VERSION ""

NS_ :

BS_:

BU_:
VAL_TABLE_ Sig0084 0 "2000" 1 "2001" 2 "2002" 3 "2003" 4 "2004" 5 "2005" 6 "2006" 7 "2007" 8 "2008" 9 "2009" 10 "2010" 11 "2011" 12 "2012" 13 "2013" 14 "2014" 15 "2015" 16 "2016" 17 "2017" 18 "2018" 19 "2019" 20 "2020" 21 "2021" 22 "2022" 23 "2023" 24 "2024" 25 "2025" 26 "2026" 27 "2027" 28 "2028" 29 "2029" 30 "2030" 31 "2031" 32 "2032" 33 "2033" 34 "2034" 35 "2035" 36 "2036" 37 "2037" 38 "2038" 39 "2039" 40 "2040" 41 "2041" 42 "2042" 43 "2043" 44 "2044" 45 "2045" 46 "2046" 47 "2047" 48 "2048" 49 "2049" 50 "2050" 51 "2051" 52 "2052" 53 "2053" 54 "2054" 55 "2055" 56 "2056" 57 "2057" 58 "2058" 59 "2059" 60 "2060" 61 "2061" 62 "2062" 63 "NOT APPLICABLE" ;
VAL_TABLE_ Sig0079 0 "UNKNOWN" 1 "<= 5 KM/H [MPH]" 2 "7 KM/H [MPH]" 3 "10 KM/H [MPH]" 4 "15 KM/H [MPH]" 5 "20 KM/H [MPH]" 6 "25 KM/H [MPH]" 7 "30 KM/H [MPH]" 8 "35 KM/H [MPH]" 9 "40 KM/H [MPH]" 10 "45 KM/H [MPH]" 11 "50 KM/H [MPH]" 12 "55 KM/H [MPH]" 13 "60 KM/H" 14 "MPH]65 KM/H [MPH]" 15 "70 KM/H [MPH]" 16 "75 KM/H [MPH]" 17 "80 KM/H [MPH]" 18 "85 KM/H [MPH]" 19 "90 KM/H [MPH]" 20 "95 KM/H [MPH]" 21 "100 KM/H [MPH]" 22 "105 KM/H [MPH]" 23 "110 KM/H [MPH]" 24 "115 KM/H [MPH]" 25 "120 KM/H[MPH]" 26 "130 KM/H [MPH]" 27 "140 KM/H [MPH]" 28 "150 KM/H [MPH]" 29 "160 KM/H [MPH]" 30 "UNLIMITED" 31 "NOT AVAILABLE" ;
VAL_TABLE_ Sig0078 0 "> 130 KPH OR > 80 MPH" 1 "101-130 KPH OR 65\???80 MPH" 2 "91-100 KPH OR 55\???64 MPH" 3 "71-90 KPH OR 41\???54 MPH" 4 "51-70 KPH OR 31\???40 MPH" 5 "31-50 KPH OR 21\???30 MPH" 6 "11-30 KPH OR 6 \???20 MPH" 7 "<11 KPH OR < 6 MPH" 8 "UNKNOWN" ;
VAL_TABLE_ Sig0083 0 "QUARTER 1" 1 "QUARTER 2" 2 "QUARTER 3" 3 "QUARTER 4" ;
VAL_TABLE_ ADASIS_NAVILINK_FncRdClss 0 "LOCAL" 1 "SFREEWAY" 2 "FREEWAY" 3 "PED-MALL" 4 "HIGHWAY" 5 "ARTERIAL" 6 "ALLEY" 7 "COLLECTOR" ;
VAL_TABLE_ Sig0081 0 "IMPLICIT" 1 "ON TRAFFIC SIGN" 2 "ONLY BY NIGHT" 3 "ONLY BY DAY" 4 "TIME OF DAY" 5 "ONLY BY RAIN" 6 "ONLY BY SNOW OR FOG" 7 "UNKOWN" ;
VAL_TABLE_ Sig0090 0 "ROAD IS NOT CONTROLLED ACCESS ROAD" 1 "ROAD IS CONTROLLED ACCESS ROAD" ;
VAL_TABLE_ Sig0089 0 "MILES/H" 1 "KM/H" ;
VAL_TABLE_ ADASIS_NAVILINK_MpDtAv 0 "NOT VALID" 1 "VALID" ;
VAL_TABLE_ Sig0082 0 "NOT ASSURED" 1 "ASSURED" ;
VAL_TABLE_ Sig0080 0 "DRIVING SIDE LEFT" 1 "DRIVING SIDE RIGHT" ;
VAL_TABLE_ Sig0085 0 "NO INFO AVAILABLE" 1 "ONE LANE" 2 "TWO OR THREE LANES" 3 "FOUR OR MORE LANES" ;
VAL_TABLE_ HVWrlsChrgStopReqd 0 "FALSE" 1 "TRUE" ;
VAL_TABLE_ HVWrlsChrgWiFiConctSts 0 "Unknown" 1 "Connected" 2 "Lost" ;
VAL_TABLE_ HVWrlsChrgSysFltSts 0 "No Fault" 1 "Over Voltage" 2 "Under Voltage" 3 "Overload" 4 "Over Temperature" 5 "Lost of Wifi Communication" 6 "Lost of CAN Communication" ;
VAL_TABLE_ HVWrlsChrgLivngObjDtd 0 "FALSE" 1 "TRUE" ;
VAL_TABLE_ HVWrlsChrgFrgnObjDtd 0 "FALSE" 1 "TRUE" ;
VAL_TABLE_ HVWrlsChrgRctfrTemp_Inv 0 "FALSE" 1 "TRUE" ;
VAL_TABLE_ HVWrlsChrgVehCoilTempA_Inv 0 "FALSE" 1 "TRUE" ;
VAL_TABLE_ HVWrlsChrgVehCoilTempB_Inv 0 "FALSE" 1 "TRUE" ;
VAL_TABLE_ HVWrlsChrgIntopbltCkSts 0 "Unknown" 1 "Pass" 2 "Fail" ;
VAL_TABLE_ HVWrlsChrgIntopbltCkFldRsn 0 "None" 1 "Wrong Charging Protocol" 2 "Unidentified Equipment" ;
VAL_TABLE_ HVWrlsChrgACGridPwr_Inv 0 "FALSE" 1 "TRUE" ;
VAL_TABLE_ HVWrlsChrgDCOutCurr_Inv 0 "FALSE" 1 "TRUE" ;
VAL_TABLE_ HVWrlsChrgSysCurrLim_Inv 0 "FALSE" 1 "TRUE" ;
VAL_TABLE_ HVWrlsChrgDCOutVltg_Inv 0 "FALSE" 1 "TRUE" ;
VAL_TABLE_ HVWrlsChrgAlgnCkRespVal_Inv 0 "FALSE" 1 "TRUE" ;
VAL_TABLE_ HVWrlsChrgSysStat 0 "Wireless Charging Inactive" 1 "Wireless Charging Pairing" 2 "Wireless Charging Standby" 3 "Wireless Charging Ready" 4 "Wireless Charging" 5 "Wireless Charging Complete" 6 "Wireless Charging Terminated" ;
VAL_TABLE_ Sig3479 0 "TOWN" 1 "COUNTRY ROAD" 2 "MOTORWAY" 3 "RESERVED1" 4 "RESERVED2" 5 "RESERVED3" 6 "RESERVED 4" 7 "UNDEFINED" ;
VAL_TABLE_ Sig3477 0 "UNKNOWN" 1 "NOT BLOCKED" 2 "FULL BLOCKAGE" 3 "PARTIAL BLOCKAGE" 4 "RESERVED3" 5 "RESERVED4" 6 "RESERVED5" 7 "RESERVED6" ;
VAL_TABLE_ Sig3476 0 "CLEAR WEATHER" 1 "LIGHT FOG" 2 "MEDIUM FOG" 3 "HEAVY FOG" 4 "LIGHT SNOW" 5 "MEDIUM SNOW" 6 "HEAVY SNOW" 7 "LIGHT RAIN" 8 "MEDIUM RAIN" 9 "HEAVY RAIN" ;
VAL_TABLE_ Sig3508 0 "OFF" 1 "AHBA" 2 "GFHB" ;
VAL_TABLE_ Sig3478 0 "UNKNOWN" 1 "LIT ENVIRONMENT DURING NIGHT" 2 "UNLIT ENVIRONMENT DURING NIGHT" 3 "DAYLIGHT" ;
VAL_TABLE_ Sig7678 0 "FALSE" 1 "TRUE" ;
VAL_TABLE_ Sig7675 0 "FALSE" 1 "TRUE" ;
VAL_TABLE_ Sig7674 0 "FALSE" 1 "TRUE" ;
VAL_TABLE_ Sig7673 0 "FALSE" 1 "TRUE" ;
VAL_TABLE_ Sig7672 0 "FALSE" 1 "TRUE" ;
VAL_TABLE_ Sig7671 0 "FALSE" 1 "TRUE" ;
VAL_TABLE_ Sig7670 0 "FALSE" 1 "TRUE" ;
VAL_TABLE_ Sig7669 0 "FALSE" 1 "TRUE" ;
VAL_TABLE_ Sig7686 0 "FALSE" 1 "TRUE" ;
VAL_TABLE_ Sig7685 0 "FALSE" 1 "TRUE" ;
VAL_TABLE_ Sig7684 0 "FALSE" 1 "TRUE" ;
VAL_TABLE_ Sig7683 0 "FALSE" 1 "TRUE" ;
VAL_TABLE_ Sig7682 0 "FALSE" 1 "TRUE" ;
VAL_TABLE_ Sig7681 0 "FALSE" 1 "TRUE" ;
VAL_TABLE_ Sig7680 0 "FALSE" 1 "TRUE" ;
VAL_TABLE_ TrfcSgnMemOfstEnbld 0 "FALSE" 1 "TRUE" ;
VAL_TABLE_ Sig7698 0 "FALSE" 1 "TRUE" ;
VAL_TABLE_ Sig7697 0 "FALSE" 1 "TRUE" ;
VAL_TABLE_ Sig7696 0 "FALSE" 1 "TRUE" ;
VAL_TABLE_ Sig7695 0 "FALSE" 1 "TRUE" ;
VAL_TABLE_ Sig7694 0 "FALSE" 1 "TRUE" ;
VAL_TABLE_ Sig7693 0 "FALSE" 1 "TRUE" ;
VAL_TABLE_ Sig7692 0 "FALSE" 1 "TRUE" ;
VAL_TABLE_ Sig7688 0 "FALSE" 1 "TRUE" ;
VAL_TABLE_ Sig7699 0 "FALSE" 1 "TRUE" ;
VAL_TABLE_ Sig7687 0 "No Action" 1 "Off" 2 "On" ;
VAL_TABLE_ Sig7676 0 "No Action" 1 "Off" 2 "On" ;
VAL_TABLE_ Sig7667 0 "No Action" 1 "Off" 2 "On" ;
VAL_TABLE_ Sig7691 0 "No Action" 1 "Active" 2 "Cancel Chime" ;
VAL_TABLE_ Sig7689 0 "No Action" 1 "Active" 2 "Cancel Chime" ;
VAL_TABLE_ Sig7677 0 "Setting Unknown" 1 "Off" 2 "On" ;
VAL_TABLE_ Sig7668 0 "Setting Unknown" 1 "Off" 2 "On" ;
VAL_TABLE_ Sig7666 0 "Setting Unknown" 1 "Off" 2 "On" ;
VAL_TABLE_ Sig7690 0 "FALSE" 1 "TRUE" ;
VAL_TABLE_ Sig7679 0 "FALSE" 1 "TRUE" ;
VAL_TABLE_ ACCompNormLd_Inv 0 "FALSE" 1 "TRUE" ;
VAL_TABLE_ OutsdAmbtLgtLvl_Inv 0 "FALSE" 1 "TRUE" ;
VAL_TABLE_ OutsdAmbtLgtLvl_DuD 0 "FALSE" 1 "TRUE" ;
VAL_TABLE_ PFMinIdlBsRq 0 "NO IDLE BOOST REQUESTED" 1 "BOOST LEVEL 1" 2 "BOOST LEVEL 2" 3 "BOOST LEVEL 3" 4 "BOOST LEVEL 4(NEW REQUEST)" ;
VAL_TABLE_ StBltShfIntlkReqSts 0 "Driver Seatbelt Shift Interlock Active" 1 "Passenger Seatbelt Shift Interlock Active" 2 "Seatbelt Shift Interlock Inactive" 3 "Seatbelt Shift Interlock Override Expired" ;
VAL_TABLE_ LDWCtrlSwSts 0 "Not Pressed" 1 "Pressed" 2 "Fault" 3 "Unknown" ;
VAL_TABLE_ EE46ecGridVltgOvrrdPrty 0 "None" 1 "Low" 2 "Medium" 3 "High" ;
VAL_TABLE_ ACCompModReq 0 "Disengage Immediately" 1 "Disengage" 2 "Engage" 3 "No Action" ;
VAL_TABLE_ FOPPriGridOvrrdActv 0 "FALSE" 1 "TRUE" ;
VAL_TABLE_ EPMGridIsltnReqd 0 "FALSE" 1 "TRUE" ;
VAL_TABLE_ ClntCircPmpRq 0 "Off" 1 "On" ;
VAL_TABLE_ ClmtCtrlHtrEngRunRq 0 "No Action" 1 "Engine Run Requested" ;
VAL_TABLE_ BdyCtrlEmsRltMlfAtv 0 "FALSE" 1 "TRUE" ;
VAL_TABLE_ ACCmpsrFldOn 0 "FALSE" 1 "TRUE" ;
VAL_TABLE_ ACCmEngRunReq 0 "No Action" 1 "Engine Run Requested" ;
VAL_TABLE_ PlatEngSpdCmdSysTyp 0 "No Platform Eng Speed Command Sys" 1 "Power Take Off" 2 "Reserved" ;
VAL_TABLE_ LdMeToCarActv 0 "FALSE" 1 "TRUE" ;
VAL_TABLE_ IBS12VBatCurrExtndRng_Inv 0 "FALSE" 1 "TRUE" ;
VAL_TABLE_ IBS12VEstdBatTemp_Inv 0 "FALSE" 1 "TRUE" ;
VAL_TABLE_ IBSIntrnlFltPr_Inv 0 "FALSE" 1 "TRUE" ;
VAL_TABLE_ IBSIntrnlFltPr 0 "FALSE" 1 "TRUE" ;
VAL_TABLE_ BCERDTC_SysDes 0 "P0_Powertrain Codes SAE Controlled" 1 "P1_Powertrain Codes MFG Controlled" 2 "P2_Powertrain Codes Reserved" 3 "P3_Powertrain Codes Reserved" 4 "C0_Chassis Codes SAE Controlled" 5 "C1_Chassis Codes MFG Controlled" 6 "C2_Chassis Codes Reserved" 7 "C3_Chassis Codes Reserved" 8 "B0_Body Codes SAE Controlled" 9 "B1_Body Codes MFG Controlled" 10 "B2_Body Codes Reserved" 11 "B3_Body Codes Reserved" 12 "U0_Network Codes SAE Controlled" 13 "U1_Network Codes MFG Controlled" 14 "U2_Network Codes Reserved" 15 "U3_Network Codes Reserved" ;
VAL_TABLE_ EngOffTmExtndRng_Inv 0 "FALSE" 1 "TRUE" ;
VAL_TABLE_ EnhdElpsdTmCntDgrd 0 "FALSE" 1 "TRUE" ;
VAL_TABLE_ ElpsdTimeCntRstOcc 0 "FALSE" 1 "TRUE" ;
VAL_TABLE_ TrnstStrgLogisticsMdActivation 0 "FALSE" 1 "TRUE" ;
VAL_TABLE_ RstrctdPwrtrnOpModeReqd 0 "FALSE" 1 "TRUE" ;
VAL_TABLE_ PrtctdIdlShftrLckReq 0 "FALSE" 1 "TRUE" ;
VAL_TABLE_ FgLmpFrtFncActv 0 "FALSE" 1 "TRUE" ;
VAL_TABLE_ ExtLgtChrgphyFrtActvn 0 "No Animation" 1 "Animation 1" 2 "Animation 2" 3 "Animation 3" 4 "Animation 4" 5 "Animation 5" 6 "Animation 6" ;
VAL_TABLE_ IBS12VBatVlt_Inv 0 "FALSE" 1 "TRUE" ;
VAL_TABLE_ BGI5_TrnLmpLtOtgDtd 0 "FALSE" 1 "TRUE" ;
VAL_TABLE_ BGI5_TrnLmpLtFncActv 0 "FALSE" 1 "TRUE" ;
VAL_TABLE_ BGI5_TrnLmpRtOtgDtd 0 "FALSE" 1 "TRUE" ;
VAL_TABLE_ BGI5_TrnLmpRtFncActv 0 "FALSE" 1 "TRUE" ;
VAL_TABLE_ PerfTracMgmtModeSwSts 0 "Not Supported" 1 "No Activation" 2 "Increment" 3 "Decrement" 4 "Faulted" ;
VAL_TABLE_ AirDflctrSysStat 0 "Unknown Position" 1 "Stowed Position" 2 "Drag Lowered Position" 3 "Drag Raised Position" 4 "Tow Haul Position" 5 "Brake Cooling Position" ;
VAL_TABLE_ PIMRI_BCM_PrmntDTCInd 0 "FALSE" 1 "TRUE" ;
VAL_TABLE_ PIMRI_BCM_FltsPrsntInd 0 "FALSE" 1 "TRUE" ;
VAL_TABLE_ LDWCtrlSelctdStatRaw 0 "PRESSED" 1 "NOT PRESSED" 2 "UNKNOWN" ;
VAL_TABLE_ DrvDrAjrStat 0 "FALSE" 1 "TRUE" ;
VAL_TABLE_ DrvDrAjrStat_Inv 0 "FALSE" 1 "TRUE" ;
VAL_TABLE_ AE44SeltdStatRw 0 "Not Pressed" 1 "Pressed" 2 "Unknown" 3 "Failed" ;
VAL_TABLE_ WshldWshFtrActv 0 "FALSE" 1 "TRUE" ;
VAL_TABLE_ WprFrActUnfltdStat 0 "FALSE" 1 "TRUE" ;
VAL_TABLE_ WprFrActFltdStat 0 "FALSE" 1 "TRUE" ;
VAL_TABLE_ EnhdDrvrSeltdMdSwChsUseActv 0 "FALSE" 1 "TRUE" ;
VAL_TABLE_ VehDynMdSwAct 0 "FALSE" 1 "TRUE" ;
VAL_TABLE_ VehDynMdSwAct_Inv 0 "FALSE" 1 "TRUE" ;
VAL_TABLE_ PerfTracMgmtActvnConfSts 0 "No Action" 1 "PTM Confirmed" 2 "Cancel PTM Request" ;
VAL_TABLE_ TrnSigSwRtActv 0 "FALSE" 1 "TRUE" ;
VAL_TABLE_ TrnSigSwLtActv 0 "FALSE" 1 "TRUE" ;
VAL_TABLE_ PrkBrkSwAtv 0 "FALSE" 1 "TRUE" ;
VAL_TABLE_ BrkLtsAtv 0 "FALSE" 1 "TRUE" ;
VAL_TABLE_ RatlzdEVDCCompVlvLSDCurrFbk_Inv 0 "FALSE" 1 "TRUE" ;
VAL_TABLE_ CustmModePwrtrnStrdPerfMode 0 "Unknown" 1 "Normal" 2 "Powertrain Sport" 3 "Chassis Sport" 4 "Eco" 5 "Mountain" 6 "Hold" 7 "Snow Ice" 8 "Start Stop" 9 "Tow Haul" 10 "Grade Braking Disabled" 11 "Speed Matching" 12 "Track" 13 "Exhaust Brake" 14 "Normal AWD" ;
VAL_TABLE_ PltfTrnsTUDSwSt 0 "No Activation" 1 "Increment Switch Active" 2 "Decrement Switch Active" 3 "Illegal Up/Down Switch State Active" ;
VAL_TABLE_ PltfTrnsTUDSecSwSt 0 "No Activation" 1 "Increment Switch Active" 2 "Decrement Switch Active" 3 "Illegal Up/Down Switch State Active" ;
VAL_TABLE_ LIBCfg 0 "Not supported" 1 "LIB1" 2 "LIB2" ;
VAL_TABLE_ ShftFrmPrkAlwd 0 "FALSE" 1 "TRUE" ;
VAL_TABLE_ DrvrElecVehModeCmnd 0 "FALSE" 1 "TRUE" ;
VAL_TABLE_ DM1Unavailable 0 "FALSE" 1 "TRUE" ;
VAL_TABLE_ DM1Status 0 "Inactive" 1 "Active" ;
VAL_TABLE_ DM1Pending 0 "FALSE" 1 "TRUE" ;
VAL_TABLE_ DM1Name 0 "None" 1 "Tour" 2 "Sport" 3 "Track" 4 "Winter" 5 "Off Road" 6 "Tow/Haul" 7 "Hold" 8 "Mountain" 9 "Personal" 10 "Custom" 11 "AWD" 12 "Economy" 13 "Automatic" 14 "EV" 15 "grade braking" 16 "exhaust brake" 17 "active rev match" 18 "2WD" 19 "Comfort" 20 "start/stop disable" 21 "Crawl" 22 "Charge Plus" 23 "Baja" 24 "Max Power" 25 "Reserved 1 - Reserved 7" ;
VAL_TABLE_ DM2Unavailable 0 "FALSE" 1 "TRUE" ;
VAL_TABLE_ DM2Status 0 "Inactive" 1 "Active" ;
VAL_TABLE_ DM2Pending 0 "FALSE" 1 "TRUE" ;
VAL_TABLE_ DM2Name 0 "None" 1 "Tour" 2 "Sport" 3 "Track" 4 "Winter" 5 "Off Road" 6 "Tow/Haul" 7 "Hold" 8 "Mountain" 9 "Personal" 10 "Custom" 11 "AWD" 12 "Economy" 13 "Automatic" 14 "EV" 15 "grade braking" 16 "exhaust brake" 17 "active rev match" 18 "2WD" 19 "Comfort" 20 "start/stop disable" 21 "Crawl" 22 "Charge Plus" 23 "Baja" 24 "Max Power" 25 "Reserved 1 - Reserved 7" ;
VAL_TABLE_ DM3Unavailable 0 "FALSE" 1 "TRUE" ;
VAL_TABLE_ DM3Status 0 "Inactive" 1 "Active" ;
VAL_TABLE_ DM3Pending 0 "FALSE" 1 "TRUE" ;
VAL_TABLE_ DM3Name 0 "None" 1 "Tour" 2 "Sport" 3 "Track" 4 "Winter" 5 "Off Road" 6 "Tow/Haul" 7 "Hold" 8 "Mountain" 9 "Personal" 10 "Custom" 11 "AWD" 12 "Economy" 13 "Automatic" 14 "EV" 15 "grade braking" 16 "exhaust brake" 17 "active rev match" 18 "2WD" 19 "Comfort" 20 "start/stop disable" 21 "Crawl" 22 "Charge Plus" 23 "Baja" 24 "Max Power" 25 "Reserved 1 - Reserved 7" ;
VAL_TABLE_ DM4Unavailable 0 "FALSE" 1 "TRUE" ;
VAL_TABLE_ DM4Status 0 "Inactive" 1 "Active" ;
VAL_TABLE_ DM4Pending 0 "FALSE" 1 "TRUE" ;
VAL_TABLE_ DM4Name 0 "None" 1 "Tour" 2 "Sport" 3 "Track" 4 "Winter" 5 "Off Road" 6 "Tow/Haul" 7 "Hold" 8 "Mountain" 9 "Personal" 10 "Custom" 11 "AWD" 12 "Economy" 13 "Automatic" 14 "EV" 15 "grade braking" 16 "exhaust brake" 17 "active rev match" 18 "2WD" 19 "Comfort" 20 "start/stop disable" 21 "Crawl" 22 "Charge Plus" 23 "Baja" 24 "Max Power" 25 "Reserved 1 - Reserved 7" ;
VAL_TABLE_ DM5Unavailable 0 "FALSE" 1 "TRUE" ;
VAL_TABLE_ DM5Status 0 "Inactive" 1 "Active" ;
VAL_TABLE_ DM5Pending 0 "FALSE" 1 "TRUE" ;
VAL_TABLE_ DM5Name 0 "None" 1 "Tour" 2 "Sport" 3 "Track" 4 "Winter" 5 "Off Road" 6 "Tow/Haul" 7 "Hold" 8 "Mountain" 9 "Personal" 10 "Custom" 11 "AWD" 12 "Economy" 13 "Automatic" 14 "EV" 15 "grade braking" 16 "exhaust brake" 17 "active rev match" 18 "2WD" 19 "Comfort" 20 "start/stop disable" 21 "Crawl" 22 "Charge Plus" 23 "Baja" 24 "Max Power" 25 "Reserved 1 - Reserved 7" ;
VAL_TABLE_ DM6Unavailable 0 "FALSE" 1 "TRUE" ;
VAL_TABLE_ DM6Status 0 "Inactive" 1 "Active" ;
VAL_TABLE_ DM6Pending 0 "FALSE" 1 "TRUE" ;
VAL_TABLE_ DM6Name 0 "None" 1 "Tour" 2 "Sport" 3 "Track" 4 "Winter" 5 "Off Road" 6 "Tow/Haul" 7 "Hold" 8 "Mountain" 9 "Personal" 10 "Custom" 11 "AWD" 12 "Economy" 13 "Automatic" 14 "EV" 15 "grade braking" 16 "exhaust brake" 17 "active rev match" 18 "2WD" 19 "Comfort" 20 "start/stop disable" 21 "Crawl" 22 "Charge Plus" 23 "Baja" 24 "Max Power" 25 "Reserved 1 - Reserved 7" ;
VAL_TABLE_ DM7Unavailable 0 "FALSE" 1 "TRUE" ;
VAL_TABLE_ DM7Status 0 "Inactive" 1 "Active" ;
VAL_TABLE_ DM7Pending 0 "FALSE" 1 "TRUE" ;
VAL_TABLE_ DM7Name 0 "None" 1 "Tour" 2 "Sport" 3 "Track" 4 "Winter" 5 "Off Road" 6 "Tow/Haul" 7 "Hold" 8 "Mountain" 9 "Personal" 10 "Custom" 11 "AWD" 12 "Economy" 13 "Automatic" 14 "EV" 15 "grade braking" 16 "exhaust brake" 17 "active rev match" 18 "2WD" 19 "Comfort" 20 "start/stop disable" 21 "Crawl" 22 "Charge Plus" 23 "Baja" 24 "Max Power" 25 "Reserved 1 - Reserved 7" ;
VAL_TABLE_ DM8Unavailable 0 "FALSE" 1 "TRUE" ;
VAL_TABLE_ DM8Status 0 "Inactive" 1 "Active" ;
VAL_TABLE_ DM8Pending 0 "FALSE" 1 "TRUE" ;
VAL_TABLE_ DM8Name 0 "None" 1 "Tour" 2 "Sport" 3 "Track" 4 "Winter" 5 "Off Road" 6 "Tow/Haul" 7 "Hold" 8 "Mountain" 9 "Personal" 10 "Custom" 11 "AWD" 12 "Economy" 13 "Automatic" 14 "EV" 15 "grade braking" 16 "exhaust brake" 17 "active rev match" 18 "2WD" 19 "Comfort" 20 "start/stop disable" 21 "Crawl" 22 "Charge Plus" 23 "Baja" 24 "Max Power" 25 "Reserved 1 - Reserved 7" ;
VAL_TABLE_ BatVlt_Inv 0 "FALSE" 1 "TRUE" ;
VAL_TABLE_ BattCrntFltrd_Inv 0 "FALSE" 1 "TRUE" ;
VAL_TABLE_ BattCrntFltrd_DuD 0 "FALSE" 1 "TRUE" ;
VAL_TABLE_ Sig4411 0 "FALSE" 1 "TRUE" ;
VAL_TABLE_ NodeStsADIMb_CAN_9_LcFA 0 "FALSE" 1 "TRUE" ;
VAL_TABLE_ NodeStsADIMb_CAN_3_LcFA 0 "FALSE" 1 "TRUE" ;
VAL_TABLE_ NodeStsADIMb_CAN_2_LcFA 0 "FALSE" 1 "TRUE" ;
VAL_TABLE_ NodeStsADIMb_CAN_10_LcFA 0 "FALSE" 1 "TRUE" ;
VAL_TABLE_ NodeStsADIMa_CAN_9_LcFA 0 "FALSE" 1 "TRUE" ;
VAL_TABLE_ NodeStsADIMa_CAN_3_LcFA 0 "FALSE" 1 "TRUE" ;
VAL_TABLE_ NodeStsADIMa_CAN_2_LcFA 0 "FALSE" 1 "TRUE" ;
VAL_TABLE_ NodeStsADIMa_CAN_10_LcFA 0 "FALSE" 1 "TRUE" ;
VAL_TABLE_ NodeStsAE44_CAN_1_LcFA 0 "FALSE" 1 "TRUE" ;
VAL_TABLE_ NodeStsE5_LcFA 0 "FALSE" 1 "TRUE" ;
VAL_TABLE_ NodeStsAMP_LcFA 0 "FALSE" 1 "TRUE" ;
VAL_TABLE_ NodeStsALC_LcFA 0 "FALSE" 1 "TRUE" ;
VAL_TABLE_ NodeStsAHS_LcFA 0 "FALSE" 1 "TRUE" ;
VAL_TABLE_ NodeStsAHL_AFL_CAN_2_LcFA 0 "FALSE" 1 "TRUE" ;
VAL_TABLE_ NodeStsAGC_LcFA 0 "FALSE" 1 "TRUE" ;
VAL_TABLE_ NodeStsBSM_MH_LcFA 0 "FALSE" 1 "TRUE" ;
VAL_TABLE_ NodeStsBSM_CAN_3_LcFA 0 "FALSE" 1 "TRUE" ;
VAL_TABLE_ NodeStsBSM_CAN_2_LcFA 0 "FALSE" 1 "TRUE" ;
VAL_TABLE_ NodeStsBCM_LcFA 0 "FALSE" 1 "TRUE" ;
VAL_TABLE_ NodeStsARS_LcFA 0 "FALSE" 1 "TRUE" ;
VAL_TABLE_ NodeStsE8_LcFA 0 "FALSE" 1 "TRUE" ;
VAL_TABLE_ NodeStsAE44_CAN_2_LcFA 0 "FALSE" 1 "TRUE" ;
VAL_TABLE_ NodeStsEBCM_AV_CAN_2_LcFA 0 "FALSE" 1 "TRUE" ;
VAL_TABLE_ NodeStsDMS_LcFA 0 "FALSE" 1 "TRUE" ;
VAL_TABLE_ NodeStsE12_LcFA 0 "FALSE" 1 "TRUE" ;
VAL_TABLE_ NodeStsDCM_LcFA 0 "FALSE" 1 "TRUE" ;
VAL_TABLE_ NodeStsCSM_CAN_5_LcFA 0 "FALSE" 1 "TRUE" ;
VAL_TABLE_ NodeStsECP_E_CAN_9_LcFA 0 "FALSE" 1 "TRUE" ;
VAL_TABLE_ NodeStsECP_E_CAN_2_LcFA 0 "FALSE" 1 "TRUE" ;
VAL_TABLE_ NodeStsECM_CAN_3_LcFA 0 "FALSE" 1 "TRUE" ;
VAL_TABLE_ NodeStsECM_CAN_2_LcFA 0 "FALSE" 1 "TRUE" ;
VAL_TABLE_ NodeStsEBCM_CAN_3_LcFA 0 "FALSE" 1 "TRUE" ;
VAL_TABLE_ NodeStsEBCM_CAN_2_LcFA 0 "FALSE" 1 "TRUE" ;
VAL_TABLE_ NodeStsEBCM_AV_CAN_3_LcFA 0 "FALSE" 1 "TRUE" ;
VAL_TABLE_ NodeStsEOCM_CAN_3_LcFA 0 "FALSE" 1 "TRUE" ;
VAL_TABLE_ NodeStsEOCM_CAN_2_LcFA 0 "FALSE" 1 "TRUE" ;
VAL_TABLE_ NodeStsELM_LcFA 0 "FALSE" 1 "TRUE" ;
VAL_TABLE_ NodeStsECP_X1_CAN_3_LcFA 0 "FALSE" 1 "TRUE" ;
VAL_TABLE_ NodeStsECP_X1_CAN_2_LcFA 0 "FALSE" 1 "TRUE" ;
VAL_TABLE_ NodeStsECP_S_CAN_9_LcFA 0 "FALSE" 1 "TRUE" ;
VAL_TABLE_ NodeStsECP_S_CAN_2_LcFA 0 "FALSE" 1 "TRUE" ;
VAL_TABLE_ NodeStsECP_MC_LcFA 0 "FALSE" 1 "TRUE" ;
VAL_TABLE_ NodeStsEPSRAa_LcFA 0 "FALSE" 1 "TRUE" ;
VAL_TABLE_ NodeStsEPS_LcFA 0 "FALSE" 1 "TRUE" ;
VAL_TABLE_ NodeStsE19_LcFA 0 "FALSE" 1 "TRUE" ;
VAL_TABLE_ NodeStsEOCM_HCP2_LcFA 0 "FALSE" 1 "TRUE" ;
VAL_TABLE_ NodeStsEOCM_HCP1_CAN_8_LcFA 0 "FALSE" 1 "TRUE" ;
VAL_TABLE_ NodeStsEOCM_HCP1_CAN_3_LcFA 0 "FALSE" 1 "TRUE" ;
VAL_TABLE_ NodeStsEOCM_HCP1_CAN_2_LcFA 0 "FALSE" 1 "TRUE" ;
VAL_TABLE_ NodeStsEOCM_CAN_8_LcFA 0 "FALSE" 1 "TRUE" ;
VAL_TABLE_ NodeStsHVAC_FP_F_LcFA 0 "FALSE" 1 "TRUE" ;
VAL_TABLE_ NodeStsHUD_CAN_LcFA 0 "FALSE" 1 "TRUE" ;
VAL_TABLE_ NodeStsE22_LcFA 0 "FALSE" 1 "TRUE" ;
VAL_TABLE_ NodeStsFOPM_CAN_3_LcFA 0 "FALSE" 1 "TRUE" ;
VAL_TABLE_ NodeStsFOPM_CAN_2_LcFA 0 "FALSE" 1 "TRUE" ;
VAL_TABLE_ NodeStsFCM_LcFA 0 "FALSE" 1 "TRUE" ;
VAL_TABLE_ NodeStsFCM_LC_LcFA 0 "FALSE" 1 "TRUE" ;
VAL_TABLE_ NodeStsE20_LcFA 0 "FALSE" 1 "TRUE" ;
VAL_TABLE_ NodeStsMFC_LcFA 0 "FALSE" 1 "TRUE" ;
VAL_TABLE_ NodeStsLRR_LcFA 0 "FALSE" 1 "TRUE" ;
VAL_TABLE_ NodeStsLIB1_LcFA 0 "FALSE" 1 "TRUE" ;
VAL_TABLE_ NodeStsIPC_CAN_5_LcFA 0 "FALSE" 1 "TRUE" ;
VAL_TABLE_ NodeStsICS_Info_LcFA 0 "FALSE" 1 "TRUE" ;
VAL_TABLE_ NodeStsICCM_CAN_3_LcFA 0 "FALSE" 1 "TRUE" ;
VAL_TABLE_ NodeStsHVAC_FP_R_LcFA 0 "FALSE" 1 "TRUE" ;
VAL_TABLE_ NodeStsE38_LcFA 0 "FALSE" 1 "TRUE" ;
VAL_TABLE_ NodeStsE37_LcFA 0 "FALSE" 1 "TRUE" ;
VAL_TABLE_ NodeStsE36_LcFA 0 "FALSE" 1 "TRUE" ;
VAL_TABLE_ NodeStsE35_LcFA 0 "FALSE" 1 "TRUE" ;
VAL_TABLE_ NodeStsE34_LcFA 0 "FALSE" 1 "TRUE" ;
VAL_TABLE_ NodeStsE33_LcFA 0 "FALSE" 1 "TRUE" ;
VAL_TABLE_ NodeStsE32_LcFA 0 "FALSE" 1 "TRUE" ;
VAL_TABLE_ NodeStsE31_LcFA 0 "FALSE" 1 "TRUE" ;
VAL_TABLE_ NodeStsRDCM_LcFA 0 "FALSE" 1 "TRUE" ;
VAL_TABLE_ NodeStsRadioLow_LcFA 0 "FALSE" 1 "TRUE" ;
VAL_TABLE_ NodeStsE48_LcFA 0 "FALSE" 1 "TRUE" ;
VAL_TABLE_ NodeStsPDR_LcFA 0 "FALSE" 1 "TRUE" ;
VAL_TABLE_ NodeStsE44_LcFA 0 "FALSE" 1 "TRUE" ;
VAL_TABLE_ NodeStsNVM_LcFA 0 "FALSE" 1 "TRUE" ;
VAL_TABLE_ NodeStsE40_LcFA 0 "FALSE" 1 "TRUE" ;
VAL_TABLE_ NodeStsE39_LcFA 0 "FALSE" 1 "TRUE" ;
VAL_TABLE_ Sig4413 0 "FALSE" 1 "TRUE" ;
VAL_TABLE_ NodeStsE53_LcFA 0 "FALSE" 1 "TRUE" ;
VAL_TABLE_ NodeStsE52_LcFA 0 "FALSE" 1 "TRUE" ;
VAL_TABLE_ NodeStsE51_LcFA 0 "FALSE" 1 "TRUE" ;
VAL_TABLE_ NodeStsE50_LcFA 0 "FALSE" 1 "TRUE" ;
VAL_TABLE_ NodeStsSADS_LcFA 0 "FALSE" 1 "TRUE" ;
VAL_TABLE_ NodeStsRSC_LcFA 0 "FALSE" 1 "TRUE" ;
VAL_TABLE_ NodeStsSRR_RF_LcFA 0 "FALSE" 1 "TRUE" ;
VAL_TABLE_ NodeStsSRR_LR_CR_LcFA 0 "FALSE" 1 "TRUE" ;
VAL_TABLE_ NodeStsSRR_LF_LcFA 0 "FALSE" 1 "TRUE" ;
VAL_TABLE_ NodeStsSIB_LcFA 0 "FALSE" 1 "TRUE" ;
VAL_TABLE_ NodeStsSDM_LcFA 0 "FALSE" 1 "TRUE" ;
VAL_TABLE_ NodeStsE56_LcFA 0 "FALSE" 1 "TRUE" ;
VAL_TABLE_ NodeStsE55_LcFA 0 "FALSE" 1 "TRUE" ;
VAL_TABLE_ NodeStsE54_LcFA 0 "FALSE" 1 "TRUE" ;
VAL_TABLE_ NodeStsTCP_CAN_5_LcFA 0 "FALSE" 1 "TRUE" ;
VAL_TABLE_ NodeStsTCM_CAN_2_LcFA 0 "FALSE" 1 "TRUE" ;
VAL_TABLE_ NodeStsTCCM_LcFA 0 "FALSE" 1 "TRUE" ;
VAL_TABLE_ NodeStsE57_LcFA 0 "FALSE" 1 "TRUE" ;
VAL_TABLE_ NodeStsSRR_SRR_LcFA 0 "FALSE" 1 "TRUE" ;
VAL_TABLE_ NodeStsSRR_SLR_LcFA 0 "FALSE" 1 "TRUE" ;
VAL_TABLE_ NodeStsSRR_RR_LcFA 0 "FALSE" 1 "TRUE" ;
VAL_TABLE_ NodeStsWCM_LcFA 0 "FALSE" 1 "TRUE" ;
VAL_TABLE_ NodeStsE63_LcFA 0 "FALSE" 1 "TRUE" ;
VAL_TABLE_ NodeStsVLM_LcFA 0 "FALSE" 1 "TRUE" ;
VAL_TABLE_ NodeStsVKM_LcFA 0 "FALSE" 1 "TRUE" ;
VAL_TABLE_ NodeStsVICM_CAN_9_LcFA 0 "FALSE" 1 "TRUE" ;
VAL_TABLE_ NodeStsVICM_CAN_2_LcFA 0 "FALSE" 1 "TRUE" ;
VAL_TABLE_ NodeStsVCU_CAN_5_LcFA 0 "FALSE" 1 "TRUE" ;
VAL_TABLE_ NodeStsE60_LcFA 0 "FALSE" 1 "TRUE" ;
VAL_TABLE_ NodeStsECP_S2_CAN_2_LcFA 0 "FALSE" 1 "TRUE" ;
VAL_TABLE_ NodeStsE45_LcFA 0 "FALSE" 1 "TRUE" ;
VAL_TABLE_ NodeStsVDM_CAN_2_LcFA 0 "FALSE" 1 "TRUE" ;
VAL_TABLE_ NodeStsWE48_LcFA 0 "FALSE" 1 "TRUE" ;
VAL_TABLE_ NodeStsPCM_CAN_3_LcFA 0 "FALSE" 1 "TRUE" ;
VAL_TABLE_ NodeStsPCM_CAN_2_LcFA 0 "FALSE" 1 "TRUE" ;
VAL_TABLE_ NodeStsSDM_AV_LcFA 0 "FALSE" 1 "TRUE" ;
VAL_TABLE_ NodeStsACP2_MCU_CAN_8_LcFA 0 "FALSE" 1 "TRUE" ;
VAL_TABLE_ NodeStsACP2_MCU_CAN_2_LcFA 0 "FALSE" 1 "TRUE" ;
VAL_TABLE_ NodeStsVECM_CAN_2_LcFA 0 "FALSE" 1 "TRUE" ;
VAL_TABLE_ NodeStsVDM_CAN_9_LcFA 0 "FALSE" 1 "TRUE" ;
VAL_TABLE_ NodeStsE61_CAN_1_LcFA 0 "FALSE" 1 "TRUE" ;
VAL_TABLE_ NodeStsUPM_LcFA 0 "FALSE" 1 "TRUE" ;
VAL_TABLE_ NodeStsEPSb_LcFA 0 "FALSE" 1 "TRUE" ;
VAL_TABLE_ NodeStsSBM_CAN_10_LcFA 0 "FALSE" 1 "TRUE" ;
VAL_TABLE_ NodeStsVECM_CAN_9_LcFA 0 "FALSE" 1 "TRUE" ;
VAL_TABLE_ NodeStsECP_S2_CAN_9_LcFA 0 "FALSE" 1 "TRUE" ;
VAL_TABLE_ NodeStsCSM_AV_CAN_5_LcFA 0 "FALSE" 1 "TRUE" ;
VAL_TABLE_ NodeStsACP3_MCU_CAN_3_LcFA 0 "FALSE" 1 "TRUE" ;
VAL_TABLE_ NodeStsACP3_MCU_CAN_8_LcFA 0 "FALSE" 1 "TRUE" ;
VAL_TABLE_ NodeStsACP3_MCU_CAN_2_LcFA 0 "FALSE" 1 "TRUE" ;
VAL_TABLE_ FrtPsngrAirbagDsblVisIndCmd 0 "On" 1 "Off" 2 "Flash" ;
VAL_TABLE_ ORIP_EnvModPrsntRsp1Auth 0 "FALSE" 1 "TRUE" ;
VAL_TABLE_ ORIP_DrvrStBltStsAuth_Inv 0 "FALSE" 1 "TRUE" ;
VAL_TABLE_ ORIP_DrvrStBltStsAuth 0 "Unknown" 1 "UnFastened" 2 "Fastened" ;
VAL_TABLE_ RstrntSysFltPrsnt 0 "FALSE" 1 "TRUE" ;
VAL_TABLE_ FrtPsngrAirbagEnblVisIndCmd 0 "On" 1 "Off" 2 "Flash" ;
VAL_TABLE_ Sig4429 0 "FALSE" 1 "TRUE" ;
VAL_TABLE_ FE44RS_LtCntr 0 "OFF" 1 "FAILED" 2 "BLOCKED" 3 "ATTACHED_OBJECT" 4 "NO_OBJECT" 5 "ZONE_1" 6 "ZONE_2" 7 "ZONE_3" 8 "ZONE_4" 9 "ZONE_5" 10 "ZONE_6" 11 "OFF_NO_FAULT" 12 "RESERVED_1" 13 "RESERVED_2" 14 "RESERVED_3" ;
VAL_TABLE_ FE44RS_Lt 0 "OFF" 1 "FAILED" 2 "BLOCKED" 3 "ATTACHED_OBJECT" 4 "NO_OBJECT" 5 "ZONE_1" 6 "ZONE_2" 7 "ZONE_3" 8 "ZONE_4" 9 "ZONE_5" 10 "ZONE_6" 11 "OFF_NO_FAULT" 12 "RESERVED_1" 13 "RESERVED_2" 14 "RESERVED_3" ;
VAL_TABLE_ FE44RS_RtCntr 0 "OFF" 1 "FAILED" 2 "BLOCKED" 3 "ATTACHED_OBJECT" 4 "NO_OBJECT" 5 "ZONE_1" 6 "ZONE_2" 7 "ZONE_3" 8 "ZONE_4" 9 "ZONE_5" 10 "ZONE_6" 11 "OFF_NO_FAULT" 12 "RESERVED_1" 13 "RESERVED_2" 14 "RESERVED_3" ;
VAL_TABLE_ FE44RS_Rt 0 "OFF" 1 "FAILED" 2 "BLOCKED" 3 "ATTACHED_OBJECT" 4 "NO_OBJECT" 5 "ZONE_1" 6 "ZONE_2" 7 "ZONE_3" 8 "ZONE_4" 9 "ZONE_5" 10 "ZONE_6" 11 "OFF_NO_FAULT" 12 "RESERVED_1" 13 "RESERVED_2" 14 "RESERVED_3" ;
VAL_TABLE_ E44IM_FaildIndOn 0 "FALSE" 1 "TRUE" ;
VAL_TABLE_ E44IM_DsbldIndOn 0 "FALSE" 1 "TRUE" ;
VAL_TABLE_ E44VisObjIndStatReq 0 "No Action" 1 "Driver Tube Front" 2 "Driver Tube Rear" 3 "Full Active" ;
VAL_TABLE_ E44Rgn 0 "Europe" 1 "North America" ;
VAL_TABLE_ E44IM_TeenDrvrE44OffUnvIndOn 0 "FALSE" 1 "TRUE" ;
VAL_TABLE_ E44IM_SnsrDstbdIndOn 0 "FALSE" 1 "TRUE" ;
VAL_TABLE_ E44IM_SnsrClnIndOn 0 "FALSE" 1 "TRUE" ;
VAL_TABLE_ E44IM_SnsrBlckdIndOn 0 "FALSE" 1 "TRUE" ;
VAL_TABLE_ E44IM_RrOffIndOn 0 "FALSE" 1 "TRUE" ;
VAL_TABLE_ E44IM_OffIndOn 0 "FALSE" 1 "TRUE" ;
VAL_TABLE_ E44IM_FrtOffIndOn 0 "FALSE" 1 "TRUE" ;
VAL_TABLE_ PrkAsstActIndCmnd 0 "FALSE" 1 "TRUE" ;
VAL_TABLE_ PrkAsstStat 0 "OFF" 1 "STANDBY" 2 "DISABLED" 3 "FAILED" 4 "FRONT_REAR_ACTIVE" 5 "REAR_ACTIVE" 6 "FRONT_ACTIVE" 7 "UNKNOWN" ;
VAL_TABLE_ PGI3P_PrplCpbltyStsPriAuth 0 "Request Not Limited" 1 "Request Value Limited Minimum" 2 "Request Value Limited Maximum" 3 "Request Rate Limited" ;
VAL_TABLE_ PGI3P_PrplArbtrtnStsPriAuth 0 "No ADS data" 1 "ADS Active" 2 "Traction Active" 3 "Lost Axle Arbitration" ;
VAL_TABLE_ PGI3P_ADSRedntATReqStsPriAuth 0 "Unknown" 1 "Data Valid" 2 "Data Invalid" 3 "Serial Data Failure" ;
VAL_TABLE_ PGI3P_ADSMnAxlTrqReqStsPriAuth 0 "Unknown" 1 "Data Valid" 2 "Data Invalid" 3 "Serial Data Failure" ;
VAL_TABLE_ PrplSysFricBrkTrqReqTypAuth 0 "No Action" 1 "Braking Not Requested" 2 "Brake Per Torque Request" 3 "Hold" ;
VAL_TABLE_ PGI3P_PrplSysStsPriAuth 0 "Initialize" 1 "Full Function" 2 "Degraded Mode 1" 3 "Degraded Mode 2" 4 "Degraded Mode 3" 5 "Degraded Mode 4" 6 "Degraded Mode 5" ;
VAL_TABLE_ PCIP_HzrdLgtsOnReqdAuth 0 "FALSE" 1 "TRUE" ;
VAL_TABLE_ PCIP_HybVehHiVltgDsblReqdAuth 0 "FALSE" 1 "TRUE" ;
VAL_TABLE_ PCIP_HVCrshImpSnsSysDsbldAuth 0 "FALSE" 1 "TRUE" ;
VAL_TABLE_ PCIP_HVACBlwDsblReqdAuth 0 "FALSE" 1 "TRUE" ;
VAL_TABLE_ PCIP_FuelCutOffReqdAuth 0 "FALSE" 1 "TRUE" ;
VAL_TABLE_ PCIP_DrUnlckReqdAuth 0 "FALSE" 1 "TRUE" ;
VAL_TABLE_ PCIP_CruzCtlDsblReqdAuth 0 "FALSE" 1 "TRUE" ;
VAL_TABLE_ PCIP_BrkActReqdAuth 0 "FALSE" 1 "TRUE" ;
VAL_TABLE_ PCIP_NftnFrtImpPrtnsrSevAchAuth 0 "FALSE" 1 "TRUE" ;
VAL_TABLE_ PCIP_MemStRclDsblReqdAuth 0 "FALSE" 1 "TRUE" ;
VAL_TABLE_ PCIP_IntrLgtOnReqdAuth 0 "FALSE" 1 "TRUE" ;
VAL_TABLE_ PCIP_NtfnLtSdSevAchvdAuth 0 "FALSE" 1 "TRUE" ;
VAL_TABLE_ PCIP_NtfnFrtImpStg2SevAchvdAuth 0 "FALSE" 1 "TRUE" ;
VAL_TABLE_ PCIP_NtfnFrtImpStg1SevAchvdAuth 0 "FALSE" 1 "TRUE" ;
VAL_TABLE_ PCIP_NtfnEvntStsAuth 0 "No Event" 1 "Near Deploy Event" 2 "Deployment Event" ;
VAL_TABLE_ PCIP_eCallReqdAuth 0 "FALSE" 1 "TRUE" ;
VAL_TABLE_ PCIP_NtfnRtSdSevAchvdAuth 0 "FALSE" 1 "TRUE" ;
VAL_TABLE_ PCIP_NtfnRrImpSevAchvdAuth 0 "FALSE" 1 "TRUE" ;
VAL_TABLE_ PCIP_NtfnRlOvrSevAchvdAuth 0 "FALSE" 1 "TRUE" ;
VAL_TABLE_ PCIP_NtfnPedtrnPrtctnSevAchAuth 0 "FALSE" 1 "TRUE" ;
VAL_TABLE_ POFT_PstnOfstFrmTrmLF_Inv 0 "FALSE" 1 "TRUE" ;
VAL_TABLE_ POFT_PstnOfstFrmTrmLR_Inv 0 "FALSE" 1 "TRUE" ;
VAL_TABLE_ POFT_PstnOfstFrmTrmRF_Inv 0 "FALSE" 1 "TRUE" ;
VAL_TABLE_ POFT_PstnOfstFrmTrmRR_Inv 0 "FALSE" 1 "TRUE" ;
VAL_TABLE_ POFT_SpnsnTrmPstnLrnCmplt 0 "FALSE" 1 "TRUE" ;
VAL_TABLE_ PSIP_StrgAsstRdcdLvl3IndOnAuth 0 "FALSE" 1 "TRUE" ;
VAL_TABLE_ PSIP_StrgAsstRdcdLvl2IndOnAuth 0 "FALSE" 1 "TRUE" ;
VAL_TABLE_ PSIP_StrgAsstRdcdIndOnAuth 0 "FALSE" 1 "TRUE" ;
VAL_TABLE_ PSIP_PwrStrgIndOnAuth 0 "FALSE" 1 "TRUE" ;
VAL_TABLE_ Sig5023 0 "FALSE" 1 "TRUE" ;
VAL_TABLE_ SATCRTP_SecAxlTrqCplRqTyAuth 0 "No Action" 1 "Maximum Allowed Torque" 2 "Minimum Allowed Torque" 3 "Control to Requested Torque" ;
VAL_TABLE_ SAP_PwrtrnXferCaseModeAuth 0 "2 Wheel Drive High" 1 "4 Wheel Drive High" 2 "4 Wheel Drive Low" 3 "Neutral" ;
VAL_TABLE_ SAP_SecAxlOpMdAuth 0 "2WD High" 1 "4WD High Rigid Coupling" 2 "4WD Low Rigid Coupling" 3 "AWD Active Single Clutch" 4 "4WD High Active Clutch" 5 "4WD Low Active Clutch" 6 "AWD Active Twin Clutch" 7 "2WD Low" 8 "Unknown" 9 "Neutral" ;
VAL_TABLE_ SAP_SecAxl4WDAWDStatAuth 0 "Normal" 1 "Temporary_Limited" 2 "Temporary_Inhibit" 3 "Permanently_Failed" ;
VAL_TABLE_ SAP_SecAxl4WDAWDEstTrqAuth_Inv 0 "FALSE" 1 "TRUE" ;
VAL_TABLE_ SAP_XferCaseRngShfPndgAuth 0 "None" 1 "ShiftOutofHighRange" 2 "ShiftOutofLowRange" 3 "ShiftOutofNeutralRange" ;
VAL_TABLE_ SAP_SecAxlOpMdAuth_Inv 0 "FALSE" 1 "TRUE" ;
VAL_TABLE_ SADSVTSLP_VehTpSpdLimReqTypAuth 0 "Inactive" 1 "Faulted" 2 "Safety_woBrake" 3 "Safety_wBrake" 4 "OBD" 5 "nonOBD" 6 "Legislated" ;
VAL_TABLE_ SLVFSP_SpdLimVsnFsdSpdUntAuth 0 "km/h" 1 "mph" ;
VAL_TABLE_ SLVFSP_SpdLimVsnFsdSpdNwDtdAuth 0 "FALSE" 1 "TRUE" ;
VAL_TABLE_ SLVFSP_SpdLimVsnFsdSpdAuth_DuD 0 "FALSE" 1 "TRUE" ;
VAL_TABLE_ SGI2P_AirSpnsnRdHghtLwrActnAuth 0 "None" 1 "Slow" 2 "Medium (Exhaust)" 3 "Fast" ;
VAL_TABLE_ SGI2P_AirSpnsnRdHghtActvAxlAuth 0 "None" 1 "Front" 2 "Rear" 3 "Both" 4 "Pending" ;
VAL_TABLE_ SGI2P_AirSpnsnRdHghtActlStsAuth 0 "Faulted" 1 "Entry/Exit" 2 "Lowered 3(Stability)" 3 "Lowered 2 (Sport)" 4 "Lowered 1 (Aero)" 5 "Showroom" 6 "Normal" 7 "Raised 1" 8 "Raised 2" 9 "Raised 3" ;
VAL_TABLE_ SGI2P_AirSpnsnRdHghtTgtStsAuth 0 "Faulted" 1 "Entry/Exit" 2 "Lowered 3(Stability)" 3 "Lowered 2 (Sport)" 4 "Lowered 1 (Aero)" 5 "Showroom" 6 "Normal" 7 "Raised 1" 8 "Raised 2" 9 "Raised 3" ;
VAL_TABLE_ SGI2P_AirSpnsnRdHghtRseActnAuth 0 "None" 1 "Slow(i.e. compressor)" 2 "Medium (i.e. Boost)" 3 "Fast (i.e. Reservoir)" ;
VAL_TABLE_ UpftrSnwPlwModeActv_Inv 0 "FALSE" 1 "TRUE" ;
VAL_TABLE_ UpftrSnwPlwModeActv 0 "FALSE" 1 "TRUE" ;
VAL_TABLE_ UpftrSnwPlwHdlmpsActv 0 "FALSE" 1 "TRUE" ;
VAL_TABLE_ UpftrLckReq 0 "No Request" 1 "Lock All" 2 "Unlock All" ;
VAL_TABLE_ UpftrAutoShtdnInhbReqd 0 "FALSE" 1 "TRUE" ;
VAL_TABLE_ UpftrAllWndMtnReq 0 "No Request" 1 "Open Fully" 2 "Open Vent" 3 "Close Fully" ;
VAL_TABLE_ UpftrVehRmtStrtupReq 0 "No Request" 1 "Engine Requested Off" 2 "Engine Requested On" ;
VAL_TABLE_ HVGI1P_PrplRltdBsHVAllwdPriAuth 0 "FALSE" 1 "TRUE" ;
VAL_TABLE_ HVGI1P_HVBatCntctrStsPriAuth 0 "Open" 1 "Precharge" 2 "Close" ;
VAL_TABLE_ HVGI1P_CntctrShtdnReqPriAuth 0 "None" 1 "Emergency Shutdown" 2 "Controlled Shutdown" 3 "Emergency Crash Shutdown" ;
VAL_TABLE_ ElcDischrgActr2DischrgCmdAuth 0 "NoAction" 1 "Normal" 2 "Immediate" 3 "Emergency" ;
VAL_TABLE_ HVGI7P_ESSPrplSysStsPriAuth 0 "Unavailable" 1 "Operational" 2 "ControlledShutdown" 3 "EmergencyShutdown" 4 "EmergencyCrash" 5 "Suspend Request" ;
VAL_TABLE_ HVGI7P_ESSPrplSysRespPriAuth 0 "Idle" 1 "Activating" 2 "Active" 3 "Deactivating" ;
VAL_TABLE_ VirtKeyAllDrLckReqd 0 "FALSE" 1 "TRUE" ;
VAL_TABLE_ VirtKeyPncReq 0 "No Request" 1 "Activate" 2 "Cancel" ;
VAL_TABLE_ VirtKeyFobAvlReq 0 "No Request" 1 "Enable Fobs" 2 "Disable Fobs" ;
VAL_TABLE_ VirtKeyRmtLctrReq 0 "No Request" 1 "Activate Low" 2 "Activate Medium" 3 "Activate High" 4 "Cancel" ;
VAL_TABLE_ SRPCrsFrtInSftBtnMblDevSts 0 "Not Pressed" 1 "Pressed" ;
VAL_TABLE_ SRPCrsBkInSftBtnMblDevSts 0 "Not Pressed" 1 "Pressed" ;
VAL_TABLE_ VirtKeyRrClsrUnlckReqd 0 "FALSE" 1 "TRUE" ;
VAL_TABLE_ VirtKeyRrClsrLckReqd 0 "FALSE" 1 "TRUE" ;
VAL_TABLE_ VirtKeyFrtClsrUnlckReqd 0 "FALSE" 1 "TRUE" ;
VAL_TABLE_ VirtKeyFrtClsrLckReqd 0 "FALSE" 1 "TRUE" ;
VAL_TABLE_ VirtKeyDrvrDrUnlckReqd 0 "FALSE" 1 "TRUE" ;
VAL_TABLE_ VirtKeyAllDrUnlckReqd 0 "FALSE" 1 "TRUE" ;
VAL_TABLE_ SRPSrchingSftBtnMblDevSts 0 "Not Pressed" 1 "Pressed" ;
VAL_TABLE_ SRPRtSftBtnMblDevSts 0 "Not Pressed" 1 "Pressed" ;
VAL_TABLE_ SRPPrlllPrkSftBtnMblDevSts 0 "Not Pressed" 1 "Pressed" ;
VAL_TABLE_ SRPLtSftBtnMblDevSts 0 "Not Pressed" 1 "Pressed" ;
VAL_TABLE_ SRPExtPrkSftBtnMblDevSts 0 "Not Pressed" 1 "Pressed" ;
VAL_TABLE_ VirtKeyPwrTopCtlReqrMblDevIdfr 0 "Unknown" 1 "Mobile Device Identifier 1" 2 "Mobile Device Identifier 2" 3 "Mobile Device Identifier 3" 4 "Mobile Device Identifier 4" 5 "Mobile Device Identifier 5" 6 "Mobile Device Identifier 6" 7 "Mobile Device Identifier 7" 8 "Mobile Device Identifier 8" 9 "Mobile Device Identifier 9" 10 "Mobile Device Identifier 10" 11 "Mobile Device Identifier 11" 12 "Mobile Device Identifier 12" 13 "Mobile Device Identifier 13" 14 "Mobile Device Identifier 14" 15 "Mobile Device Identifier 15" ;
VAL_TABLE_ VirtKeyPwrTopCtlReq 0 "No Request" 1 "Open" 2 "Close" 3 "Stop" 4 "Pause" ;
VAL_TABLE_ VirtKeyPwrRrClsrCtlReq 0 "No Request" 1 "Start" 2 "Stop" 3 "Open" 4 "Close" ;
VAL_TABLE_ VirtKeyFrtClsrCtlReq 0 "No Request" 1 "Start" 2 "Stop" 3 "Release" 4 "Open" 5 "Close" ;
VAL_TABLE_ VirtKeyWndCtlReq 0 "No Request" 1 "Open Fully" 2 "Vent" 3 "Close Fully" ;
VAL_TABLE_ VirtKeyVehCbnACReq 0 "No Request" 1 "Activate" 2 "Cancel" ;
VAL_TABLE_ VirtKeySnrfCtlReq 0 "No Request" 1 "Open Fully" 2 "Vent" 3 "Close Fully" ;
VAL_TABLE_ SRPMblDevDctvBtnSts 0 "Not Pressed" 1 "Pressed" ;
VAL_TABLE_ VirtKeyVehCbnACTempLvlReqActv 0 "FALSE" 1 "TRUE" ;
VAL_TABLE_ VirtKeyRrClsrRelReqd 0 "FALSE" 1 "TRUE" ;
VAL_TABLE_ ElecDrvUnt3DrvUntPrplSecSts 0 "Inactive" 1 "Active" 2 "Transitional" ;
VAL_TABLE_ ElecDrvUnt2DrvUntPrplSecSts 0 "Inactive" 1 "Active" 2 "Transitional" ;
VAL_TABLE_ ElecDrvUnt3DrvUntPrplSecCmd 0 "Disable" 1 "Enable" ;
VAL_TABLE_ ElecDrvUnt2DrvUntPrplSecCmd 0 "Disable" 1 "Enable" ;
VAL_TABLE_ ACRefrigLoSdFPSCktFABndl 0 "FALSE" 1 "TRUE" ;
VAL_TABLE_ ACRefrigLoSdFldPrsVal_Inv 0 "FALSE" 1 "TRUE" ;
VAL_TABLE_ HVGI11_PwrElecCoolLoopTemp_Inv 0 "FALSE" 1 "TRUE" ;
VAL_TABLE_ HVGI11_PwrElecCoolLoopTemp_DuD 0 "FALSE" 1 "TRUE" ;
VAL_TABLE_ AltTxPrplSysOffTm_Inv 0 "FALSE" 1 "TRUE" ;
VAL_TABLE_ AltTxPrplSysOffTm_DuD 0 "FALSE" 1 "TRUE" ;
VAL_TABLE_ SuprRmtPrkFricBrkTrqReqTyp 0 "No Action" 1 "Braking Not Requested" 2 "Brake Per Torque" 3 "Hold" ;
VAL_TABLE_ SuprRmtPrkElecPrkBrkReq 0 "No Request" 1 "Apply" 2 "Release" ;
VAL_TABLE_ SuprRmtPrkPrplSysActvnReqd 0 "FALSE" 1 "TRUE" ;
VAL_TABLE_ ClmCtlCbnMaxDefrReqOn_Inv 0 "FALSE" 1 "TRUE" ;
VAL_TABLE_ ClmCtlCbnMaxDefrReqOn 0 "FALSE" 1 "TRUE" ;
VAL_TABLE_ ClmCtlCbnFrtRtTempSet_Inv 0 "FALSE" 1 "TRUE" ;
VAL_TABLE_ ClmCtlCbnFrtLtTempSet_Inv 0 "FALSE" 1 "TRUE" ;
VAL_TABLE_ ClmCtlCbnEvpAirOutTemp_Inv 0 "FALSE" 1 "TRUE" ;
VAL_TABLE_ BSIR2P_BrkgSysVhTpSpLmRqTypAuth 0 "Inactive" 1 "OBD" ;
VAL_TABLE_ BSIR2P_BSPriVehTpSpLimRqTypAuth 0 "Inactive" 1 "Faulted" 2 "Safety_woBrake" 3 "Safety_wBrake" 4 "OBD" 5 "nonOBD" 6 "Legislated" ;
VAL_TABLE_ BSIR2P_BSPriVehTpSpLimRqSrcAuth 0 "None" 1 "eBoost" 2 "ESC" ;
VAL_TABLE_ BSISP_ESCActvAuth 0 "FALSE" 1 "TRUE" ;
VAL_TABLE_ BSISP_TCSFaildAuth 0 "FALSE" 1 "TRUE" ;
VAL_TABLE_ BSISP_TCSDrvrIntntAuth 0 "Disabled" 1 "Enabled" ;
VAL_TABLE_ BSISP_TCSActvAuth 0 "FALSE" 1 "TRUE" ;
VAL_TABLE_ BSISP_ETRSHydrlcBrkgStsAuth 0 "Not Active" 1 "Active" 2 "Failed" ;
VAL_TABLE_ BSISP_ESCSysStsAuth 0 "Normal Operation" 1 "Failed" 2 "Initializing" 3 "Enhanced Operation" 4 "Driver Disable" ;
VAL_TABLE_ DMCP_VehSpdLimFricBrkStsAuth 0 "Inactive" 1 "Active" 2 "Not available" ;
VAL_TABLE_ DMCP_AWDPerfModeReqAuth 0 "No Action" 1 "Normal" 2 "Sport" 3 "Track/Baja" 4 "Winter" 5 "Off Road" 6 "Terrain" 7 "Disconnect" ;
VAL_TABLE_ BrkgSysVehTopSpdLimIndOnAuth 0 "FALSE" 1 "TRUE" ;
VAL_TABLE_ EPBSP_ElecPrkBrkAvlStsAuth 0 "Unavailable" 1 "Available" 2 "Failed" ;
VAL_TABLE_ EPBSP_ElecPrkBrkApplStsAuth 0 "Unknown" 1 "Applied" 2 "Released" 3 "Dynamic Apply" 4 "In-Progress" ;
VAL_TABLE_ EPBSP_EPBSysBrkLgtsReqdAuth 0 "FALSE" 1 "TRUE" ;
VAL_TABLE_ EPBSP_BrkSysBrkLgtsReqdAuth 0 "FALSE" 1 "TRUE" ;
VAL_TABLE_ DMCP_EnvIdRsp2Auth 0 "FALSE" 1 "TRUE" ;
VAL_TABLE_ TBIP_TrlrBrkDsbldIndOnAuth 0 "FALSE" 1 "TRUE" ;
VAL_TABLE_ TBIP_ServTrlrBrkgSysIndOnAuth 0 "FALSE" 1 "TRUE" ;
VAL_TABLE_ TBIP_CkTrlrIndOnAuth 0 "FALSE" 1 "TRUE" ;
VAL_TABLE_ EPBSP_TrlrBrkgSysBrkLgtsRqdAuth 0 "FALSE" 1 "TRUE" ;
VAL_TABLE_ TBIP_TrlrWrgFltIndOnAuth 0 "FALSE" 1 "TRUE" ;
VAL_TABLE_ TBIP_TrlrBrkgGainSetIndOnAuth 0 "FALSE" 1 "TRUE" ;
VAL_TABLE_ ElecPrkBrkMnPriPerfRdcd 0 "FALSE" 1 "TRUE" ;
VAL_TABLE_ TrlrBrkgRdcdIndOn 0 "FALSE" 1 "TRUE" ;
VAL_TABLE_ TrlrBrkgHldLstKnwnGainIndOn 0 "FALSE" 1 "TRUE" ;
VAL_TABLE_ AASILASStrgReqLnFllwgRrStrgInhb 0 "FALSE" 1 "TRUE" ;
VAL_TABLE_ AASILASStrgReqSts 0 "Unknown" 1 "Active" 2 "Inactive" ;
VAL_TABLE_ AASILASStrgReqAFtr 0 "None" 1 "Collision Avoidance Steeering" 2 "Traffic Jam Assist" 3 "Lane Centering and Control" 4 "Hands-On Lane Following" 5 "Steering Angle Assist" 6 "Lane Keep Assist" 7 "Lane Change on Demand" 8 "Lateral Collision Prevention" ;
VAL_TABLE_ AASILASStrgReqTyp 0 "Torque" 1 "Angle" ;
VAL_TABLE_ LnDtnWrnCtlTrqOvrlyReqActv_Inv 0 "FALSE" 1 "TRUE" ;
VAL_TABLE_ LnDtnWrnCtlTrqOvrlyReqActv_DuD 0 "FALSE" 1 "TRUE" ;
VAL_TABLE_ LnDtnWrnCtlTrqOvrlyReqActv 0 "Active" 1 "Inactive" ;
VAL_TABLE_ LnDtnWrnCtlHRTrqOvrlyReqVal_Inv 0 "FALSE" 1 "TRUE" ;
VAL_TABLE_ LnDtnWrnCtlHRTrqOvrlyReqVal_DuD 0 "FALSE" 1 "TRUE" ;
VAL_TABLE_ SpnsnPstnOfstFromTrmRR_Inv 0 "FALSE" 1 "TRUE" ;
VAL_TABLE_ SpnsnPstnOfstFromTrmRF_Inv 0 "FALSE" 1 "TRUE" ;
VAL_TABLE_ SpnsnPstnOfstFromTrmLR_Inv 0 "FALSE" 1 "TRUE" ;
VAL_TABLE_ SpnsnPstnOfstFromTrmLF_Inv 0 "FALSE" 1 "TRUE" ;
VAL_TABLE_ SecGridBatVltgCtlOvrrdActv 0 "FALSE" 1 "TRUE" ;
VAL_TABLE_ PriVehChlrOutCoolTemp_Inv 0 "FALSE" 1 "TRUE" ;
VAL_TABLE_ PriVehThrmlSysFltStat 0 "No Fault" 1 "Failed" 2 "Degraded Operation" ;
VAL_TABLE_ APM2Sts 0 "NormConvNormTempLo" 1 "NormConvNormTempHi" 2 "Derated" 3 "HighTempNearDerated" 4 "Dsbld" 5 "HiTempDsbldDerated" 6 "Indeterminate" 7 "CommandedOff" 8 "OverTempConvDerated" ;
VAL_TABLE_ FOE46ecGrdVltgOvrrdPrty 0 "None" 1 "Low" 2 "Medium" 3 "High" ;
VAL_TABLE_ BSIRP_AutoBrkgPTReqStsAuth 0 "Inactive" 1 "Active" 2 "Failed" 3 "Serial Communication Failure" ;
VAL_TABLE_ BSIRP_AdpCruzHldActvAuth 0 "FALSE" 1 "TRUE" ;
VAL_TABLE_ BSIRP_ChsSysAxlTqRqRspTpAuth 0 "Inactive" 1 "Pleasability Limited Request" 2 "Maximum Range Request" 3 "Automatic Actuator Selection" 4 "Braking Torque Request" ;
VAL_TABLE_ BSIRP_ChsSysAxlTqRqFncAuth 0 "None" 1 "Engine Drag Control" 2 "Traction control" 3 "Electronic Stability Control" 4 "Active safety braking" 5 "Driveline protection" 6 "Power Hop" 7 "Performance Traction Control" 8 "Hill Descent Control" 9 "Advanced Park Assist" 10 "Brake System Cruise Control" 11 "Torque Vectoring" 12 "Launch Control" 13 "Line Lock" 14 "Regenerative Torque Limitation" ;
VAL_TABLE_ BSIRP_ChsSysPrdAxlTqRqItvTpAuth 0 "No Intervention" 1 "Maximum Limit" 2 "Minimum Limit" 3 "Minimum and Maximum Limit" ;
VAL_TABLE_ BrkAsstHalfSysBstFaildCktAuth 0 "None" 1 "Front / Front" 2 "Rear / Rear" 3 "Left Front / Right Rear" 4 "Right Front / Left Rear" ;
VAL_TABLE_ BSIRP_RrVirtBmpInhbAuth 0 "FALSE" 1 "TRUE" ;
VAL_TABLE_ BSIRP_HillDscntCtlStsAuth 0 "Not Enabled" 1 "Enabled" 2 "Active" ;
VAL_TABLE_ BSIRP_DrvrSeltdHldEnbldAuth 0 "FALSE" 1 "TRUE" ;
VAL_TABLE_ BSIRP_DrvrSeltdHldActvAuth 0 "FALSE" 1 "TRUE" ;
VAL_TABLE_ BSIRP_ClsnPrepSysInhbAuth 0 "FALSE" 1 "TRUE" ;
VAL_TABLE_ BrkSysSpltFricCoefBrkgActvAuth 0 "FALSE" 1 "TRUE" ;
VAL_TABLE_ BrkSysSpltFricCoefAccelActvAuth 0 "FALSE" 1 "TRUE" ;
VAL_TABLE_ CBIP_ACCBrkgStsAuth 0 "Not Active" 1 "Active" 2 "Failed" ;
VAL_TABLE_ CBIP_ACCBrkgActvAuth 0 "FALSE" 1 "TRUE" ;
VAL_TABLE_ CBIP_ClsnImntBrkgStsAuth 0 "Not Active" 1 "Active" 2 "Failed" ;
VAL_TABLE_ CBIP_BrkPedPstnEmsRltdAuth_Inv 0 "FALSE" 1 "TRUE" ;
VAL_TABLE_ CSATRP_PriATReqFncAuth 0 "None" 1 "Engine Drag Control" 2 "Traction control" 3 "Electronic Stability Control" 4 "Driveline Protection" 5 "Power Hop" 6 "Performance Traction Control" 7 "Torque Vectoring" 8 "Launch Control" 9 "Line Lock" 10 "Regenerative Torque Limitation" ;
VAL_TABLE_ CBIP_EPBCruzCtlCnclReqAuth 0 "FALSE" 1 "TRUE" ;
VAL_TABLE_ CBIP_DrvrIndpntBrkAppActvAuth 0 "FALSE" 1 "TRUE" ;
VAL_TABLE_ CBIP_ClsnImntDrvrBrkPedOvrdAuth 0 "FALSE" 1 "TRUE" ;
VAL_TABLE_ CSATRP_PriATReqIntvTypPrdtdAuth 0 "No Intervention" 1 "Maximum Limit" 2 "Minimum Limit" 3 "Minimum and Maximum Limit" ;
VAL_TABLE_ CSATRP_SecATReqFncAuth 0 "None" 1 "Engine Drag Control" 2 "Traction control" 3 "Electronic Stability Control" 4 "Driveline Protection" 5 "Power Hop" 6 "Performance Traction Control" 7 "Torque Vectoring" 8 "Launch Control" 9 "Line Lock" 10 "Regenerative Torque Limitation" ;
VAL_TABLE_ CSATRP_SecATIntvTypPrdtdAuth 0 "No Intervention" 1 "Maximum Limit" 2 "Minimum Limit" 3 "Minimum and Maximum Limit" ;
VAL_TABLE_ CSATRP_PriATReqRespTypAuth 0 "Inactive" 1 "Pleasability Limited Request" 2 "Maximum Range Request" 3 "Automatic Actuator Selection" 4 "Braking Torque Request" ;
VAL_TABLE_ CSATRP_SecATReqRespTypAuth 0 "Inactive" 1 "Pleasability Limited Request" 2 "Maximum Range Request" 3 "Automatic Actuator Selection" 4 "Braking Torque Request" ;
VAL_TABLE_ CSBTP_ChsSysTtBrkAxTqVlAuth_Inv 0 "FALSE" 1 "TRUE" ;
VAL_TABLE_ FWDECP_LFAuth_Inv 0 "FALSE" 1 "TRUE" ;
VAL_TABLE_ PTP_EngSpdIntvTypAuth 0 "No Intervention" 1 "Engine Speed Maximum Limit" ;
VAL_TABLE_ PTP_EngSpdCtlRespAuth 0 "No Suggestion" 1 "Transient Optimized" 2 "Stability Optimized Condition 1" 3 "Stability Optimized Condition 2" ;
VAL_TABLE_ PTP_DCTLaunchCtlActvAuth 0 "FALSE" 1 "TRUE" ;
VAL_TABLE_ FWDECP_RstOccAuth 0 "FALSE" 1 "TRUE" ;
VAL_TABLE_ FWDECP_RFAuth_Inv 0 "FALSE" 1 "TRUE" ;
VAL_TABLE_ RALTCRP_TypAuth 0 "No Action" 1 "Maximum Allowed Torque" 2 "Minimum Allowed Torque" 3 "Control to Requested Torque" ;
VAL_TABLE_ RWDECP_LRAuth_Inv 0 "FALSE" 1 "TRUE" ;
VAL_TABLE_ RWDECP_RRAuth_Inv 0 "FALSE" 1 "TRUE" ;
VAL_TABLE_ RWDECP_RstOccAuth 0 "FALSE" 1 "TRUE" ;
VAL_TABLE_ TCTR1P_AxlTrqReqTypRRAuth 0 "No Action" 1 "Maximum Allowed Torque" 2 "Minimum Allowed Torque" 3 "Control To Requested Torque" ;
VAL_TABLE_ TCTR1P_AxlTrqReqTypLRAuth 0 "No Action" 1 "Maximum Allowed Torque" 2 "Minimum Allowed Torque" 3 "Control To Requested Torque" ;
VAL_TABLE_ WhlAngVelLFrtAuth_Inv 0 "FALSE" 1 "TRUE" ;
VAL_TABLE_ WhlAngVelLRrAuth_Inv 0 "FALSE" 1 "TRUE" ;
VAL_TABLE_ WhlAngVelRFrtAuth_Inv 0 "FALSE" 1 "TRUE" ;
VAL_TABLE_ WhlBrkPresAuth_Inv 0 "FALSE" 1 "TRUE" ;
VAL_TABLE_ WhlAngVelRRrAuth_Inv 0 "FALSE" 1 "TRUE" ;
VAL_TABLE_ ChsSysPriAxlLtTqRqIntvTpAuth 0 "No Intervention" 1 "Maximum Limit" 2 "Minimum Limit" 3 "Minimum and Maximum Limit" ;
VAL_TABLE_ ChsSysPriAxlRtTqRqIntvTpAuth 0 "No Intervention" 1 "Maximum Limit" 2 "Minimum Limit" 3 "Minimum and Maximum Limit" ;
VAL_TABLE_ ChsSysPriAxlLtTrqReqFncAuth 0 "None" 1 "Engine Drag Control" 2 "Traction Control" 3 "Electronic Stability Control" 4 "Driveline Protection" 5 "Power Hop" 6 "Performance Traction Control" 7 "Torque Vectoring" 8 "Launch Control" 9 "Line Lock" 10 "Regenerative Torque Limitation" ;
VAL_TABLE_ ChsSysPrplSysFricBrkTqRqStsAuth 0 "Unknown" 1 "Not Active" 2 "Friction Braking Active" 3 "Hold Active" 4 "Failed" ;
VAL_TABLE_ ChsSysPriAxlRtTrqReqFncAuth 0 "None" 1 "Engine Drag Control" 2 "Traction Control" 3 "Electronic Stability Control" 4 "Driveline Protection" 5 "Power Hop" 6 "Performance Traction Control" 7 "Torque Vectoring" 8 "Launch Control" 9 "Line Lock" 10 "Regenerative Torque Limitation" ;
VAL_TABLE_ BrkSysBrkTrqSfcntStndstl 0 "FALSE" 1 "TRUE" ;
VAL_TABLE_ VehDynOvrstrUndrstrVal_Inv 0 "FALSE" 1 "TRUE" ;
VAL_TABLE_ Sig0539 0 "Idle" 1 "Active" 2 "Complete" 3 "Aborted" ;
VAL_TABLE_ Sig0538 0 "None" 1 "Self Test" 2 "Primary Brake Module" 3 "Secondary Brake Module" 4 "External" 5 "Autonomous" ;
VAL_TABLE_ Sig0454 0 "None" 1 "PBM Basic Functional Test" 2 "PBM Enhanced Functional Test" 3 "Operational Safety Integrity Check" ;
VAL_TABLE_ BSSIP_PerfTracMgmtEnbldAuth 0 "FALSE" 1 "TRUE" ;
VAL_TABLE_ BSSIP_LnchCtlModeStsAuth 0 "Disable" 1 "General" 2 "General Custom" 3 "High Traction" 4 "High Traction Custom" 5 "Line Lock" 6 "Line Lock Press Brake" 7 "Line Lock Release Brake" ;
VAL_TABLE_ BSSIP_BrkAsstBrkBstStsAuth 0 "No Boost" 1 "Normal Boost" 2 "Boost with Warning" 3 "Shut Down Boost" 4 "No Boost EPB Assist" 5 "Hydraulic Leak Detection" 6 "Half System Boost" 7 "Diagnostic Mode" 8 "Brake Fade 1" 9 "Brake Fade 2" ;
VAL_TABLE_ BrkSysBrkFldLvlHiIntegSts 0 "Unknown" 1 "Normal" 2 "Low" 3 "Critically Low" ;
VAL_TABLE_ ChsDynoModeEnbld 0 "FALSE" 1 "TRUE" ;
VAL_TABLE_ Sig5884 0 "Has Never Moved" 1 "Has Moved But Currently Stopped" 2 "Moving In Same Direction As Host" 3 "Moving In Opposite Direction As Host" 4 "Crossing Path" ;
VAL_TABLE_ Sig5883 0 "Highly Speculative" 1 "Speculative" 2 "Confident" 3 "Highly Confident" ;
VAL_TABLE_ Sig5887 0 "No Object" 1 "New Object" 2 "Latent Track Not Detected this Cycle" 3 "Measured this Cycle" ;
VAL_TABLE_ Sig5895 0 "Highly Speculative" 1 "Speculative" 2 "Confident" 3 "Highly Confident" ;
VAL_TABLE_ Sig5894 0 "Unknown" 1 "Pedestrian" 2 "Bicycle" ;
VAL_TABLE_ Sig5999 0 "Stopped" 1 "Not Stopped" ;
VAL_TABLE_ Sig5998 0 "Has Never Moved" 1 "Moving In Same Direction As Host" 2 "Moving In Opposite Direction As Host" 3 "Crossing From Left To Right" 4 "Crossing From Right To Left" ;
VAL_TABLE_ Sig5997 0 "Highly Speculative" 1 "Speculative" 2 "Confident" 3 "Highly Confident" ;
VAL_TABLE_ Sig6001 0 "No Object" 1 "New Object" 2 "Latent Track Not Detected this Cycle" 3 "Measured this Cycle" ;
VAL_TABLE_ Sig6015 0 "Highly Speculative" 1 "Speculative" 2 "Confident" 3 "Highly Confident" ;
VAL_TABLE_ Sig6017 0 "Highly Speculative" 1 "Speculative" 2 "Confident" 3 "Highly Confident" ;
VAL_TABLE_ Sig6019 0 "Stopped" 1 "Not Stopped" ;
VAL_TABLE_ Sig6018 0 "Has Never Moved" 1 "Moving In Same Direction As Host" 2 "Moving In Opposite Direction As Host" 3 "Crossing From Left To Right" 4 "Crossing From Right To Left" ;
VAL_TABLE_ Sig6021 0 "No Object" 1 "New Object" 2 "Latent Track Not Detected this Cycle" 3 "Measured this Cycle" ;
VAL_TABLE_ Sig6035 0 "Highly Speculative" 1 "Speculative" 2 "Confident" 3 "Highly Confident" ;
VAL_TABLE_ Sig6039 0 "Stopped" 1 "Not Stopped" ;
VAL_TABLE_ Sig6038 0 "Has Never Moved" 1 "Moving In Same Direction As Host" 2 "Moving In Opposite Direction As Host" 3 "Crossing From Left To Right" 4 "Crossing From Right To Left" ;
VAL_TABLE_ Sig6037 0 "Highly Speculative" 1 "Speculative" 2 "Confident" 3 "Highly Confident" ;
VAL_TABLE_ Sig6041 0 "No Object" 1 "New Object" 2 "Latent Track Not Detected this Cycle" 3 "Measured this Cycle" ;
VAL_TABLE_ Sig6055 0 "Highly Speculative" 1 "Speculative" 2 "Confident" 3 "Highly Confident" ;
VAL_TABLE_ Sig5897 0 "Has Never Moved" 1 "Has Moved But Currently Stopped" 2 "Moving In Same Direction As Host" 3 "Moving In Opposite Direction As Host" 4 "Crossing Path" ;
VAL_TABLE_ Sig5896 0 "Highly Speculative" 1 "Speculative" 2 "Confident" 3 "Highly Confident" ;
VAL_TABLE_ Sig5900 0 "No Object" 1 "New Object" 2 "Latent Track Not Detected this Cycle" 3 "Measured this Cycle" ;
VAL_TABLE_ Sig5908 0 "Highly Speculative" 1 "Speculative" 2 "Confident" 3 "Highly Confident" ;
VAL_TABLE_ Sig5907 0 "Unknown" 1 "Pedestrian" 2 "Bicycle" ;
VAL_TABLE_ Sig6059 0 "Stopped" 1 "Not Stopped" ;
VAL_TABLE_ Sig6058 0 "Has Never Moved" 1 "Moving In Same Direction As Host" 2 "Moving In Opposite Direction As Host" 3 "Crossing From Left To Right" 4 "Crossing From Right To Left" ;
VAL_TABLE_ Sig6057 0 "Highly Speculative" 1 "Speculative" 2 "Confident" 3 "Highly Confident" ;
VAL_TABLE_ Sig6061 0 "No Object" 1 "New Object" 2 "Latent Track Not Detected this Cycle" 3 "Measured this Cycle" ;
VAL_TABLE_ Sig6075 0 "Highly Speculative" 1 "Speculative" 2 "Confident" 3 "Highly Confident" ;
VAL_TABLE_ Sig6077 0 "Highly Speculative" 1 "Speculative" 2 "Confident" 3 "Highly Confident" ;
VAL_TABLE_ Sig6079 0 "Stopped" 1 "Not Stopped" ;
VAL_TABLE_ Sig6078 0 "Has Never Moved" 1 "Moving In Same Direction As Host" 2 "Moving In Opposite Direction As Host" 3 "Crossing From Left To Right" 4 "Crossing From Right To Left" ;
VAL_TABLE_ Sig6081 0 "No Object" 1 "New Object" 2 "Latent Track Not Detected this Cycle" 3 "Measured this Cycle" ;
VAL_TABLE_ Sig6095 0 "Highly Speculative" 1 "Speculative" 2 "Confident" 3 "Highly Confident" ;
VAL_TABLE_ Sig6099 0 "Stopped" 1 "Not Stopped" ;
VAL_TABLE_ Sig6098 0 "Has Never Moved" 1 "Moving In Same Direction As Host" 2 "Moving In Opposite Direction As Host" 3 "Crossing From Left To Right" 4 "Crossing From Right To Left" ;
VAL_TABLE_ Sig6097 0 "Highly Speculative" 1 "Speculative" 2 "Confident" 3 "Highly Confident" ;
VAL_TABLE_ Sig6101 0 "No Object" 1 "New Object" 2 "Latent Track Not Detected this Cycle" 3 "Measured this Cycle" ;
VAL_TABLE_ Sig6115 0 "Highly Speculative" 1 "Speculative" 2 "Confident" 3 "Highly Confident" ;
VAL_TABLE_ Sig5910 0 "Has Never Moved" 1 "Has Moved But Currently Stopped" 2 "Moving In Same Direction As Host" 3 "Moving In Opposite Direction As Host" 4 "Crossing Path" ;
VAL_TABLE_ Sig5909 0 "Highly Speculative" 1 "Speculative" 2 "Confident" 3 "Highly Confident" ;
VAL_TABLE_ Sig5913 0 "No Object" 1 "New Object" 2 "Latent Track Not Detected this Cycle" 3 "Measured this Cycle" ;
VAL_TABLE_ Sig5921 0 "Highly Speculative" 1 "Speculative" 2 "Confident" 3 "Highly Confident" ;
VAL_TABLE_ Sig5920 0 "Unknown" 1 "Pedestrian" 2 "Bicycle" ;
VAL_TABLE_ Sig5959 0 "Stopped" 1 "Not Stopped" ;
VAL_TABLE_ Sig5958 0 "Has Never Moved" 1 "Moving In Same Direction As Host" 2 "Moving In Opposite Direction As Host" 3 "Crossing From Left To Right" 4 "Crossing From Right To Left" ;
VAL_TABLE_ Sig5957 0 "Highly Speculative" 1 "Speculative" 2 "Confident" 3 "Highly Confident" ;
VAL_TABLE_ Sig5961 0 "No Object" 1 "New Object" 2 "Latent Track Not Detected this Cycle" 3 "Measured this Cycle" ;
VAL_TABLE_ Sig5975 0 "Highly Speculative" 1 "Speculative" 2 "Confident" 3 "Highly Confident" ;
VAL_TABLE_ Sig6117 0 "Highly Speculative" 1 "Speculative" 2 "Confident" 3 "Highly Confident" ;
VAL_TABLE_ Sig6119 0 "Stopped" 1 "Not Stopped" ;
VAL_TABLE_ Sig6118 0 "Has Never Moved" 1 "Moving In Same Direction As Host" 2 "Moving In Opposite Direction As Host" 3 "Crossing From Left To Right" 4 "Crossing From Right To Left" ;
VAL_TABLE_ Sig6121 0 "No Object" 1 "New Object" 2 "Latent Track Not Detected this Cycle" 3 "Measured this Cycle" ;
VAL_TABLE_ Sig6135 0 "Highly Speculative" 1 "Speculative" 2 "Confident" 3 "Highly Confident" ;
VAL_TABLE_ Sig6139 0 "Stopped" 1 "Not Stopped" ;
VAL_TABLE_ Sig6138 0 "Has Never Moved" 1 "Moving In Same Direction As Host" 2 "Moving In Opposite Direction As Host" 3 "Crossing From Left To Right" 4 "Crossing From Right To Left" ;
VAL_TABLE_ Sig6137 0 "Highly Speculative" 1 "Speculative" 2 "Confident" 3 "Highly Confident" ;
VAL_TABLE_ Sig6141 0 "No Object" 1 "New Object" 2 "Latent Track Not Detected this Cycle" 3 "Measured this Cycle" ;
VAL_TABLE_ Sig6155 0 "Highly Speculative" 1 "Speculative" 2 "Confident" 3 "Highly Confident" ;
VAL_TABLE_ Sig5777 0 "Not Elevated" 1 "Elevation Speculative" 2 "Elevation Confident" 3 "Elevation Very Confident" ;
VAL_TABLE_ Sig5776 0 "Highly Speculative" 1 "Speculative" 2 "Confident" 3 "Highly Confident" ;
VAL_TABLE_ Sig5779 0 "No Object" 1 "New Object" 2 "Latent Track Not Detected this Cycle" 3 "Measured this Cycle" ;
VAL_TABLE_ Sig5783 0 "Highly Speculative" 1 "Speculative" 2 "Confident" 3 "Highly Confident" ;
VAL_TABLE_ Sig5782 0 "Unknown" 1 "Guard Rail" 2 "Tunnel" 3 "Traffic Sign" 4 "Bridge" 5 "Pole" ;
VAL_TABLE_ Sig5785 0 "Not Elevated" 1 "Elevation Speculative" 2 "Elevation Confident" 3 "Elevation Very Confident" ;
VAL_TABLE_ Sig5784 0 "Highly Speculative" 1 "Speculative" 2 "Confident" 3 "Highly Confident" ;
VAL_TABLE_ Sig5787 0 "No Object" 1 "New Object" 2 "Latent Track Not Detected this Cycle" 3 "Measured this Cycle" ;
VAL_TABLE_ Sig5792 0 "Highly Speculative" 1 "Speculative" 2 "Confident" 3 "Highly Confident" ;
VAL_TABLE_ Sig5791 0 "Highly Speculative" 1 "Speculative" 2 "Confident" 3 "Highly Confident" ;
VAL_TABLE_ Sig5790 0 "Unknown" 1 "Guard Rail" 2 "Tunnel" 3 "Traffic Sign" 4 "Bridge" 5 "Pole" ;
VAL_TABLE_ Sig5793 0 "Not Elevated" 1 "Elevation Speculative" 2 "Elevation Confident" 3 "Elevation Very Confident" ;
VAL_TABLE_ Sig5795 0 "No Object" 1 "New Object" 2 "Latent Track Not Detected this Cycle" 3 "Measured this Cycle" ;
VAL_TABLE_ Sig5798 0 "Unknown" 1 "Guard Rail" 2 "Tunnel" 3 "Traffic Sign" 4 "Bridge" 5 "Pole" ;
VAL_TABLE_ Sig5801 0 "Not Elevated" 1 "Elevation Speculative" 2 "Elevation Confident" 3 "Elevation Very Confident" ;
VAL_TABLE_ Sig5800 0 "Highly Speculative" 1 "Speculative" 2 "Confident" 3 "Highly Confident" ;
VAL_TABLE_ Sig5799 0 "Highly Speculative" 1 "Speculative" 2 "Confident" 3 "Highly Confident" ;
VAL_TABLE_ Sig5803 0 "No Object" 1 "New Object" 2 "Latent Track Not Detected this Cycle" 3 "Measured this Cycle" ;
VAL_TABLE_ Sig5807 0 "Highly Speculative" 1 "Speculative" 2 "Confident" 3 "Highly Confident" ;
VAL_TABLE_ Sig5806 0 "Unknown" 1 "Guard Rail" 2 "Tunnel" 3 "Traffic Sign" 4 "Bridge" 5 "Pole" ;
VAL_TABLE_ Sig5809 0 "Not Elevated" 1 "Elevation Speculative" 2 "Elevation Confident" 3 "Elevation Very Confident" ;
VAL_TABLE_ Sig5808 0 "Highly Speculative" 1 "Speculative" 2 "Confident" 3 "Highly Confident" ;
VAL_TABLE_ Sig5811 0 "No Object" 1 "New Object" 2 "Latent Track Not Detected this Cycle" 3 "Measured this Cycle" ;
VAL_TABLE_ Sig5817 0 "Not Elevated" 1 "Elevation Speculative" 2 "Elevation Confident" 3 "Elevation Very Confident" ;
VAL_TABLE_ Sig5816 0 "Highly Speculative" 1 "Speculative" 2 "Confident" 3 "Highly Confident" ;
VAL_TABLE_ Sig5815 0 "Highly Speculative" 1 "Speculative" 2 "Confident" 3 "Highly Confident" ;
VAL_TABLE_ Sig5814 0 "Unknown" 1 "Guard Rail" 2 "Tunnel" 3 "Traffic Sign" 4 "Bridge" 5 "Pole" ;
VAL_TABLE_ Sig5819 0 "No Object" 1 "New Object" 2 "Latent Track Not Detected this Cycle" 3 "Measured this Cycle" ;
VAL_TABLE_ Sig5822 0 "Unknown" 1 "Guard Rail" 2 "Tunnel" 3 "Traffic Sign" 4 "Bridge" 5 "Pole" ;
VAL_TABLE_ Sig5825 0 "Not Elevated" 1 "Elevation Speculative" 2 "Elevation Confident" 3 "Elevation Very Confident" ;
VAL_TABLE_ Sig5824 0 "Highly Speculative" 1 "Speculative" 2 "Confident" 3 "Highly Confident" ;
VAL_TABLE_ Sig5823 0 "Highly Speculative" 1 "Speculative" 2 "Confident" 3 "Highly Confident" ;
VAL_TABLE_ Sig5827 0 "No Object" 1 "New Object" 2 "Latent Track Not Detected this Cycle" 3 "Measured this Cycle" ;
VAL_TABLE_ Sig5832 0 "Highly Speculative" 1 "Speculative" 2 "Confident" 3 "Highly Confident" ;
VAL_TABLE_ Sig5831 0 "Highly Speculative" 1 "Speculative" 2 "Confident" 3 "Highly Confident" ;
VAL_TABLE_ Sig5830 0 "Unknown" 1 "Guard Rail" 2 "Tunnel" 3 "Traffic Sign" 4 "Bridge" 5 "Pole" ;
VAL_TABLE_ Sig5833 0 "Not Elevated" 1 "Elevation Speculative" 2 "Elevation Confident" 3 "Elevation Very Confident" ;
VAL_TABLE_ Sig5835 0 "No Object" 1 "New Object" 2 "Latent Track Not Detected this Cycle" 3 "Measured this Cycle" ;
VAL_TABLE_ Sig5838 0 "Unknown" 1 "Guard Rail" 2 "Tunnel" 3 "Traffic Sign" 4 "Bridge" 5 "Pole" ;
VAL_TABLE_ Sig5841 0 "Not Elevated" 1 "Elevation Speculative" 2 "Elevation Confident" 3 "Elevation Very Confident" ;
VAL_TABLE_ Sig5840 0 "Highly Speculative" 1 "Speculative" 2 "Confident" 3 "Highly Confident" ;
VAL_TABLE_ Sig5839 0 "Highly Speculative" 1 "Speculative" 2 "Confident" 3 "Highly Confident" ;
VAL_TABLE_ Sig5843 0 "No Object" 1 "New Object" 2 "Latent Track Not Detected this Cycle" 3 "Measured this Cycle" ;
VAL_TABLE_ Sig5847 0 "Highly Speculative" 1 "Speculative" 2 "Confident" 3 "Highly Confident" ;
VAL_TABLE_ Sig5846 0 "Unknown" 1 "Guard Rail" 2 "Tunnel" 3 "Traffic Sign" 4 "Bridge" 5 "Pole" ;
VAL_TABLE_ Sig5849 0 "Not Elevated" 1 "Elevation Speculative" 2 "Elevation Confident" 3 "Elevation Very Confident" ;
VAL_TABLE_ Sig5848 0 "Highly Speculative" 1 "Speculative" 2 "Confident" 3 "Highly Confident" ;
VAL_TABLE_ Sig5851 0 "No Object" 1 "New Object" 2 "Latent Track Not Detected this Cycle" 3 "Measured this Cycle" ;
VAL_TABLE_ Sig5855 0 "Highly Speculative" 1 "Speculative" 2 "Confident" 3 "Highly Confident" ;
VAL_TABLE_ Sig5854 0 "Unknown" 1 "Guard Rail" 2 "Tunnel" 3 "Traffic Sign" 4 "Bridge" 5 "Pole" ;
VAL_TABLE_ Sig5774 0 "Highly Speculative" 1 "Speculative" 2 "Confident" 3 "Highly Confident" ;
VAL_TABLE_ Sig5773 0 "FALSE" 1 "TRUE" ;
VAL_TABLE_ Sig5858 0 "Has Never Moved" 1 "Has Moved But Currently Stopped" 2 "Moving In Same Direction As Host" 3 "Moving In Opposite Direction As Host" 4 "Crossing Path" ;
VAL_TABLE_ Sig5857 0 "Highly Speculative" 1 "Speculative" 2 "Confident" 3 "Highly Confident" ;
VAL_TABLE_ Sig5856 0 "Not Radiating" 1 "Reporting Object Data" 2 "Not Reporting Object Data" ;
VAL_TABLE_ Sig5775 0 "Not Detected" 1 "Detected" 2 "Unknown" ;
VAL_TABLE_ Sig5861 0 "No Object" 1 "New Object" 2 "Latent Track Not Detected this Cycle" 3 "Measured this Cycle" ;
VAL_TABLE_ Sig5870 0 "Highly Speculative" 1 "Speculative" 2 "Confident" 3 "Highly Confident" ;
VAL_TABLE_ Sig5869 0 "Highly Speculative" 1 "Speculative" 2 "Confident" 3 "Highly Confident" ;
VAL_TABLE_ Sig5868 0 "Unknown" 1 "Pedestrian" 2 "Bicycle" ;
VAL_TABLE_ Sig5871 0 "Has Never Moved" 1 "Has Moved But Currently Stopped" 2 "Moving In Same Direction As Host" 3 "Moving In Opposite Direction As Host" 4 "Crossing Path" ;
VAL_TABLE_ Sig5874 0 "No Object" 1 "New Object" 2 "Latent Track Not Detected this Cycle" 3 "Measured this Cycle" ;
VAL_TABLE_ Sig5882 0 "Highly Speculative" 1 "Speculative" 2 "Confident" 3 "Highly Confident" ;
VAL_TABLE_ Sig5881 0 "Unknown" 1 "Pedestrian" 2 "Bicycle" ;
VAL_TABLE_ Sig5954 0 "FALSE" 1 "TRUE" ;
VAL_TABLE_ Sig5953 0 "FALSE" 1 "TRUE" ;
VAL_TABLE_ Sig5952 0 "FALSE" 1 "TRUE" ;
VAL_TABLE_ Sig5950 0 "Highly Speculative" 1 "Speculative" 2 "Confident" 3 "Highly Confident" ;
VAL_TABLE_ Sig5949 0 "Unknown" 1 "City" 2 "Secondary Road" 3 "Highway" 4 "Construction Zone Entry" 5 "Construction Zone Exit" ;
VAL_TABLE_ Sig5955 0 "Mode A" 1 "Mode B" 2 "Mode C" 3 "Mode D" ;
VAL_TABLE_ Sig5979 0 "Stopped" 1 "Not Stopped" ;
VAL_TABLE_ Sig5978 0 "Has Never Moved" 1 "Moving In Same Direction As Host" 2 "Moving In Opposite Direction As Host" 3 "Crossing From Left To Right" 4 "Crossing From Right To Left" ;
VAL_TABLE_ Sig5977 0 "Highly Speculative" 1 "Speculative" 2 "Confident" 3 "Highly Confident" ;
VAL_TABLE_ Sig5981 0 "No Object" 1 "New Object" 2 "Latent Track Not Detected this Cycle" 3 "Measured this Cycle" ;
VAL_TABLE_ Sig5995 0 "Highly Speculative" 1 "Speculative" 2 "Confident" 3 "Highly Confident" ;
VAL_TABLE_ Sig5922 0 "Highly Speculative" 1 "Speculative" 2 "Confident" 3 "Highly Confident" ;
VAL_TABLE_ Sig5930 0 "Highly Speculative" 1 "Speculative" 2 "Confident" 3 "Highly Confident" ;
VAL_TABLE_ Sig5929 0 "Unknown" 1 "Barriers" 2 "Guard Rails" 3 "Bridge Abutments" 4 "Edge of Road" 5 "Open Area" ;
VAL_TABLE_ Sig5931 0 "Highly Speculative" 1 "Speculative" 2 "Confident" 3 "Highly Confident" ;
VAL_TABLE_ Sig5939 0 "Highly Speculative" 1 "Speculative" 2 "Confident" 3 "Highly Confident" ;
VAL_TABLE_ Sig5938 0 "Unknown" 1 "Barriers" 2 "Guard Rails" 3 "Bridge Abutments" 4 "Edge of Road" 5 "Open Area" ;
VAL_TABLE_ Sig5940 0 "Highly Speculative" 1 "Speculative" 2 "Confident" 3 "Highly Confident" ;
VAL_TABLE_ Sig5948 0 "Highly Speculative" 1 "Speculative" 2 "Confident" 3 "Highly Confident" ;
VAL_TABLE_ Sig5947 0 "Unknown" 1 "Barriers" 2 "Guard Rails" 3 "Bridge Abutments" 4 "Edge of Road" 5 "Open Area" ;
VAL_TABLE_ Sig6317 0 "Has Never Moved" 1 "Has Moved But Currently Stopped" 2 "Moving In Same Direction As Host" 3 "Moving In Opposite Direction As Host" 4 "Crossing Path" ;
VAL_TABLE_ Sig6316 0 "Highly Speculative" 1 "Speculative" 2 "Confident" 3 "Highly Confident" ;
VAL_TABLE_ Sig6320 0 "No Object" 1 "New Object" 2 "Latent Track Not Detected this Cycle" 3 "Measured this Cycle" ;
VAL_TABLE_ Sig6328 0 "Highly Speculative" 1 "Speculative" 2 "Confident" 3 "Highly Confident" ;
VAL_TABLE_ Sig6327 0 "Unknown" 1 "Pedestrian" 2 "Bicycle" ;
VAL_TABLE_ Sig6470 0 "Stopped" 1 "Not Stopped" ;
VAL_TABLE_ Sig6469 0 "Has Never Moved" 1 "Moving In Same Direction As Host" 2 "Moving In Opposite Direction As Host" 3 "Crossing From Left To Right" 4 "Crossing From Right To Left" ;
VAL_TABLE_ Sig6468 0 "Highly Speculative" 1 "Speculative" 2 "Confident" 3 "Highly Confident" ;
VAL_TABLE_ Sig6472 0 "No Object" 1 "New Object" 2 "Latent Track Not Detected this Cycle" 3 "Measured this Cycle" ;
VAL_TABLE_ Sig6486 0 "Highly Speculative" 1 "Speculative" 2 "Confident" 3 "Highly Confident" ;
VAL_TABLE_ Sig6488 0 "Highly Speculative" 1 "Speculative" 2 "Confident" 3 "Highly Confident" ;
VAL_TABLE_ Sig6490 0 "Stopped" 1 "Not Stopped" ;
VAL_TABLE_ Sig6489 0 "Has Never Moved" 1 "Moving In Same Direction As Host" 2 "Moving In Opposite Direction As Host" 3 "Crossing From Left To Right" 4 "Crossing From Right To Left" ;
VAL_TABLE_ Sig6492 0 "No Object" 1 "New Object" 2 "Latent Track Not Detected this Cycle" 3 "Measured this Cycle" ;
VAL_TABLE_ Sig6506 0 "Highly Speculative" 1 "Speculative" 2 "Confident" 3 "Highly Confident" ;
VAL_TABLE_ Sig6510 0 "Stopped" 1 "Not Stopped" ;
VAL_TABLE_ Sig6509 0 "Has Never Moved" 1 "Moving In Same Direction As Host" 2 "Moving In Opposite Direction As Host" 3 "Crossing From Left To Right" 4 "Crossing From Right To Left" ;
VAL_TABLE_ Sig6508 0 "Highly Speculative" 1 "Speculative" 2 "Confident" 3 "Highly Confident" ;
VAL_TABLE_ Sig6512 0 "No Object" 1 "New Object" 2 "Latent Track Not Detected this Cycle" 3 "Measured this Cycle" ;
VAL_TABLE_ Sig6526 0 "Highly Speculative" 1 "Speculative" 2 "Confident" 3 "Highly Confident" ;
VAL_TABLE_ Sig6330 0 "Has Never Moved" 1 "Has Moved But Currently Stopped" 2 "Moving In Same Direction As Host" 3 "Moving In Opposite Direction As Host" 4 "Crossing Path" ;
VAL_TABLE_ Sig6329 0 "Highly Speculative" 1 "Speculative" 2 "Confident" 3 "Highly Confident" ;
VAL_TABLE_ Sig6333 0 "No Object" 1 "New Object" 2 "Latent Track Not Detected this Cycle" 3 "Measured this Cycle" ;
VAL_TABLE_ Sig6341 0 "Highly Speculative" 1 "Speculative" 2 "Confident" 3 "Highly Confident" ;
VAL_TABLE_ Sig6340 0 "Unknown" 1 "Pedestrian" 2 "Bicycle" ;
VAL_TABLE_ Sig6530 0 "Stopped" 1 "Not Stopped" ;
VAL_TABLE_ Sig6529 0 "Has Never Moved" 1 "Moving In Same Direction As Host" 2 "Moving In Opposite Direction As Host" 3 "Crossing From Left To Right" 4 "Crossing From Right To Left" ;
VAL_TABLE_ Sig6528 0 "Highly Speculative" 1 "Speculative" 2 "Confident" 3 "Highly Confident" ;
VAL_TABLE_ Sig6532 0 "No Object" 1 "New Object" 2 "Latent Track Not Detected this Cycle" 3 "Measured this Cycle" ;
VAL_TABLE_ Sig6546 0 "Highly Speculative" 1 "Speculative" 2 "Confident" 3 "Highly Confident" ;
VAL_TABLE_ Sig6548 0 "Highly Speculative" 1 "Speculative" 2 "Confident" 3 "Highly Confident" ;
VAL_TABLE_ Sig6550 0 "Stopped" 1 "Not Stopped" ;
VAL_TABLE_ Sig6549 0 "Has Never Moved" 1 "Moving In Same Direction As Host" 2 "Moving In Opposite Direction As Host" 3 "Crossing From Left To Right" 4 "Crossing From Right To Left" ;
VAL_TABLE_ Sig6552 0 "No Object" 1 "New Object" 2 "Latent Track Not Detected this Cycle" 3 "Measured this Cycle" ;
VAL_TABLE_ Sig6566 0 "Highly Speculative" 1 "Speculative" 2 "Confident" 3 "Highly Confident" ;
VAL_TABLE_ Sig6570 0 "Stopped" 1 "Not Stopped" ;
VAL_TABLE_ Sig6569 0 "Has Never Moved" 1 "Moving In Same Direction As Host" 2 "Moving In Opposite Direction As Host" 3 "Crossing From Left To Right" 4 "Crossing From Right To Left" ;
VAL_TABLE_ Sig6568 0 "Highly Speculative" 1 "Speculative" 2 "Confident" 3 "Highly Confident" ;
VAL_TABLE_ Sig6572 0 "No Object" 1 "New Object" 2 "Latent Track Not Detected this Cycle" 3 "Measured this Cycle" ;
VAL_TABLE_ Sig6586 0 "Highly Speculative" 1 "Speculative" 2 "Confident" 3 "Highly Confident" ;
VAL_TABLE_ Sig6343 0 "Has Never Moved" 1 "Has Moved But Currently Stopped" 2 "Moving In Same Direction As Host" 3 "Moving In Opposite Direction As Host" 4 "Crossing Path" ;
VAL_TABLE_ Sig6342 0 "Highly Speculative" 1 "Speculative" 2 "Confident" 3 "Highly Confident" ;
VAL_TABLE_ Sig6346 0 "No Object" 1 "New Object" 2 "Latent Track Not Detected this Cycle" 3 "Measured this Cycle" ;
VAL_TABLE_ Sig6354 0 "Highly Speculative" 1 "Speculative" 2 "Confident" 3 "Highly Confident" ;
VAL_TABLE_ Sig6353 0 "Unknown" 1 "Pedestrian" 2 "Bicycle" ;
VAL_TABLE_ Sig6430 0 "Stopped" 1 "Not Stopped" ;
VAL_TABLE_ Sig6429 0 "Has Never Moved" 1 "Moving In Same Direction As Host" 2 "Moving In Opposite Direction As Host" 3 "Crossing From Left To Right" 4 "Crossing From Right To Left" ;
VAL_TABLE_ Sig6428 0 "Highly Speculative" 1 "Speculative" 2 "Confident" 3 "Highly Confident" ;
VAL_TABLE_ Sig6432 0 "No Object" 1 "New Object" 2 "Latent Track Not Detected this Cycle" 3 "Measured this Cycle" ;
VAL_TABLE_ Sig6446 0 "Highly Speculative" 1 "Speculative" 2 "Confident" 3 "Highly Confident" ;
VAL_TABLE_ Sig6588 0 "Highly Speculative" 1 "Speculative" 2 "Confident" 3 "Highly Confident" ;
VAL_TABLE_ Sig6590 0 "Stopped" 1 "Not Stopped" ;
VAL_TABLE_ Sig6589 0 "Has Never Moved" 1 "Moving In Same Direction As Host" 2 "Moving In Opposite Direction As Host" 3 "Crossing From Left To Right" 4 "Crossing From Right To Left" ;
VAL_TABLE_ Sig6592 0 "No Object" 1 "New Object" 2 "Latent Track Not Detected this Cycle" 3 "Measured this Cycle" ;
VAL_TABLE_ Sig6606 0 "Highly Speculative" 1 "Speculative" 2 "Confident" 3 "Highly Confident" ;
VAL_TABLE_ Sig6610 0 "Stopped" 1 "Not Stopped" ;
VAL_TABLE_ Sig6609 0 "Has Never Moved" 1 "Moving In Same Direction As Host" 2 "Moving In Opposite Direction As Host" 3 "Crossing From Left To Right" 4 "Crossing From Right To Left" ;
VAL_TABLE_ Sig6608 0 "Highly Speculative" 1 "Speculative" 2 "Confident" 3 "Highly Confident" ;
VAL_TABLE_ Sig6612 0 "No Object" 1 "New Object" 2 "Latent Track Not Detected this Cycle" 3 "Measured this Cycle" ;
VAL_TABLE_ Sig6626 0 "Highly Speculative" 1 "Speculative" 2 "Confident" 3 "Highly Confident" ;
VAL_TABLE_ Sig6206 0 "Not Elevated" 1 "Elevation Speculative" 2 "Elevation Confident" 3 "Elevation Very Confident" ;
VAL_TABLE_ Sig6205 0 "Highly Speculative" 1 "Speculative" 2 "Confident" 3 "Highly Confident" ;
VAL_TABLE_ Sig6208 0 "No Object" 1 "New Object" 2 "Latent Track Not Detected this Cycle" 3 "Measured this Cycle" ;
VAL_TABLE_ Sig6212 0 "Highly Speculative" 1 "Speculative" 2 "Confident" 3 "Highly Confident" ;
VAL_TABLE_ Sig6211 0 "Unknown" 1 "Guard Rail" 2 "Tunnel" 3 "Traffic Sign" 4 "Bridge" 5 "Pole" ;
VAL_TABLE_ Sig6214 0 "Not Elevated" 1 "Elevation Speculative" 2 "Elevation Confident" 3 "Elevation Very Confident" ;
VAL_TABLE_ Sig6213 0 "Highly Speculative" 1 "Speculative" 2 "Confident" 3 "Highly Confident" ;
VAL_TABLE_ Sig6216 0 "No Object" 1 "New Object" 2 "Latent Track Not Detected this Cycle" 3 "Measured this Cycle" ;
VAL_TABLE_ Sig6221 0 "Highly Speculative" 1 "Speculative" 2 "Confident" 3 "Highly Confident" ;
VAL_TABLE_ Sig6220 0 "Highly Speculative" 1 "Speculative" 2 "Confident" 3 "Highly Confident" ;
VAL_TABLE_ Sig6219 0 "Unknown" 1 "Guard Rail" 2 "Tunnel" 3 "Traffic Sign" 4 "Bridge" 5 "Pole" ;
VAL_TABLE_ Sig6222 0 "Not Elevated" 1 "Elevation Speculative" 2 "Elevation Confident" 3 "Elevation Very Confident" ;
VAL_TABLE_ Sig6224 0 "No Object" 1 "New Object" 2 "Latent Track Not Detected this Cycle" 3 "Measured this Cycle" ;
VAL_TABLE_ Sig6227 0 "Unknown" 1 "Guard Rail" 2 "Tunnel" 3 "Traffic Sign" 4 "Bridge" 5 "Pole" ;
VAL_TABLE_ Sig6230 0 "Not Elevated" 1 "Elevation Speculative" 2 "Elevation Confident" 3 "Elevation Very Confident" ;
VAL_TABLE_ Sig6229 0 "Highly Speculative" 1 "Speculative" 2 "Confident" 3 "Highly Confident" ;
VAL_TABLE_ Sig6228 0 "Highly Speculative" 1 "Speculative" 2 "Confident" 3 "Highly Confident" ;
VAL_TABLE_ Sig6232 0 "No Object" 1 "New Object" 2 "Latent Track Not Detected this Cycle" 3 "Measured this Cycle" ;
VAL_TABLE_ Sig6236 0 "Highly Speculative" 1 "Speculative" 2 "Confident" 3 "Highly Confident" ;
VAL_TABLE_ Sig6235 0 "Unknown" 1 "Guard Rail" 2 "Tunnel" 3 "Traffic Sign" 4 "Bridge" 5 "Pole" ;
VAL_TABLE_ Sig6238 0 "Not Elevated" 1 "Elevation Speculative" 2 "Elevation Confident" 3 "Elevation Very Confident" ;
VAL_TABLE_ Sig6237 0 "Highly Speculative" 1 "Speculative" 2 "Confident" 3 "Highly Confident" ;
VAL_TABLE_ Sig6240 0 "No Object" 1 "New Object" 2 "Latent Track Not Detected this Cycle" 3 "Measured this Cycle" ;
VAL_TABLE_ Sig6246 0 "Not Elevated" 1 "Elevation Speculative" 2 "Elevation Confident" 3 "Elevation Very Confident" ;
VAL_TABLE_ Sig6245 0 "Highly Speculative" 1 "Speculative" 2 "Confident" 3 "Highly Confident" ;
VAL_TABLE_ Sig6244 0 "Highly Speculative" 1 "Speculative" 2 "Confident" 3 "Highly Confident" ;
VAL_TABLE_ Sig6243 0 "Unknown" 1 "Guard Rail" 2 "Tunnel" 3 "Traffic Sign" 4 "Bridge" 5 "Pole" ;
VAL_TABLE_ Sig6248 0 "No Object" 1 "New Object" 2 "Latent Track Not Detected this Cycle" 3 "Measured this Cycle" ;
VAL_TABLE_ Sig6251 0 "Unknown" 1 "Guard Rail" 2 "Tunnel" 3 "Traffic Sign" 4 "Bridge" 5 "Pole" ;
VAL_TABLE_ Sig6254 0 "Not Elevated" 1 "Elevation Speculative" 2 "Elevation Confident" 3 "Elevation Very Confident" ;
VAL_TABLE_ Sig6253 0 "Highly Speculative" 1 "Speculative" 2 "Confident" 3 "Highly Confident" ;
VAL_TABLE_ Sig6252 0 "Highly Speculative" 1 "Speculative" 2 "Confident" 3 "Highly Confident" ;
VAL_TABLE_ Sig6256 0 "No Object" 1 "New Object" 2 "Latent Track Not Detected this Cycle" 3 "Measured this Cycle" ;
VAL_TABLE_ Sig6261 0 "Highly Speculative" 1 "Speculative" 2 "Confident" 3 "Highly Confident" ;
VAL_TABLE_ Sig6260 0 "Highly Speculative" 1 "Speculative" 2 "Confident" 3 "Highly Confident" ;
VAL_TABLE_ Sig6259 0 "Unknown" 1 "Guard Rail" 2 "Tunnel" 3 "Traffic Sign" 4 "Bridge" 5 "Pole" ;
VAL_TABLE_ Sig6262 0 "Not Elevated" 1 "Elevation Speculative" 2 "Elevation Confident" 3 "Elevation Very Confident" ;
VAL_TABLE_ Sig6264 0 "No Object" 1 "New Object" 2 "Latent Track Not Detected this Cycle" 3 "Measured this Cycle" ;
VAL_TABLE_ Sig6267 0 "Unknown" 1 "Guard Rail" 2 "Tunnel" 3 "Traffic Sign" 4 "Bridge" 5 "Pole" ;
VAL_TABLE_ Sig6270 0 "Not Elevated" 1 "Elevation Speculative" 2 "Elevation Confident" 3 "Elevation Very Confident" ;
VAL_TABLE_ Sig6269 0 "Highly Speculative" 1 "Speculative" 2 "Confident" 3 "Highly Confident" ;
VAL_TABLE_ Sig6268 0 "Highly Speculative" 1 "Speculative" 2 "Confident" 3 "Highly Confident" ;
VAL_TABLE_ Sig6272 0 "No Object" 1 "New Object" 2 "Latent Track Not Detected this Cycle" 3 "Measured this Cycle" ;
VAL_TABLE_ Sig6276 0 "Highly Speculative" 1 "Speculative" 2 "Confident" 3 "Highly Confident" ;
VAL_TABLE_ Sig6275 0 "Unknown" 1 "Guard Rail" 2 "Tunnel" 3 "Traffic Sign" 4 "Bridge" 5 "Pole" ;
VAL_TABLE_ Sig6278 0 "Not Elevated" 1 "Elevation Speculative" 2 "Elevation Confident" 3 "Elevation Very Confident" ;
VAL_TABLE_ Sig6277 0 "Highly Speculative" 1 "Speculative" 2 "Confident" 3 "Highly Confident" ;
VAL_TABLE_ Sig6280 0 "No Object" 1 "New Object" 2 "Latent Track Not Detected this Cycle" 3 "Measured this Cycle" ;
VAL_TABLE_ Sig6284 0 "Highly Speculative" 1 "Speculative" 2 "Confident" 3 "Highly Confident" ;
VAL_TABLE_ Sig6283 0 "Unknown" 1 "Guard Rail" 2 "Tunnel" 3 "Traffic Sign" 4 "Bridge" 5 "Pole" ;
VAL_TABLE_ Sig6202 0 "Highly Speculative" 1 "Speculative" 2 "Confident" 3 "Highly Confident" ;
VAL_TABLE_ Sig6201 0 "FALSE" 1 "TRUE" ;
VAL_TABLE_ Sig6291 0 "Has Never Moved" 1 "Has Moved But Currently Stopped" 2 "Moving In Same Direction As Host" 3 "Moving In Opposite Direction As Host" 4 "Crossing Path" ;
VAL_TABLE_ Sig6290 0 "Highly Speculative" 1 "Speculative" 2 "Confident" 3 "Highly Confident" ;
VAL_TABLE_ Sig6285 0 "Not Radiating" 1 "Reporting Object Data" 2 "Not Reporting Object Data" ;
VAL_TABLE_ Sig6203 0 "Not Detected" 1 "Detected" 2 "Unknown" ;
VAL_TABLE_ Sig6294 0 "No Object" 1 "New Object" 2 "Latent Track Not Detected this Cycle" 3 "Measured this Cycle" ;
VAL_TABLE_ Sig6303 0 "Highly Speculative" 1 "Speculative" 2 "Confident" 3 "Highly Confident" ;
VAL_TABLE_ Sig6302 0 "Highly Speculative" 1 "Speculative" 2 "Confident" 3 "Highly Confident" ;
VAL_TABLE_ Sig6301 0 "Unknown" 1 "Pedestrian" 2 "Bicycle" ;
VAL_TABLE_ Sig6304 0 "Has Never Moved" 1 "Has Moved But Currently Stopped" 2 "Moving In Same Direction As Host" 3 "Moving In Opposite Direction As Host" 4 "Crossing Path" ;
VAL_TABLE_ Sig6307 0 "No Object" 1 "New Object" 2 "Latent Track Not Detected this Cycle" 3 "Measured this Cycle" ;
VAL_TABLE_ Sig6315 0 "Highly Speculative" 1 "Speculative" 2 "Confident" 3 "Highly Confident" ;
VAL_TABLE_ Sig6314 0 "Unknown" 1 "Pedestrian" 2 "Bicycle" ;
VAL_TABLE_ Sig6387 0 "FALSE" 1 "TRUE" ;
VAL_TABLE_ Sig6386 0 "FALSE" 1 "TRUE" ;
VAL_TABLE_ Sig6385 0 "FALSE" 1 "TRUE" ;
VAL_TABLE_ Sig6383 0 "Highly Speculative" 1 "Speculative" 2 "Confident" 3 "Highly Confident" ;
VAL_TABLE_ Sig6382 0 "Unknown" 1 "City" 2 "Secondary Road" 3 "Highway" 4 "Construction Zone Entry" 5 "Construction Zone Exit" ;
VAL_TABLE_ Sig6388 0 "Mode A" 1 "Mode B" 2 "Mode C" 3 "Mode D" ;
VAL_TABLE_ Sig6450 0 "Stopped" 1 "Not Stopped" ;
VAL_TABLE_ Sig6449 0 "Has Never Moved" 1 "Moving In Same Direction As Host" 2 "Moving In Opposite Direction As Host" 3 "Crossing From Left To Right" 4 "Crossing From Right To Left" ;
VAL_TABLE_ Sig6448 0 "Highly Speculative" 1 "Speculative" 2 "Confident" 3 "Highly Confident" ;
VAL_TABLE_ Sig6452 0 "No Object" 1 "New Object" 2 "Latent Track Not Detected this Cycle" 3 "Measured this Cycle" ;
VAL_TABLE_ Sig6466 0 "Highly Speculative" 1 "Speculative" 2 "Confident" 3 "Highly Confident" ;
VAL_TABLE_ Sig6355 0 "Highly Speculative" 1 "Speculative" 2 "Confident" 3 "Highly Confident" ;
VAL_TABLE_ Sig6363 0 "Highly Speculative" 1 "Speculative" 2 "Confident" 3 "Highly Confident" ;
VAL_TABLE_ Sig6362 0 "Unknown" 1 "Barriers" 2 "Guard Rails" 3 "Bridge Abutments" 4 "Edge of Road" 5 "Open Area" ;
VAL_TABLE_ Sig6364 0 "Highly Speculative" 1 "Speculative" 2 "Confident" 3 "Highly Confident" ;
VAL_TABLE_ Sig6372 0 "Highly Speculative" 1 "Speculative" 2 "Confident" 3 "Highly Confident" ;
VAL_TABLE_ Sig6371 0 "Unknown" 1 "Barriers" 2 "Guard Rails" 3 "Bridge Abutments" 4 "Edge of Road" 5 "Open Area" ;
VAL_TABLE_ Sig6373 0 "Highly Speculative" 1 "Speculative" 2 "Confident" 3 "Highly Confident" ;
VAL_TABLE_ Sig6381 0 "Highly Speculative" 1 "Speculative" 2 "Confident" 3 "Highly Confident" ;
VAL_TABLE_ Sig6380 0 "Unknown" 1 "Barriers" 2 "Guard Rails" 3 "Bridge Abutments" 4 "Edge of Road" 5 "Open Area" ;
VAL_TABLE_ EGI1P_PtclFiltClnAlgActAuth_DuD 0 "FALSE" 1 "TRUE" ;
VAL_TABLE_ EGI1P_PtclFiltClnAlgActAuth 0 "FALSE" 1 "TRUE" ;
VAL_TABLE_ EGI5P_EngStlSvrActvAuth 0 "FALSE" 1 "TRUE" ;
VAL_TABLE_ EGI5P_ECDIntlRngSnsrPWAuth_Inv 0 "FALSE" 1 "TRUE" ;
VAL_TABLE_ EGIP_EngActlStdyStatTrqAuth_Inv 0 "FALSE" 1 "TRUE" ;
VAL_TABLE_ EGIP_EngNTransRegSSTrqAuth_Inv 0 "FALSE" 1 "TRUE" ;
VAL_TABLE_ E44BRP_HillDscntCtlSwStsAuth 0 "No Action" 1 "Increment" 2 "Decrement" 3 "Faulted" ;
VAL_TABLE_ ESP_EngSpdStAuth 0 "Normal_Operation" 1 "Degraded_Operation" 2 "Invalid" ;
VAL_TABLE_ E49RmtEngStrtReqAuth 0 "PTO Remote Start Not Requested" 1 "PTO Remote Start Requested" ;
VAL_TABLE_ E49RmtEngShtdnReqdAuth 0 "FALSE" 1 "TRUE" ;
VAL_TABLE_ EngNonTransRegSSTrqER_Inv 0 "FALSE" 1 "TRUE" ;
VAL_TABLE_ DMSDrvrDrwLvlCnfdLvl 0 "0" 1 "1" 2 "2" 3 "3" 4 "4" 5 "5" 6 "6" 7 "7" ;
VAL_TABLE_ DMSDrvrDrwLvl 0 "0" 1 "1" 2 "2" 3 "3" 4 "4" 5 "5" 6 "6" 7 "7" 8 "8" 9 "9" ;
VAL_TABLE_ Sig1073 0 "FALSE" 1 "TRUE" ;
VAL_TABLE_ Sig1074 0 "FALSE" 1 "TRUE" ;
VAL_TABLE_ AATP_ActAxlTrqAuth_Inv 0 "FALSE" 1 "TRUE" ;
VAL_TABLE_ AEPP_AccEffcPosAuth_Inv 0 "FALSE" 1 "TRUE" ;
VAL_TABLE_ DRCDNDP_DRCAvgDrvnRstOccAuth 0 "FALSE" 1 "TRUE" ;
VAL_TABLE_ DRCDNDP_DRCAvgDrvnAuth_Inv 0 "FALSE" 1 "TRUE" ;
VAL_TABLE_ DRCDNDP_DRCAvgDrvnSrcAuth 0 "Transmission Output Speed" 1 "Wheel Speed" ;
VAL_TABLE_ DRCDNDP_DRCAvgNonDrvnRstOccAuth 0 "FALSE" 1 "TRUE" ;
VAL_TABLE_ DRCDNDP_DRCAvgNonDrvnAuth_Inv 0 "FALSE" 1 "TRUE" ;
VAL_TABLE_ DRCDNDP_PwrtrnRunAbrtdAuth 0 "FALSE" 1 "TRUE" ;
VAL_TABLE_ E44BRP_PTAutoBrkgReqActvAuth 0 "FALSE" 1 "TRUE" ;
VAL_TABLE_ PBP_PTSndBrkPdlPsAuth_Inv 0 "FALSE" 1 "TRUE" ;
VAL_TABLE_ PSATDP_ATDstTrqCmdSecAuth_Inv 0 "FALSE" 1 "TRUE" ;
VAL_TABLE_ PSATIP_ATDstTqCmdPriImmAuth_Inv 0 "FALSE" 1 "TRUE" ;
VAL_TABLE_ PSATIP_CmndATRespTypAuth 0 "Inactive" 1 "Pleasability Limited Request" 2 "Maximum Range Request" 3 "Automatic Actuator Selection" ;
VAL_TABLE_ PSATIP_PriATActlAuth_Inv 0 "FALSE" 1 "TRUE" ;
VAL_TABLE_ PSATIP_PriATReqStsAdvdTracAuth 0 "No Request" 1 "Request Honored" 2 "Lost Arbitration" 3 "Serial Data Failure Temporary" 4 "Serial Data Failure Permanent" 5 "Control System Failure Temporary" 6 "Control System Failure Permanent" ;
VAL_TABLE_ PSATDP_SecATReqStsAdvdTracAuth 0 "No Request" 1 "Request Honored" 2 "Lost Arbitration" 3 "Serial Data Failure Temporary" 4 "Serial Data Failure Permanent" 5 "Control System Failure Temporary" 6 "Control System Failure Permanent" ;
VAL_TABLE_ DIATMNP_DrvrIntdAxlTqMnAuth_Inv 0 "FALSE" 1 "TRUE" ;
VAL_TABLE_ DIATMXP_DrvrIntdAxlTqMxAuth_Inv 0 "FALSE" 1 "TRUE" ;
VAL_TABLE_ DITP_DrvrIntndAxlTrqAuth_Inv 0 "FALSE" 1 "TRUE" ;
VAL_TABLE_ VMI1P_AccelPedOvrrdActvAuth 0 "FALSE" 1 "TRUE" ;
VAL_TABLE_ VMI1P_AccelActlPstnAuth_Inv 0 "FALSE" 1 "TRUE" ;
VAL_TABLE_ VMI1P_VehTopSpdLimModeActvAuth 0 "FALSE" 1 "TRUE" ;
VAL_TABLE_ BVSCRP_BdyCtlTpSpdLimRspTypAuth 0 "Inactive" 1 "Faulted" 2 "Safety_woBrake" 3 "Safety_wBrake" 4 "OBD" 5 "nonOBD" 6 "Legislated" ;
VAL_TABLE_ BVSCRP_ACCAxlTrqCmdReqStsAuth 0 "No Request" 1 "Request Honored" 2 "Lost Arbitration" 3 "Request Denied" 4 "Request Suspended Till Driver Input" ;
VAL_TABLE_ BVSCRP_ACCAxlTrqCmdLimStsAuth 0 "Request Not Limited" 1 "Request Value Limited Minimum" 2 "Request Value Limited Maximum" 3 "Request Rate Limited" ;
VAL_TABLE_ BVSCRP_CPSAxlTrqCmdReqStsAuth 0 "No Request" 1 "Request Honored" 2 "Lost Arbitration" 3 "Serial Data Failure Temporary" 4 "Serial Data Failure Permanent" 5 "Control System Failure Temporary" 6 "Control System Failure Permanent" ;
VAL_TABLE_ BVSCRP_CPSAxlTrqCmdLimStsAuth 0 "Request Not Limited" 1 "Request Value Limited to Minimum" 2 "Request Value Limited to Maximum" 3 "Request Rate Limited" ;
VAL_TABLE_ CnvntlCruzCtlIndReqAuth 0 "No Action" 1 "Cruise Control Telltale Off" 2 "Cruise Control Unavailable Telltale On" 3 "Cruise Control White Telltale On" 4 "Cruise Control Green Telltale On" 5 "Cruise Control Blue Telltale On" ;
VAL_TABLE_ BVSCRP_CruzCtlEnbldAuth 0 "FALSE" 1 "TRUE" ;
VAL_TABLE_ BVSCRP_CltchPdlActPosAuth_Inv 0 "FALSE" 1 "TRUE" ;
VAL_TABLE_ CruzCtlActvAuth 0 "FALSE" 1 "TRUE" ;
VAL_TABLE_ DrSeltdSpdLmtrAutoMdSpLmStsAuth 0 "No Set Speed Change" 1 "Proposed Speed Limit Change" 2 "Accepted Speed Limit Change" 3 "Declined Speed Limit Change" ;
VAL_TABLE_ EGI2P_DrvrReqdAxlTrqIncrAuth 0 "FALSE" 1 "TRUE" ;
VAL_TABLE_ DrSeltdSpdLmtrSetTypActvAuth 0 "Off" 1 "Manual" 2 "Auto" 3 "Reserved" ;
VAL_TABLE_ DrSeltdSpdLmtrSetSpdLimRchdAuth 0 "No Limit Reached" 1 "High Limit Reached" 2 "Low Limit Reached" 3 "Reserved" ;
VAL_TABLE_ E44BRP_VehTopSpdLimArbdStatAuth 0 "Torque" 1 "Torque & Friction Brake" 2 "Inactive" ;
VAL_TABLE_ EGI2P_PwrtrnCrnkActvAuth 0 "FALSE" 1 "TRUE" ;
VAL_TABLE_ EGI2P_DrvrReqdAxlTrqValAuth_Inv 0 "FALSE" 1 "TRUE" ;
VAL_TABLE_ SpdLmtrSpdLimSgnUntAuth 0 "km/h" 1 "mph" ;
VAL_TABLE_ SuprRmtPrkPrplSysResp 0 "Standby" 1 "Torque Request Honored" 2 "Arbitration Failed" 3 "Failed" ;
VAL_TABLE_ EGI3P_CnvtTpSpLimRspTypAuth 0 "Inactive" 1 "Faulted" 2 "Safety_woBrake" 3 "Safety_wBrake" 4 "OBD" 5 "nonOBD" 6 "Legislated" ;
VAL_TABLE_ PSP_PrkNeutSwStatAuth_Inv 0 "FALSE" 1 "TRUE" ;
VAL_TABLE_ PSP_PrkNeutSwStatAuth 0 "Park/Neutral" 1 "Not Park/Neutral" ;
VAL_TABLE_ PSP_EngRnngAuth 0 "FALSE" 1 "TRUE" ;
VAL_TABLE_ PSP_ClchBtmTrvlAchvdAuth_Inv 0 "FALSE" 1 "TRUE" ;
VAL_TABLE_ PSP_ClchBtmTrvlAchvdAuth 0 "FALSE" 1 "TRUE" ;
VAL_TABLE_ PSP_VehTheftImbChlgRespStsAuth 0 "Undetermined" 1 "Pass" 2 "Fail" ;
VAL_TABLE_ PSP_RmtVehStrtEngRnngAuth 0 "FALSE" 1 "TRUE" ;
VAL_TABLE_ PSP_PwrtrnCrnkAbrtdAuth 0 "FALSE" 1 "TRUE" ;
VAL_TABLE_ PSP_PrplSysStlActvAuth 0 "FALSE" 1 "TRUE" ;
VAL_TABLE_ PSP_PrplSysActvAuth 0 "FALSE" 1 "TRUE" ;
VAL_TABLE_ PrplBrkThrotOvrrdReqd 0 "FALSE" 1 "TRUE" ;
VAL_TABLE_ AE44LtSftBtnReq 0 "Hidden" 1 "Disabled" 2 "Enabled" 3 "Highlighted" ;
VAL_TABLE_ AE44ExtPrkSftBtnReq 0 "Hidden" 1 "Disabled" 2 "Enabled" 3 "Highlighted" ;
VAL_TABLE_ AE44CrsFrtInSftBtnReq 0 "Hidden" 1 "Disabled" 2 "Enabled" 3 "Highlighted" ;
VAL_TABLE_ AE44CrsBkInSftBtnReq 0 "Hidden" 1 "Disabled" 2 "Enabled" 3 "Highlighted" ;
VAL_TABLE_ AE44SrchingSftBtnReq 0 "Hidden" 1 "Disabled" 2 "Enabled" 3 "Highlighted" ;
VAL_TABLE_ AE44RtSftBtnReq 0 "Hidden" 1 "Disabled" 2 "Enabled" 3 "Highlighted" ;
VAL_TABLE_ AE44PrllPrkSftBtnReq 0 "Hidden" 1 "Disabled" 2 "Enabled" 3 "Highlighted" ;
VAL_TABLE_ VOBP_VehOdoBkupAuth_Inv 0 "FALSE" 1 "TRUE" ;
VAL_TABLE_ OATP_OtsAirTmpAuth_Inv 0 "FALSE" 1 "TRUE" ;
VAL_TABLE_ OATP_OtsAirTmpSrcAuth 0 "Sensor_Value" 1 "Estimated_Value" ;
VAL_TABLE_ OATP_OtsAirTmpCrValStAuth 0 "Normal_Operation" 1 "Degraded_Operation" ;
VAL_TABLE_ OATP_OtsAirTmpCrValAuth_Inv 0 "FALSE" 1 "TRUE" ;
VAL_TABLE_ ETRPP_ElcTransRngPriAuth 0 "NO_REQUEST" 1 "PARK" 2 "REVERSE" 3 "NEUTRAL" 4 "DRIVE" 5 "LOW_RANGE" 6 "MANUAL_RANGE" ;
VAL_TABLE_ ESAE44CP_ElecShfAE44CtlStsAuth 0 "Stand by" 1 "Shift In Progress" 2 "Manual Override" 3 "Error" ;
VAL_TABLE_ ESAE44CP_ElecShfAE44CtlStsAtvAut 0 "FALSE" 1 "TRUE" ;
VAL_TABLE_ HGI1P_SecEngCmptAjrAuth 0 "FALSE" 1 "TRUE" ;
VAL_TABLE_ E44BRP_ElecShfAutoBrkgReqdAuth 0 "Braking Not Requested" 1 "Braking Requested" ;
VAL_TABLE_ E44BRP_ElecShfAutoBrkgReqTypAuth 0 "None" 1 "Release" 2 "Hold Allow Driver Release" 3 "Hold Deny Driver Release" ;
VAL_TABLE_ HGI1P_SecEngCmptAjrAuth_Inv 0 "FALSE" 1 "TRUE" ;
VAL_TABLE_ LDGI1_ECMClrLgslDiagInfo 0 "FALSE" 1 "TRUE" ;
VAL_TABLE_ EngWrmUpAch 0 "FALSE" 1 "TRUE" ;
VAL_TABLE_ EGI4_PrplSysOffTm_Inv 0 "FALSE" 1 "TRUE" ;
VAL_TABLE_ EGI4_PrplSysOffTm_DuD 0 "FALSE" 1 "TRUE" ;
VAL_TABLE_ LgslPstDTCClrDrvCyCmp 0 "FALSE" 1 "TRUE" ;
VAL_TABLE_ LgslDiagMxEngCltTmpRchd 0 "FALSE" 1 "TRUE" ;
VAL_TABLE_ LDGI1_LgslDiagStdCondsMet 0 "FALSE" 1 "TRUE" ;
VAL_TABLE_ LDGI1_LgslDiagStdCondsFltPr 0 "FALSE" 1 "TRUE" ;
VAL_TABLE_ LDGI1_LgslDiagMinEngClTmpRchd 0 "FALSE" 1 "TRUE" ;
VAL_TABLE_ LDGI1_LgslDiagCldStrtCondsMet 0 "FALSE" 1 "TRUE" ;
VAL_TABLE_ LDGI1_LgslDiagCldStrtCondsFltPr 0 "FALSE" 1 "TRUE" ;
VAL_TABLE_ RCIP_PwrRrClsrMtnCmdAuth 0 "No_Action" 1 "Release" 2 "Start Motion" 3 "Stop Motion" ;
VAL_TABLE_ RCIP_ExtRrClsrRelReqAuth 0 "Unknown" 1 "Inactive" 2 "Active" 3 "Faulted" ;
VAL_TABLE_ BGI1P_OutsdAmbtLgtLvlStsAuth 0 "Unknown" 1 "Day" 2 "Night" ;
VAL_TABLE_ BGI1P_DrvrDrOpnStsAuth_Inv 0 "FALSE" 1 "TRUE" ;
VAL_TABLE_ BGI1P_DrvrDrOpnStsAuth_DuD 0 "FALSE" 1 "TRUE" ;
VAL_TABLE_ BGI1P_DrvrDrOpnStsAuth 0 "FALSE" 1 "TRUE" ;
VAL_TABLE_ PwrRrClsrModeSeltn 0 "Disabled" 1 "Fully Open" 2 "Garage" ;
VAL_TABLE_ RCIP_RrClsrMtnCtlParmEnblAuth 0 "FALSE" 1 "TRUE" ;
VAL_TABLE_ RCIP_PwrRrClsrMtnReqrAuth 0 "No Request" 1 "Active Remote Keyfob" 2 "Passive Remote Keyfob" 3 "Shutface Switch" 4 "Exterior Switch" 5 "Interior Switch" 6 "Handfree Kick Switch" ;
VAL_TABLE_ E49RmtStrtMstrEngShtdnReqdAuth 0 "FALSE" 1 "TRUE" ;
VAL_TABLE_ FrtStrgeCmptExtRelReqAuth 0 "Inactive" 1 "Active" ;
VAL_TABLE_ FrtStrgeCmptClsrLckSts 0 "Unknown" 1 "Unlocked" 2 "Locked" ;
VAL_TABLE_ RrStrgModeSwStsAuth 0 "Unknown" 1 "Not Pressed" 2 "Pressed" 3 "Failed" ;
VAL_TABLE_ PwrFrtStrgeCmptMtnReqrAuth 0 "No Request" 1 "Active Remote Keyfob" 2 "Exterior Switch" 3 "Interior Switch" 4 "Entrapment Switch" ;
VAL_TABLE_ PwrFrtStrgeCmptMtnCmdAuth 0 "No Action" 1 "Release To Ajar" 2 "Release To Open" 3 "Start Motion" 4 "Stop Motion" ;
VAL_TABLE_ E49RmtStrtMstrEngStrtReqAuth 0 "PTO Remote Start Not Requested" 1 "PTO Remote Start Requested" ;
VAL_TABLE_ TGIP_TrnsEgdPrFlwStAuth 0 "Unavailable" 1 "No Powerflow" 2 "Drive Engaged" 3 "Reverse Engaged" ;
VAL_TABLE_ TARSP_TransActlRngAuth_Inv 0 "FALSE" 1 "TRUE" ;
VAL_TABLE_ TARSP_TransActlRngAuth_DuD 0 "FALSE" 1 "TRUE" ;
VAL_TABLE_ TARSP_TransActlRngAuth 0 "Unknown Position" 1 "Park Position" 2 "Between Park and Reverse" 3 "Reverse Position" 4 "Between Reverse and Neutral" 5 "Neutral Position" 6 "Between Neutral and First Drive Position" 7 "First Drive Position" 8 "Between First and Second Drive Position" 9 "Second Drive Position" 10 "Between Second and Third Position" 11 "Third Drive Position" 12 "Between Third and Fourth Position" 13 "Fourth Drive Position" ;
VAL_TABLE_ TRDP_TrnsPkRgDgLtFltAuth 0 "FALSE" 1 "TRUE" ;
VAL_TABLE_ TRDP_TrnsPkRgDgCtFltAuth 0 "FALSE" 1 "TRUE" ;
VAL_TABLE_ TRDP_TrnsNtRgDgLtFltAuth 0 "FALSE" 1 "TRUE" ;
VAL_TABLE_ TRDP_TrnsNtRgDgCtFltAuth 0 "FALSE" 1 "TRUE" ;
VAL_TABLE_ TRDP_TrnsFwDrvRDLFltAuth 0 "FALSE" 1 "TRUE" ;
VAL_TABLE_ TRDP_TrnsFwDrvRDCFltAuth 0 "FALSE" 1 "TRUE" ;
VAL_TABLE_ TGIP_TrnsEgdPrFlwStAuth_Inv 0 "FALSE" 1 "TRUE" ;
VAL_TABLE_ TSP_TmpDrvrShfCtlActvAuth 0 "FALSE" 1 "TRUE" ;
VAL_TABLE_ TSP_ElecRngSeltnInDrvActvAuth 0 "FALSE" 1 "TRUE" ;
VAL_TABLE_ TRDP_TrnsRvRgDgLtFltAuth 0 "FALSE" 1 "TRUE" ;
VAL_TABLE_ TRDP_TrnsRvRgDgCtFltAuth 0 "FALSE" 1 "TRUE" ;
VAL_TABLE_ HVGI3P_HVBNegChsGndVltgAuth_Inv 0 "FALSE" 1 "TRUE" ;
VAL_TABLE_ HVGI3P_HVBNegChsGndVltgAuth_DuD 0 "FALSE" 1 "TRUE" ;
VAL_TABLE_ HVGI3P_HVBPosChsGndVltgAuth_Inv 0 "FALSE" 1 "TRUE" ;
VAL_TABLE_ HVGI3P_HVBPosChsGndVltgAuth_DuD 0 "FALSE" 1 "TRUE" ;
VAL_TABLE_ HVGI3P_HVPsvIsltnStsAuth 0 "Undetermined" 1 "Passed" 2 "Failed" ;
VAL_TABLE_ HVGI3P_HVIRatlzdVltgPriAuth_Inv 0 "FALSE" 1 "TRUE" ;
VAL_TABLE_ HVGI3P_PwrtrnHVShtdnCmpltdAuth 0 "FALSE" 1 "TRUE" ;
VAL_TABLE_ HVGI3P_PwrtrnHVCntctrReqPriAuth 0 "Undetermined" 1 "Close Allowed" 2 "Request Open" ;
VAL_TABLE_ PSATDP_SecATActlAuth_Inv 0 "FALSE" 1 "TRUE" ;
VAL_TABLE_ HVGI9P_ESSPrplSysReqPriAuth 0 "Idle" 1 "Activate" 2 "Deactivate" 3 "ImmedDeactivate" 4 "Suspended" ;
VAL_TABLE_ ASDRP_LnCntrWrnExtdIndReqAuth 0 "No Indication" 1 "Can Not See Lanes" 2 "Tight Curve" 3 "Freeway Ends" 4 "Construction" 5 "Excessive Speed" 6 "Vehicles Proximity" 7 "Unavailable" 8 "Attention Unknown" 9 "Due to Weather" 10 "Take Steering" 11 "Take Vehicle Control" 12 "Service Driver Assist System" 13 "Lane Following Locked Out" 14 "Reserved 1" 15 "Lane Ending" 16 "Exit Lane" 17 "GM Authority" 18 "Vehicle Setting" 19 "Adaptive Cruise" 20 "Controlled Access" 21 "Driver Attention Off Road" 22 "GPS Unavailable" 23 "Driver Action" 24 "Vehicle Center" 25 "Sensor Impaired" 26 "Opening Left" 27 "Opening Right" 28 "Changing Left" 29 "Changing Right" 30 "Complete Left" 31 "Complete Right" 32 "Unable Left" 33 "Unable Right" 34 "Cancelled Left" 35 "Cancelled Right" 36 "Timed Out Left" 37 "Timed Out Right" 38 "Trailer Narrow Lane" 39 "Trailer Dimensions" 40 "Trailer Braking" 41 "Trailer Overloaded" 42 "Trailer Stability" 43 "Subscription Required" ;
VAL_TABLE_ ASDRP_LnCntrCtlIndReqAuth 0 "Indication Off" 1 "White Indicator" 2 "Green Indicator" 3 "Yellow Indicator" 4 "Red Indicator" 5 "Blue Indicator" ;
VAL_TABLE_ ACGIP_SrrndVsnRLSModeCmdAuth 0 "Not Reporting Lane Data" 1 "Reporting Lane Data" ;
VAL_TABLE_ ACGIP_LnFllwFltIndcdAtBrkEnAuth 0 "FALSE" 1 "TRUE" ;
VAL_TABLE_ HMIR1P_LnFllwgLHSChEvntStatAuth 0 "No Action" 1 "Active" 2 "Cancel Chime" ;
VAL_TABLE_ HMIR1P_LnFllwgGenChEvntStatAuth 0 "No Action" 1 "Active" 2 "Cancel Chime" ;
VAL_TABLE_ ASTIP_LnCntrVehStopdAuth 0 "FALSE" 1 "TRUE" ;
VAL_TABLE_ HMIR1P_LnFllwgRHSChEvntStatAuth 0 "No Action" 1 "Active" 2 "Cancel Chime" ;
VAL_TABLE_ ACCATRIP_TrqDrvAstGoStatAuth 0 "Not Stopped" 1 "Apply Accel Pedal to Go" 2 "Apply Accel Pedal or Resume Switch to Go" 3 "Automatic Resume Pending" ;
VAL_TABLE_ ACCATRIP_TrqActvAuth 0 "FALSE" 1 "TRUE" ;
VAL_TABLE_ ACCATRIP_TrqTypAuth 0 "Adaptive Cruise Control" 1 "Full Speed Range ACC" 2 "Full Speed Range ACC with Booster" 3 "Full Speed Range ACC with Lane Centering Control" ;
VAL_TABLE_ ACCBRP_ReqActvAuth 0 "FALSE" 1 "TRUE" ;
VAL_TABLE_ ACCBRP_ACCActvAuth 0 "FALSE" 1 "TRUE" ;
VAL_TABLE_ ACCBRP_ReqTypAuth 0 "Unknown" 1 "No_Braking" 2 "Brake_Per_Decel_Request" 3 "Open_Loop_Brake_to_Stop" 4 "Apply_Park_Brake" 5 "Hold" 6 "Prefill Request" ;
VAL_TABLE_ ClsnImntBrkgAxlTrqRqActvAuth 0 "FALSE" 1 "TRUE" ;
VAL_TABLE_ LCCPIP_LnCntrCtlActvAuth 0 "FALSE" 1 "TRUE" ;
VAL_TABLE_ LCCPIP_LnCntrCtlAclPedLimRqAuth 0 "FALSE" 1 "TRUE" ;
VAL_TABLE_ DSIDP_DrvrStrgIntfrDtdAuth_Inv 0 "FALSE" 1 "TRUE" ;
VAL_TABLE_ DSIDP_DrvrStrgIntfrDtdAuth 0 "FALSE" 1 "TRUE" ;
VAL_TABLE_ DASTP_StrTrqAuth_Inv 0 "FALSE" 1 "TRUE" ;
VAL_TABLE_ EPSOP_ElecPwStrgTqOvlyStsAuth 0 "Unknown" 1 "Temporarily Inhibited" 2 "Inactive" 3 "Active" 4 "Temporarily Limited" 5 "Failed" ;
VAL_TABLE_ EPSOP_EPSOvrlyTrqDlvdAuth_Inv 0 "FALSE" 1 "TRUE" ;
VAL_TABLE_ SSASI2P_LKAStrgRqCommStsAuth 0 "Unknown" 1 "Normal Active" 2 "Normal Inactive" 3 "Failed Communication" ;
VAL_TABLE_ SSASI2P_ArbdASStrgRqCommStsAuth 0 "Unknown" 1 "Normal Communication Request Active" 2 "Normal Communication Request Active Fault Pending" 3 "Normal Communication Request Inactive" 4 "Normal Communication Request Inactive Fault Pending" 5 "Failed Communication" ;
VAL_TABLE_ SSASI2P_AE44StrgRqCommStsAuth 0 "Unknown" 1 "Normal Active" 2 "Normal Inactive" 3 "Failed Communication" ;
VAL_TABLE_ EPSTTDP_TotTorqDlvdAuth_Inv 0 "FALSE" 1 "TRUE" ;
VAL_TABLE_ SSASIP_StrgPerfActlModeAuth 0 "No Action" 1 "Normal" 2 "Sport" 3 "Comfort" 4 "Track" 5 "Tow_Haul" 6 "Offroad" 7 "Terrain" ;
VAL_TABLE_ SSASIP_StrgAsstThrmlInhbdAuth 0 "FALSE" 1 "TRUE" ;
VAL_TABLE_ SSASIP_StrgAsstStsAuth 0 "Normal" 1 "Reduced" 2 "Unavailable" ;
VAL_TABLE_ SWHOP_ArbdStrgFtrReqActvAuth 0 "None" 1 "ESC" 2 "APA" 3 "LKA" 4 "LCC" 5 "TJA" 6 "HOLF" 7 "LCP" 8 "SAA" 9 "CAS" 10 "LCOD" ;
VAL_TABLE_ SSASIP_StrgWhlTrqIntegStsAuth 0 "Unknown" 1 "Redundant ASIL D" 2 "Non Redundant ASIL D" 3 "Failed" ;
VAL_TABLE_ SSASIP_StrgWhlAngIntegStsAuth 0 "Unknown" 1 "Redundant ASIL D" 2 "Non Redundant ASIL D" 3 "Failed" ;
VAL_TABLE_ SWHOP_StrgWhlHndsOffDtnStatAuth 0 "Hands On" 1 "Hands Off" 2 "Unknown" ;
VAL_TABLE_ SWHOP_StrgWhlHndsOffDtnModeAuth 0 "Disabled" 1 "Enabled" 2 "Failed" 3 "Unknown" ;
VAL_TABLE_ SWHOP_StrgWhlHndsOffDtnCnfdLvlAu 0 "Low" 1 "High" 2 "Unknown" ;
VAL_TABLE_ Sig0319 0 "Unknown" 1 "Temporarily Inhibited" 2 "Inactive" 3 "Active" 4 "Temporarily Limited" 5 "Failed" 6 "Backup Command" 7 "Hold Last Value" ;
VAL_TABLE_ Sig0313 0 "Unknown" 1 "Normal Communication Request Active" 2 "Normal Communication Request Active Fault Pending" 3 "Normal Communication Request Inactive" 4 "Normal Communication Request Inctive Fault Pending" 5 "Failed Communication" ;
VAL_TABLE_ Sig0325 0 "Normal" 1 "Reduced" 2 "Failed" 3 "Off" ;
VAL_TABLE_ Sig0322 0 "Normal" 1 "Reduced" 2 "Failed" 3 "Off" ;
VAL_TABLE_ Sig6953 0 "Normal Operation" 1 "Degraded 1" 2 "Degraded 2" 3 "Degraded 3" 4 "Degraded 4" 5 "Degraded 5" ;
VAL_TABLE_ Sig0318 0 "FALSE" 1 "TRUE" ;
VAL_TABLE_ Sig0316 0 "FALSE" 1 "TRUE" ;
VAL_TABLE_ Sig0314 0 "FALSE" 1 "TRUE" ;
VAL_TABLE_ Sig6956 0 "Unknown" 1 "Internal Communication Available" 2 "Internal Communication Unavailable" ;
VAL_TABLE_ Sig0328 0 "Unknown" 1 "Redundant ASIL D" 2 "Non Redundant ASIL D" 3 "Failed" ;
VAL_TABLE_ Sig2545 0 "FALSE" 1 "TRUE" ;
VAL_TABLE_ Sig0326 0 "FALSE" 1 "TRUE" ;
VAL_TABLE_ Sig0324 0 "FALSE" 1 "TRUE" ;
VAL_TABLE_ Sig0321 0 "FALSE" 1 "TRUE" ;
VAL_TABLE_ BVSCP_BdyCtlTopSpdLimReqTypAuth 0 "Inactive" 1 "Faulted" 2 "Safety_woBrake" 3 "Safety_wBrake" 4 "OBD" 5 "nonOBD" 6 "Legislated" ;
VAL_TABLE_ BGI4P_AutoShtdnRstAuth 0 "FALSE" 1 "TRUE" ;
VAL_TABLE_ BGI4P_AutoShtdnAllwdAuth 0 "FALSE" 1 "TRUE" ;
VAL_TABLE_ BGI4P_AirDflctOffCycCrTkStAuth 0 "Inactive" 1 "NotPresent" 2 "PartCreditTmrMode" 3 "FullCreditTmrMode" ;
VAL_TABLE_ BASHPLP_BrkSnsrHmPstnLrndAuth 0 "FALSE" 1 "TRUE" ;
VAL_TABLE_ DSIP_E44MSw3StkAuth 0 "FALSE" 1 "TRUE" ;
VAL_TABLE_ DSIP_E44MSw2StkAuth 0 "FALSE" 1 "TRUE" ;
VAL_TABLE_ DSIP_E44MSw1StkAuth 0 "FALSE" 1 "TRUE" ;
VAL_TABLE_ BdyCtlTopSpdLimSrcAuth 0 "None" 1 "Teen" 2 "Valet" 3 "HoodOpen" 4 "Reserved" 5 "Reserved" 6 "Reserved" 7 "Reserved" ;
VAL_TABLE_ BdyCtlTopSpdLimIndOnAuth 0 "FALSE" 1 "TRUE" ;
VAL_TABLE_ BdyCtlAccelLimIndOnAuth 0 "FALSE" 1 "TRUE" ;
VAL_TABLE_ RIP_FrtCmptRelEnblReqAuth 0 "Not Enabled" 1 "Entrapment Release To Ajar" 2 "Normal Release To Open" 3 "Entrapment Release To Open" ;
VAL_TABLE_ DSIP_E44MSwStsAuth 0 "No Active Switches" 1 "Switch 1 Active" 2 "Switch 2 Active" 3 "Switch 3 Active" 4 "Switch 4 Active" 5 "2WD High Switch Long Press" 6 "AWD Active Switch Long Press" 7 "Critical Analog Fault" ;
VAL_TABLE_ DSIP_E44MSwDrvrModeSwStkAuth 0 "FALSE" 1 "TRUE" ;
VAL_TABLE_ DSIP_E44MSw4StkAuth 0 "FALSE" 1 "TRUE" ;
VAL_TABLE_ LoVltg12VBatMntModeReqd 0 "FALSE" 1 "TRUE" ;
VAL_TABLE_ LSCMBABP_ReqActvAuth 0 "FALSE" 1 "TRUE" ;
VAL_TABLE_ RLDWCTOP_TrqOvrlyActAuth_Inv 0 "FALSE" 1 "TRUE" ;
VAL_TABLE_ RLDWCTOP_TrqOvrlyActAuth_DuD 0 "FALSE" 1 "TRUE" ;
VAL_TABLE_ RLDWCTOP_TrqOvrlyActAuth 0 "ACTIVE" 1 "INACTIVE" ;
VAL_TABLE_ LSCMBABP_TypAuth 0 "None" 1 "Brake to Commanded Decel" 2 "Hold" ;
VAL_TABLE_ RLDWCTOP_TrqOvrlyValAuth_DuD 0 "FALSE" 1 "TRUE" ;
VAL_TABLE_ RLDWCTOP_TrqOvrlyValAuth_Inv 0 "FALSE" 1 "TRUE" ;
VAL_TABLE_ HMIGI2P_LnFllwgInterFltDtdAuth 0 "FALSE" 1 "TRUE" ;
VAL_TABLE_ HMIGI2P_IPCFlrIndOnAuth 0 "FALSE" 1 "TRUE" ;
VAL_TABLE_ HMIGI1P_TrlrBrkDispActvAuth_DuD 0 "FALSE" 1 "TRUE" ;
VAL_TABLE_ HMIGI1P_TrlrBrkDispActvAuth 0 "FALSE" 1 "TRUE" ;
VAL_TABLE_ HMIGI1P_EnvModPrsntRspdr4Auth 0 "FALSE" 1 "TRUE" ;
VAL_TABLE_ CTGI1P_CnvtTpSpLimRqTypAuth 0 "Inactive" 1 "Faulted" 2 "Safety_woBrake" 3 "Safety_wBrake" 4 "OBD" 5 "nonOBD" 6 "Legislated" ;
VAL_TABLE_ CnvtTopModSpdLimIndOnAuth 0 "FALSE" 1 "TRUE" ;
VAL_TABLE_ SSID1P_LatAccelAuth_Inv 0 "FALSE" 1 "TRUE" ;
VAL_TABLE_ SSID1P_LngAccelAuth_Inv 0 "FALSE" 1 "TRUE" ;
VAL_TABLE_ SSID2P_PtchRateAuth_Inv 0 "FALSE" 1 "TRUE" ;
VAL_TABLE_ SSID2P_VertAccelAuth_Inv 0 "FALSE" 1 "TRUE" ;
VAL_TABLE_ SSID3P_RollRateAuth_Inv 0 "FALSE" 1 "TRUE" ;
VAL_TABLE_ SSID3P_YawRateAuth_Inv 0 "FALSE" 1 "TRUE" ;
VAL_TABLE_ SSID4P_LFAuth_Inv 0 "FALSE" 1 "TRUE" ;
VAL_TABLE_ SSID4P_RFAuth_Inv 0 "FALSE" 1 "TRUE" ;
VAL_TABLE_ SSID5P_LRAuth_Inv 0 "FALSE" 1 "TRUE" ;
VAL_TABLE_ SSID5P_RRAuth_Inv 0 "FALSE" 1 "TRUE" ;
VAL_TABLE_ LatAccelSnsrCorrStsAuth 0 "Unknown" 1 "NA" 2 "Correlated" 3 "Uncorellated" ;
VAL_TABLE_ LatAccelAuth_Inv 0 "FALSE" 1 "TRUE" ;
VAL_TABLE_ LongAccelAuth_Inv 0 "FALSE" 1 "TRUE" ;
VAL_TABLE_ VehAccelCalAuth 0 "FALSE" 1 "TRUE" ;
VAL_TABLE_ LongAccelSnsrCorrStsAuth 0 "Unknown" 1 "NA" 2 "Correlated" 3 "Uncorellated" ;
VAL_TABLE_ YRP_RollRateAuth_Inv 0 "FALSE" 1 "TRUE" ;
VAL_TABLE_ YRP_RollRateAuth_DuD 0 "FALSE" 1 "TRUE" ;
VAL_TABLE_ YawRateAuth_DuD 0 "FALSE" 1 "TRUE" ;
VAL_TABLE_ YawRateCorrAuth 0 "Unknown" 1 "NA" 2 "Correlated" 3 "Uncorellated" ;
VAL_TABLE_ YawRateAuth_Inv 0 "FALSE" 1 "TRUE" ;
VAL_TABLE_ VehAccelAuth_DuD 0 "FALSE" 1 "TRUE" ;
VAL_TABLE_ Sig7523 0 "No Request" 1 "Maximum Limit" 2 "Minimum Limit" ;
VAL_TABLE_ Sig7526 0 "No_Request" 1 "Maximum_Limit" 2 "Minimum_Limit" ;
VAL_TABLE_ Sig7525 0 "Inactive" 1 "PleasabilityLimited" 2 "MaximumRange" 3 "AutomaticActuatorSelection" ;
VAL_TABLE_ Sig7531 0 "No Intervention" 1 "Engine Speed Max Limit" 2 "Engine Speed Min Limit" 3 "Engine Speed Max and Min Limit" ;
VAL_TABLE_ Sig7530 0 "No_Suggestion" 1 "Transient_Optimized" 2 "Stability_Optimized_Condition_1" 3 "Stability_Optimized_Condition_2" ;
VAL_TABLE_ TGIP_TransGrRatStatAuth 0 "Inactive" 1 "Normal" 2 "Theoretical" 3 "Torque Phase Ratio Active" 4 "Alternate Sensors in Use" 5 "Invalid" ;
VAL_TABLE_ TGIP_TransGrRatAuth_Inv 0 "FALSE" 1 "TRUE" ;
VAL_TABLE_ Sig7548 0 "Single Edge Sensor" 1 "Rising Transition" 2 "Falling Transition" 3 "Undefined" ;
VAL_TABLE_ Sig7551 0 "FALSE" 1 "TRUE" ;
VAL_TABLE_ Sig7550 0 "FALSE" 1 "TRUE" ;
VAL_TABLE_ TORSP_TransOutRotnDirAuth 0 "Unknown" 1 "Forward" 2 "Reverse" 3 "Undefined" ;
VAL_TABLE_ Sig7574 0 "FALSE" 1 "TRUE" ;
VAL_TABLE_ Sig7573 0 "Crank Not Permitted" 1 "Crank Permitted" ;
VAL_TABLE_ Sig7572 0 "FALSE" 1 "TRUE" ;
VAL_TABLE_ Sig7571 0 "Crank Not Permitted" 1 "Crank Permitted" ;
VAL_TABLE_ Sig7576 0 "FALSE" 1 "TRUE" ;
VAL_TABLE_ Sig7634 0 "FALSE" 1 "TRUE" ;
VAL_TABLE_ Sig7633 0 "FALSE" 1 "TRUE" ;
VAL_TABLE_ Sig7581 0 "No Intervention" 1 "Engine Speed Max Limit" 2 "Engine Speed Min Limit" 3 "Engine Speed Max and Min Limit" ;
VAL_TABLE_ Sig7580 0 "No Suggestion" 1 "Transient Optimized" 2 "Stability Optimized Condition 1" 3 "Stability Optimized Condition 2" ;
VAL_TABLE_ Sig7623 0 "No Request" 1 "Maximum Limit" 2 "Minimum Limit" ;
VAL_TABLE_ Sig7626 0 "No Request" 1 "Maximum Limit" 2 "Minimum Limit" ;
VAL_TABLE_ Sig7624 0 "Inactive" 1 "Pleasability Limited" 2 "Maximum Range" 3 "Automatic Actuator Selection" ;
VAL_TABLE_ VICMI3P_AccPPS1OORFltAuth 0 "FALSE" 1 "TRUE" ;
VAL_TABLE_ VICMI3P_AccPPS1OORErrCmpstAuth 0 "FALSE" 1 "TRUE" ;
VAL_TABLE_ EDActr4DischrgCmdAuth 0 "No Action" 1 "Normal" 2 "Immediate" 3 "Emergency" ;
VAL_TABLE_ EDActr3DischrgCmdAuth 0 "No Action" 1 "Normal" 2 "Immediate" 3 "Emergency" ;
VAL_TABLE_ VICMI3P_AccPPS2OORFltCmpstAuth 0 "FALSE" 1 "TRUE" ;
VAL_TABLE_ VICMI3P_AccPPS2OORErrCmpstAuth 0 "FALSE" 1 "TRUE" ;
VAL_TABLE_ VICMI3P_AccPPS1n2DsgrFltAuth 0 "FALSE" 1 "TRUE" ;
VAL_TABLE_ VICMI3P_AccPPS1n2DsgrErrAuth 0 "FALSE" 1 "TRUE" ;
VAL_TABLE_ VICMI3P_AccPPS1OORFltCmpstAuth 0 "FALSE" 1 "TRUE" ;
VAL_TABLE_ VICMI3P_ArbdAccPPRedntFltAuth 0 "FALSE" 1 "TRUE" ;
VAL_TABLE_ ElecTransRngHVBkupSplyFltPrAuth 0 "FALSE" 1 "TRUE" ;
VAL_TABLE_ PrplSysInvrtACoolTempAuth_Inv 0 "FALSE" 1 "TRUE" ;
VAL_TABLE_ PrplSysInvrtBCoolTempAuth_Inv 0 "FALSE" 1 "TRUE" ;
VAL_TABLE_ PrplSysInvrtCCoolTempAuth_Inv 0 "FALSE" 1 "TRUE" ;
VAL_TABLE_ PrplSysMtrASpdAuth_Inv 0 "FALSE" 1 "TRUE" ;
VAL_TABLE_ RrStrgActlModeAuth 0 "Automatic" 1 "Fixed" 2 "Crab" 3 "None" ;
VAL_TABLE_ RrStrgOprtlStsAuth 0 "Unknown" 1 "Normal" 2 "Temporarily Unavailable" 3 "Reduced Performance" 4 "Failed" 5 "Normal & Active Safety Control" 6 "Reserved" ;
VAL_TABLE_ RrStrgAlgnCmpltAuth 0 "FALSE" 1 "TRUE" ;
VAL_TABLE_ RrStrgActlPerfMode 0 "No Action" 1 "Normal" 2 "Sport" 3 "Comfort" 4 "Track" 5 "Tow/Haul" 6 "City/Offroad" 7 "Terrain" ;
VAL_TABLE_ RrStrgRdWhlAngAuth_Inv 0 "FALSE" 1 "TRUE" ;
VAL_TABLE_ RrStrgRdWhlAngAuth_DuD 0 "FALSE" 1 "TRUE" ;
VAL_TABLE_ LIB1DS1_DTCSts 0 "Not Supported" 1 "No Status to Report" 2 "Diagnostic Passed" 3 "Diagnostic Failed" ;
VAL_TABLE_ LIB1DS2_DTCSts 0 "Not Supported" 1 "No Status to Report" 2 "Diagnostic Passed" 3 "Diagnostic Failed" ;
VAL_TABLE_ LIB1DS3_DTCSts 0 "Not Supported" 1 "No Status to Report" 2 "Diagnostic Passed" 3 "Diagnostic Failed" ;
VAL_TABLE_ ArbdStrgFtrReqActvAuth 0 "None" 1 "ESC" 2 "APA" 3 "LKA" 4 "LCC" 5 "TJA" 6 "HOLF" 7 "LCP" 8 "SAA" 9 "CAS" 10 "LCOD" ;
VAL_TABLE_ DrvrAppStrgTrqAuth_Inv 0 "FALSE" 1 "TRUE" ;
VAL_TABLE_ StrgWhlHndsOffDtnStatAuth 0 "Hands On" 1 "Hands Off" 2 "Unknown" ;
VAL_TABLE_ StrgWhlHndsOffDtnModeAuth 0 "Disabled" 1 "Enabled" 2 "Failed" 3 "Unknown" ;
VAL_TABLE_ StrgWhlHndsOffDtnCnfdLvlAuth 0 "Low" 1 "High" 2 "Unknown" ;
VAL_TABLE_ DrvrStrgIntfrDtdAuth_Inv 0 "FALSE" 1 "TRUE" ;
VAL_TABLE_ DrvrStrgIntfrDtdAuth 0 "FALSE" 1 "TRUE" ;
VAL_TABLE_ ArbdActvSftyStrgReqCommStsAuth 0 "Unknown" 1 "Normal Communication Request Active" 2 "Normal Communication Request Active Fault Pending" 3 "Normal Communication Request Inactive" 4 "Normal Communication Request Inactive Fault Pending" 5 "Failed Communication" ;
VAL_TABLE_ AE44StrgReqCommStsAuth 0 "Unknown" 1 "Normal Active" 2 "Normal Inactive" 3 "Failed Communication" ;
VAL_TABLE_ LnKpAsstStrgReqCommStsAuth 0 "Unknown" 1 "Normal Active" 2 "Normal Inactive" 3 "Failed Communication" ;
VAL_TABLE_ ElecPSTrqOvrlyStsAuth 0 "Unknown" 1 "Temporarily Inhibited" 2 "Inactive" 3 "Active" 4 "Temporarily Limited" 5 "Failed" ;
VAL_TABLE_ ElecPSOvrlyTrqDlvdAuth_Inv 0 "FALSE" 1 "TRUE" ;
VAL_TABLE_ ElecPSTotTrqDlvdAuth_Inv 0 "FALSE" 1 "TRUE" ;
VAL_TABLE_ StrgPerfActlModeAuth 0 "No Action" 1 "Normal" 2 "Sport" 3 "Comfort" 4 "Track" 5 "Tow_Haul" 6 "Offroad" 7 "Terrain" ;
VAL_TABLE_ StrgAsstThrmlInhbdAuth 0 "FALSE" 1 "TRUE" ;
VAL_TABLE_ StrgAsstStsAuth 0 "Normal" 1 "Reduced" 2 "Unavailable" ;
VAL_TABLE_ StrgWhlTrqIntegStsAuth 0 "Unknown" 1 "Redundant ASIL D" 2 "Non Redundant ASIL D" 3 "Failed" ;
VAL_TABLE_ StrgWhlAngIntegStsAuth 0 "Unknown" 1 "Redundant ASIL D" 2 "Non Redundant ASIL D" 3 "Failed" ;
VAL_TABLE_ TDAP_TeenDrvrActvAuth 0 "FALSE" 1 "TRUE" ;
VAL_TABLE_ RIP_RmtIgnBlkImbCustClrCmdAuth 0 "FALSE" 1 "TRUE" ;
VAL_TABLE_ RIP_NewFobXmtrLrndNtfnAuth 0 "FALSE" 1 "TRUE" ;
VAL_TABLE_ FTPP_VirtCtlHdPrkLmpsAvalAuth 0 "Not Available" 1 "Available" ;
VAL_TABLE_ FTPP_HdPrkLmpsCurrSeltnValAuth 0 "Unknown" 1 "Off" 2 "Auto" 3 "Parking" 4 "On" ;
VAL_TABLE_ VMMP_VehMtnMvmtStatAuth 0 "Parked" 1 "Neutral" 2 "Forward" 3 "Reverse" 4 "Invalid" ;
VAL_TABLE_ VKI2P_FobAvlStsAuth 0 "No Action" 1 "Disabled" 2 "Enabled" 3 "Fail" ;
VAL_TABLE_ AuthIntrUserIdDevSts 0 "Idle" 1 "Auth In Process" 2 "Auth In Process_Single Authenticated" 3 "Auth Complete_Not Authenticated" 4 "Auth Complete_Authenticated" 5 "Auth Complete_Undetermined" ;
VAL_TABLE_ E49ModeActv 0 "FALSE" 1 "TRUE" ;
VAL_TABLE_ RrStrgModeDispIndReq 0 "None" 1 "Automatic" 2 "Fixed" 3 "Crab" 4 "Crab Pending" 5 "Crab Ready" ;
VAL_TABLE_ RrStrgFlrIndOn 0 "FALSE" 1 "TRUE" ;
VAL_TABLE_ PnCActnReqCertfctTypAuth 0 "None" 1 "GM Provisioning Certificate" 2 "Contract Certificate" 3 "V2G Root Certificate" 4 "OCSP Certificate" 5 "Private Operator Root Certificate" 6 "Reserved1" 7 "Reserved2" 8 "Reserved3" 9 "Reserved4" 10 "Reserved5" 11 "Reserved6" 12 "Reserved7" 13 "Reserved8" 14 "All Contract And Private Operator Root Certificates" ;
VAL_TABLE_ PnCActnReqCertfctOpAuth 0 "No Action" 1 "Disable Certificate" 2 "Enable Certificate" 3 "Erase Certificate" 4 "Install Certificate" ;
VAL_TABLE_ PnCEnblReqAuth 0 "Unknown" 1 "No Action" 2 "Enable" 3 "Disable" ;
VAL_TABLE_ CCCGI_FrtBlwFanSpdFdbkRtlzd_Inv 0 "FALSE" 1 "TRUE" ;
VAL_TABLE_ ClmCtlCbnFrtEvpCoolPwrReq_DuD 0 "FALSE" 1 "TRUE" ;
VAL_TABLE_ ClmCtlCbnRecircAirFlapPstn_Inv 0 "FALSE" 1 "TRUE" ;
VAL_TABLE_ RmtProgPstInstlClnupActvAuth 0 "FALSE" 1 "TRUE" ;
VAL_TABLE_ RmtProgInstlPndgActvAuth 0 "FALSE" 1 "TRUE" ;
VAL_TABLE_ SuprRmtPrkVirtKeyPrkCmdAuth 0 "No Action" 1 "Initiate Parking" 2 "Pause Parking" 3 "Continue Parking" 4 "Resume Parking" 5 "Continue Unparking" ;
VAL_TABLE_ SuprRmtPrkVirtKeyEntlmtStsAuth 0 "Not Granted" 1 "Granted" ;
VAL_TABLE_ VirtKeyMblDevLocZnAuth 0 "No Action" 1 "Inside Vehicle" 2 "Outside and Within Localization Area" 3 "Outside of Localization Area" 4 "Invalid" ;
VAL_TABLE_ Sig4931 0 "FALSE" 1 "TRUE" ;
VAL_TABLE_ Sig4930 0 "FALSE" 1 "TRUE" ;
VAL_TABLE_ SWIP_StrgWhlAngAuth_DuD 0 "FALSE" 1 "TRUE" ;
VAL_TABLE_ SWIP_StrgWhlAngCalStsAuth 0 "Unknown" 1 "Estimated" 2 "Calibrated" ;
VAL_TABLE_ SWIP_StrgWhlAngAuth_Inv 0 "FALSE" 1 "TRUE" ;
VAL_TABLE_ RIP_PreRelAllwdAuth 0 "FALSE" 1 "TRUE" ;
VAL_TABLE_ RIP_ElecStrgColUnlckAllwdAuth 0 "FALSE" 1 "TRUE" ;
VAL_TABLE_ BGI1P_RmtVehStrtReqAuth 0 "FALSE" 1 "TRUE" ;
VAL_TABLE_ BGI1P_RmtStrtStsAuth 0 "Inactive" 1 "Active" ;
VAL_TABLE_ SPMP_PriRunCrnkCmdActvAuth 0 "FALSE" 1 "TRUE" ;
VAL_TABLE_ RIP_StrtStopIgnSwPrssdAuth 0 "FALSE" 1 "TRUE" ;
VAL_TABLE_ RIP_StrtStopIgnSwPrssdAuth_Inv 0 "FALSE" 1 "TRUE" ;
VAL_TABLE_ SPMP_SysPwrModeAuth_Inv 0 "FALSE" 1 "TRUE" ;
VAL_TABLE_ SPMP_SysPwrModeAuth 0 "Off" 1 "Accessory" 2 "Run" 3 "Start Request" 4 "Propulsion" ;
VAL_TABLE_ SPMP_PriRunCrnkCmdActvAuth_Inv 0 "FALSE" 1 "TRUE" ;
VAL_TABLE_ Sig7516 0 "FALSE" 1 "TRUE" ;
VAL_TABLE_ Sig7517 0 "FALSE" 1 "TRUE" ;
VAL_TABLE_ TGPSDSP_UTCMonthAuth 0 "Unknown" 1 "January" 2 "February" 3 "March" 4 "April" 5 "May" 6 "June" 7 "July" 8 "August" 9 "September" 10 "October" 11 "November" 12 "December" ;
VAL_TABLE_ TGPSDSP_UTCDyAuth_Inv 0 "FALSE" 1 "TRUE" ;
VAL_TABLE_ TGPSDSP_UTCMonthAuth_Inv 0 "FALSE" 1 "TRUE" ;
VAL_TABLE_ TGPSDSP_DateSrcAuth 0 "Signal_Unavailable" 1 "Synchronized_RTC_Used_And_GPS_Unavailable" 2 "GPS" 3 "Cellular" ;
VAL_TABLE_ TGPSDSP_UTCYrAuth_Inv 0 "FALSE" 1 "TRUE" ;
VAL_TABLE_ TGPSDSP_DateSrcAuth_Inv 0 "FALSE" 1 "TRUE" ;
VAL_TABLE_ TGPSTSP_TmSrcAuth_Inv 0 "FALSE" 1 "TRUE" ;
VAL_TABLE_ TGPSTSP_TmSrcAuth 0 "Signal_Unavailable" 1 "Synchronized_RTC_Used_And_GPS_Unavailable" 2 "GPS" 3 "Cellular" ;
VAL_TABLE_ TGPSTSP_UTCHrsAuth_Inv 0 "FALSE" 1 "TRUE" ;
VAL_TABLE_ TGPSTSP_UTCSecsAuth_Inv 0 "FALSE" 1 "TRUE" ;
VAL_TABLE_ TGPSTSP_UTCMinsAuth_Inv 0 "FALSE" 1 "TRUE" ;
VAL_TABLE_ TEGP_TrnsEstGrAuth 0 "Not Supported" 1 "First Gear" 2 "Second Gear" 3 "Third Gear" 4 "Fourth Gear" 5 "Fifth Gear" 6 "Sixth Gear" 7 "Seventh Gear" 8 "Eighth Gear" 9 "Ninth Gear" 10 "Tenth Gear" 11 "Unused and Reserved" 12 "CVT Forward Gear" 13 "Neutral Gear" 14 "Reverse Gear" 15 "Park Gear" ;
VAL_TABLE_ TEGP_TrnsEngdStAuth_Inv 0 "FALSE" 1 "TRUE" ;
VAL_TABLE_ TEGP_TrnsEngdStAuth 0 "Transmission Not Engaged" 1 "Transmission Engaged in Forward" 2 "Transmission Engaged in Reverse" 3 "Operating State Not Reached" ;
VAL_TABLE_ TEGP_TransCmndGrAuth 0 "Not Supported" 1 "First Gear" 2 "Second Gear" 3 "Third Gear" 4 "Fourth Gear" 5 "Fifth Gear" 6 "Sixth Gear" 7 "Seventh Gear" 8 "Eighth Gear" 9 "Ninth Gear" 10 "Tenth Gear" 11 "Unused and Reserved" 12 "CVT Forward Gear" 13 "Neutral Gear" 14 "Reverse Gear" 15 "Park Gear" ;
VAL_TABLE_ TEGP_TrnsShftLvrPstnAuth 0 "Between Ranges" 1 "Park Range" 2 "Reverse Range" 3 "Neutral Range" 4 "Forward Range A" 5 "Forward Range B" 6 "Forward Range C" 7 "Forward Range D" 8 "Forward Range E" 9 "Forward Range F" 10 "Forward Range G" 11 "Forward Range H" 12 "Forward Range I" 13 "Forward Range J" 14 "Lever Position Unknown" ;
VAL_TABLE_ TEGP_TrnsEstGrAuth_Inv 0 "FALSE" 1 "TRUE" ;
VAL_TABLE_ TEGP_TrnsShftLvrPstnAuth_Inv 0 "FALSE" 1 "TRUE" ;
VAL_TABLE_ Sig7538 0 "FALSE" 1 "TRUE" ;
VAL_TABLE_ TCIP_AxlEstdTrqLRAuth_Inv 0 "FALSE" 1 "TRUE" ;
VAL_TABLE_ TCIP_AxlStsRrAuth 0 "Normal" 1 "Temporary Inhibit" 2 "Temporary Limited" 3 "Permanently Failed" ;
VAL_TABLE_ TCIP_AxlEstdTrqRRAuth_Inv 0 "FALSE" 1 "TRUE" ;
VAL_TABLE_ Sig7850 0 "FALSE" 1 "TRUE" ;
VAL_TABLE_ Sig7852 0 "FALSE" 1 "TRUE" ;
VAL_TABLE_ VICM_CAN2_ClscCANHrtBtActv 0 "FALSE" 1 "TRUE" ;
VAL_TABLE_ VICMI1P_AutoDrvShfSysStsPriAuth 0 "Unknown" 1 "Shift In Progress" 2 "Control Override" 3 "Error" 4 "Standby" ;
VAL_TABLE_ VICMI1P_ADShfSysHlthStsPriAuth 0 "Unknown" 1 "Normal" 2 "Degraded Functional" 3 "Failed in Range Functional" 4 "Failed Defaulted" ;
VAL_TABLE_ VICMI1P_AuxPwrModStsAuth 0 "NormConvNormTempLo" 1 "NormConvNormTempHi" 2 "Derated" 3 "HighTempNearDerated" 4 "Dsbld" 5 "HiTempDsbldDerated" 6 "Indeterminate" 7 "CommandedOff" 8 "OverTempConvDerated" ;
VAL_TABLE_ UpftrRmtVehStrtReqd 0 "FALSE" 1 "TRUE" ;
VAL_TABLE_ UpftrSnwPlwLoBmDsblReqd 0 "FALSE" 1 "TRUE" ;
VAL_TABLE_ VODVP_VehOdoDispValAuth_Inv 0 "FALSE" 1 "TRUE" ;
VAL_TABLE_ VSADP_RdcdPwrIndOnAuth 0 "FALSE" 1 "TRUE" ;
VAL_TABLE_ VSADP_FuelModeStsAuth 0 "Unknown" 1 "Gasoline Mode" 2 "Natural Gas Mode" 3 "Liquified Petroleum Gas Mode" 4 "Alternative Fuel Cut-off Active" ;
VAL_TABLE_ EngEmsRltMlfIndRq 0 "Continuous Indication" 1 "No Indication" 2 "Flashing 1 Hertz Indication" 3 "Flashing 2 Hertz Indication" 4 "Flashing 0.5 Hertz Indication" ;
VAL_TABLE_ VSADP_VehSpdAvgDrvnSrcAuth 0 "Transmission Output Speed" 1 "Wheel Speed" ;
VAL_TABLE_ VSADP_VehSpdAvgDrvnAuth_Inv 0 "FALSE" 1 "TRUE" ;
VAL_TABLE_ VSANDP_VehSpdAvgNDrvnAuth_Inv 0 "FALSE" 1 "TRUE" ;
VAL_TABLE_ Sig7896 0 "Unknown" 1 "Not Connected" 2 "Connected" ;
VAL_TABLE_ Sig7895 0 "Unknown" 1 "Not Connected" 2 "Connected" ;
VAL_TABLE_ XCGIP_SecAxlPrkBrkAppReqdAuth 0 "FALSE" 1 "TRUE" ;

BO_ 2147745829 Message0001_PDU: 1 Vector__XXX
 SG_ Sig0068 : 7|1@0+ (1,0) [0|1] "" CGM

BO_ 2147745830 ACP3_MCU_CAN2_ClscCANHrtBtActv_P: 1 Vector__XXX
 SG_ ACP3_MCU_CAN2_ClscCANHrtBtActv : 7|1@0+ (1,0) [0|1] "" CGM

BO_ 2147745793 Message0008_PDU: 1 Vector__XXX
 SG_ Sig0094 : 7|1@0+ (1,0) [0|1] "" CGM

BO_ 264 ADIMa_NM_PDU_On_CAN_2_Cluster: 8 Vector__XXX
 SG_ ISignal_ADIMa_CAN_2_Cluster : 23|48@0+ (1,0) [0|281474976710655] "" ACP2_MCU,ADIMb,AHL_AFL,AHS,ARS,BSM,VECM,VICM,BSM_MH,CGM,DCM,DMS,EBCM,ECM,ECP_MC,EOCM,EOCM_HC_Superset,EPSRAa,EPS,EPSb,FCM,FOPM,HUD_CAN,LIB1,NVM,E44,PCM,RDCM,TCCM,TCM,VDM,ECP_E,ECP_S,ECP_S2,ECP_X1

BO_ 2147745794 Message0013_PDU: 1 Vector__XXX
 SG_ Sig0098 : 7|1@0+ (1,0) [0|1] "" CGM

BO_ 2147745808 Message0016_PDU: 1 Vector__XXX
 SG_ Sig0111 : 7|1@0+ (1,0) [0|1] "" CGM

BO_ 370 AHL_AFL_NM_PDU_On_CAN_2_Cluster: 8 Vector__XXX
 SG_ ISignal_AHL_AFL_CAN_2_Cluster : 23|48@0+ (1,0) [0|281474976710655] "" ACP2_MCU,ADIMa,ADIMb,AHS,ARS,BSM,VECM,VICM,BSM_MH,CGM,DCM,DMS,EBCM,ECM,ECP_MC,EOCM,EOCM_HC_Superset,EPSRAa,EPS,EPSb,FCM,FOPM,HUD_CAN,LIB1,NVM,E44,PCM,RDCM,TCCM,TCM,VDM,ECP_E,ECP_S,ECP_S2,ECP_X1

BO_ 2147745809 Message0018_PDU: 1 Vector__XXX
 SG_ Sig0112 : 7|1@0+ (1,0) [0|1] "" CGM

BO_ 927 APACtlAng_PCSM_PDU: 8 Vector__XXX
 SG_ AE44CtlAng_PCSM : 7|64@0+ (1,0) [0|1.84467e+019] "" EPS,EPSb

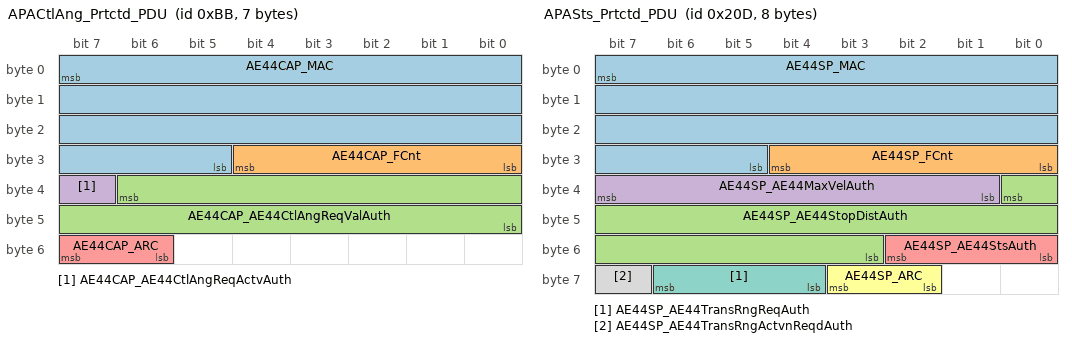
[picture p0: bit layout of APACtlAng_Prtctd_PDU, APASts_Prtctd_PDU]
BO_ 187 APACtlAng_Prtctd_PDU: 7 Vector__XXX
 SG_ AE44CAP_MAC : 7|27@0+ (1,0) [0|1.34218e+008] "" EPS,EPSb
 SG_ AE44CAP_FCnt : 28|5@0+ (1,0) [0|31] "" EPS,EPSb
 SG_ AE44CAP_AE44CtlAngReqValAuth : 38|15@0- (0.0625,0) [-1024|1023.94] "deg" EPS,EPSb
 SG_ AE44CAP_AE44CtlAngReqActvAuth : 39|1@0+ (1,0) [0|1] "" EPS,EPSb
 SG_ AE44CAP_ARC : 55|2@0+ (1,0) [0|3] "" EPS,EPSb

BO_ 926 APAObj_BrstGrp_PCSM_PDU: 8 Vector__XXX
 SG_ AE44Obj_BrstGrp1_PCSM : 7|64@0+ (1,0) [0|1.84467e+019] "" ACP2_MCU,EOCM,EOCM_HC_Superset,FCM

BO_ 529 APAObj_BrstGrp_Prtctd_First_Fram: 64 Vector__XXX
 SG_ AE44OBG1P_MAC : 7|32@0+ (1,0) [0|4.29497e+009] "" ACP2_MCU,EOCM,EOCM_HC_Superset,FCM
 SG_ AE44OBG1P_FCnt : 39|5@0+ (1,0) [0|31] "" ACP2_MCU,EOCM,EOCM_HC_Superset,FCM
 SG_ AE44OBG1P_PstnP2_X7 : 45|11@0- (1,0) [-1024|1023] "cm" ACP2_MCU,EOCM,EOCM_HC_Superset,FCM
 SG_ AE44OBG1P_BrstID : 47|2@0+ (1,0) [0|3] "" ACP2_MCU,EOCM,EOCM_HC_Superset,FCM
 SG_ AE44OBG1P_PstnP1_X7 : 50|11@0- (1,0) [-1024|1023] "cm" ACP2_MCU,EOCM,EOCM_HC_Superset,FCM
 SG_ AE44OBG1P_PstnP2_X5 : 71|11@0- (1,0) [-1024|1023] "cm" ACP2_MCU,EOCM,EOCM_HC_Superset,FCM
 SG_ AE44OBG1P_PstnP1_Y7 : 76|11@0- (1,0) [-1024|1023] "cm" ACP2_MCU,EOCM,EOCM_HC_Superset,FCM
 SG_ AE44OBG1P_PstnP1_X6 : 81|11@0- (1,0) [-1024|1023] "cm" ACP2_MCU,EOCM,EOCM_HC_Superset,FCM
 SG_ AE44OBG1P_PstnP2_Y3 : 102|11@0- (1,0) [-1024|1023] "cm" ACP2_MCU,EOCM,EOCM_HC_Superset,FCM
 SG_ AE44OBG1P_PstnP1_X1 : 107|11@0- (1,0) [-1024|1023] "cm" ACP2_MCU,EOCM,EOCM_HC_Superset,FCM
 SG_ AE44OBG1P_PstnP1_Y2 : 112|11@0- (1,0) [-1024|1023] "cm" ACP2_MCU,EOCM,EOCM_HC_Superset,FCM
 SG_ AE44OBG1P_PstnP2_Y7 : 133|11@0- (1,0) [-1024|1023] "cm" ACP2_MCU,EOCM,EOCM_HC_Superset,FCM
 SG_ AE44OBG1P_PstnP1_Y1 : 138|11@0- (1,0) [-1024|1023] "cm" ACP2_MCU,EOCM,EOCM_HC_Superset,FCM
 SG_ AE44OBG1P_PstnP2_X8 : 159|11@0- (1,0) [-1024|1023] "cm" ACP2_MCU,EOCM,EOCM_HC_Superset,FCM
 SG_ AE44OBG1P_PstnP1_Y6 : 164|11@0- (1,0) [-1024|1023] "cm" ACP2_MCU,EOCM,EOCM_HC_Superset,FCM
 SG_ AE44OBG1P_PstnP1_X3 : 169|11@0- (1,0) [-1024|1023] "cm" ACP2_MCU,EOCM,EOCM_HC_Superset,FCM
 SG_ AE44OBG1P_PstnP2_Y4 : 190|11@0- (1,0) [-1024|1023] "cm" ACP2_MCU,EOCM,EOCM_HC_Superset,FCM
 SG_ AE44OBG1P_PstnP1_Y5 : 195|11@0- (1,0) [-1024|1023] "cm" ACP2_MCU,EOCM,EOCM_HC_Superset,FCM
 SG_ AE44OBG1P_PstnP1_Y3 : 200|11@0- (1,0) [-1024|1023] "cm" ACP2_MCU,EOCM,EOCM_HC_Superset,FCM
 SG_ AE44OBG1P_PstnP1_X8 : 221|11@0- (1,0) [-1024|1023] "cm" ACP2_MCU,EOCM,EOCM_HC_Superset,FCM
 SG_ AE44OBG1P_PstnP2_Y6 : 226|11@0- (1,0) [-1024|1023] "cm" ACP2_MCU,EOCM,EOCM_HC_Superset,FCM
 SG_ AE44OBG1P_PstnP2_X4 : 247|11@0- (1,0) [-1024|1023] "cm" ACP2_MCU,EOCM,EOCM_HC_Superset,FCM
 SG_ AE44OBG1P_PstnP2_Y2 : 252|11@0- (1,0) [-1024|1023] "cm" ACP2_MCU,EOCM,EOCM_HC_Superset,FCM
 SG_ AE44OBG1P_PstnP2_Y5 : 257|11@0- (1,0) [-1024|1023] "cm" ACP2_MCU,EOCM,EOCM_HC_Superset,FCM
 SG_ AE44OBG1P_PstnP2_Y8 : 278|11@0- (1,0) [-1024|1023] "cm" ACP2_MCU,EOCM,EOCM_HC_Superset,FCM
 SG_ AE44OBG1P_PstnP1_Y8 : 283|11@0- (1,0) [-1024|1023] "cm" ACP2_MCU,EOCM,EOCM_HC_Superset,FCM
 SG_ AE44OBG1P_PstnP2_X6 : 288|11@0- (1,0) [-1024|1023] "cm" ACP2_MCU,EOCM,EOCM_HC_Superset,FCM
 SG_ AE44OBG1P_PstnP2_X2 : 309|11@0- (1,0) [-1024|1023] "cm" ACP2_MCU,EOCM,EOCM_HC_Superset,FCM
 SG_ AE44OBG1P_PstnP1_X5 : 314|11@0- (1,0) [-1024|1023] "cm" ACP2_MCU,EOCM,EOCM_HC_Superset,FCM
 SG_ AE44OBG1P_PstnP1_X4 : 335|11@0- (1,0) [-1024|1023] "cm" ACP2_MCU,EOCM,EOCM_HC_Superset,FCM
 SG_ AE44OBG1P_PstnP1_Y4 : 340|11@0- (1,0) [-1024|1023] "cm" ACP2_MCU,EOCM,EOCM_HC_Superset,FCM
 SG_ AE44OBG1P_PstnP2_Y1 : 345|11@0- (1,0) [-1024|1023] "cm" ACP2_MCU,EOCM,EOCM_HC_Superset,FCM
 SG_ AE44OBG1P_PstnP1_X2 : 366|11@0- (1,0) [-1024|1023] "cm" ACP2_MCU,EOCM,EOCM_HC_Superset,FCM
 SG_ AE44OBG1P_PstnP2_X3 : 371|11@0- (1,0) [-1024|1023] "cm" ACP2_MCU,EOCM,EOCM_HC_Superset,FCM
 SG_ AE44OBG1P_PstnP2_X1 : 376|11@0- (1,0) [-1024|1023] "cm" ACP2_MCU,EOCM,EOCM_HC_Superset,FCM
 SG_ AE44OBG1P_Filler : 395|32@0+ (1,0) [0|4.29497e+009] "" ACP2_MCU,EOCM,EOCM_HC_Superset,FCM
 SG_ AE44OBG1P_ARC : 397|2@0+ (1,0) [0|3] "" ACP2_MCU,EOCM,EOCM_HC_Superset,FCM
 SG_ AE44OBG1P_FillerExtnd : 427|32@0+ (1,0) [0|4.29497e+009] "0" ACP2_MCU,EOCM,EOCM_HC_Superset,FCM
 SG_ AE44OBG1P_FillerExtnd1 : 459|32@0+ (1,0) [0|4.29497e+009] "" ACP2_MCU,EOCM,EOCM_HC_Superset,FCM
 SG_ AE44OBG1P_FillerExtnd2 : 491|20@0+ (1,0) [0|1.04858e+006] "" ACP2_MCU,EOCM,EOCM_HC_Superset,FCM

BO_ 530 APAObj_BrstGrp_Prtctd_Last_Frame: 24 Vector__XXX
 SG_ AE44OBG2P_Tol6 : 0|7@0+ (1,0) [0|127] "cm" ACP2_MCU,EOCM,EOCM_HC_Superset,FCM
 SG_ AE44OBG2P_ID4 : 5|5@0+ (1,0) [0|31] "" ACP2_MCU,EOCM,EOCM_HC_Superset,FCM
 SG_ AE44OBG2P_BrstID : 7|2@0+ (1,0) [0|3] "" ACP2_MCU,EOCM,EOCM_HC_Superset,FCM
 SG_ AE44OBG2P_Tol5 : 9|7@0+ (1,0) [0|127] "cm" ACP2_MCU,EOCM,EOCM_HC_Superset,FCM
 SG_ AE44OBG2P_ID8 : 18|5@0+ (1,0) [0|31] "" ACP2_MCU,EOCM,EOCM_HC_Superset,FCM
 SG_ AE44OBG2P_Cnfd8 : 24|2@0+ (1,0) [0|3] "" ACP2_MCU,EOCM,EOCM_HC_Superset,FCM
 SG_ AE44OBG2P_Typ6 : 27|3@0+ (1,0) [0|6] "" ACP2_MCU,EOCM,EOCM_HC_Superset,FCM
 SG_ AE44OBG2P_Cnfd4 : 29|2@0+ (1,0) [0|3] "" ACP2_MCU,EOCM,EOCM_HC_Superset,FCM
 SG_ AE44OBG2P_Hght7 : 33|3@0+ (1,0) [0|3] "" ACP2_MCU,EOCM,EOCM_HC_Superset,FCM
 SG_ AE44OBG2P_ID2 : 38|5@0+ (1,0) [0|31] "" ACP2_MCU,EOCM,EOCM_HC_Superset,FCM
 SG_ AE44OBG2P_Hght8 : 41|3@0+ (1,0) [0|3] "" ACP2_MCU,EOCM,EOCM_HC_Superset,FCM
 SG_ AE44OBG2P_ID1 : 46|5@0+ (1,0) [0|31] "" ACP2_MCU,EOCM,EOCM_HC_Superset,FCM
 SG_ AE44OBG2P_ID3 : 49|5@0+ (1,0) [0|31] "" ACP2_MCU,EOCM,EOCM_HC_Superset,FCM
 SG_ AE44OBG2P_Typ4 : 52|3@0+ (1,0) [0|6] "" ACP2_MCU,EOCM,EOCM_HC_Superset,FCM
 SG_ AE44OBG2P_Cnfd1 : 54|2@0+ (1,0) [0|3] "" ACP2_MCU,EOCM,EOCM_HC_Superset,FCM
 SG_ AE44OBG2P_Tol3 : 58|7@0+ (1,0) [0|127] "cm" ACP2_MCU,EOCM,EOCM_HC_Superset,FCM
 SG_ AE44OBG2P_Cnfd6 : 60|2@0+ (1,0) [0|3] "" ACP2_MCU,EOCM,EOCM_HC_Superset,FCM
 SG_ AE44OBG2P_Tol7 : 64|7@0+ (1,0) [0|127] "cm" ACP2_MCU,EOCM,EOCM_HC_Superset,FCM
 SG_ AE44OBG2P_Typ2 : 67|3@0+ (1,0) [0|6] "" ACP2_MCU,EOCM,EOCM_HC_Superset,FCM
 SG_ AE44OBG2P_Cnfd3 : 73|2@0+ (1,0) [0|3] "" ACP2_MCU,EOCM,EOCM_HC_Superset,FCM
 SG_ AE44OBG2P_ID5 : 84|5@0+ (1,0) [0|31] "" ACP2_MCU,EOCM,EOCM_HC_Superset,FCM
 SG_ AE44OBG2P_Hght5 : 87|3@0+ (1,0) [0|3] "" ACP2_MCU,EOCM,EOCM_HC_Superset,FCM
 SG_ AE44OBG2P_Hght4 : 90|3@0+ (1,0) [0|3] "" ACP2_MCU,EOCM,EOCM_HC_Superset,FCM
 SG_ AE44OBG2P_Cnfd5 : 92|2@0+ (1,0) [0|3] "" ACP2_MCU,EOCM,EOCM_HC_Superset,FCM
 SG_ AE44OBG2P_Hght2 : 95|3@0+ (1,0) [0|3] "" ACP2_MCU,EOCM,EOCM_HC_Superset,FCM
 SG_ AE44OBG2P_Tol4 : 100|7@0+ (1,0) [0|127] "cm" ACP2_MCU,EOCM,EOCM_HC_Superset,FCM
 SG_ AE44OBG2P_Typ3 : 103|3@0+ (1,0) [0|6] "" ACP2_MCU,EOCM,EOCM_HC_Superset,FCM
 SG_ AE44OBG2P_Tol8 : 107|7@0+ (1,0) [0|127] "cm" ACP2_MCU,EOCM,EOCM_HC_Superset,FCM
 SG_ AE44OBG2P_Cnfd7 : 109|2@0+ (1,0) [0|3] "" ACP2_MCU,EOCM,EOCM_HC_Superset,FCM
 SG_ AE44OBG2P_Tol2 : 113|7@0+ (1,0) [0|127] "cm" ACP2_MCU,EOCM,EOCM_HC_Superset,FCM
 SG_ AE44OBG2P_Typ1 : 116|3@0+ (1,0) [0|6] "" ACP2_MCU,EOCM,EOCM_HC_Superset,FCM
 SG_ AE44OBG2P_Typ5 : 122|3@0+ (1,0) [0|6] "" ACP2_MCU,EOCM,EOCM_HC_Superset,FCM
 SG_ AE44OBG2P_Hght3 : 130|3@0+ (1,0) [0|3] "" ACP2_MCU,EOCM,EOCM_HC_Superset,FCM
 SG_ AE44OBG2P_ID6 : 135|5@0+ (1,0) [0|31] "" ACP2_MCU,EOCM,EOCM_HC_Superset,FCM
 SG_ AE44OBG2P_Tol1 : 141|7@0+ (1,0) [0|127] "cm" ACP2_MCU,EOCM,EOCM_HC_Superset,FCM
 SG_ AE44OBG2P_Cnfd2 : 143|2@0+ (1,0) [0|3] "" ACP2_MCU,EOCM,EOCM_HC_Superset,FCM
 SG_ AE44OBG2P_Typ7 : 144|3@0+ (1,0) [0|6] "" ACP2_MCU,EOCM,EOCM_HC_Superset,FCM
 SG_ AE44OBG2P_Hght6 : 147|3@0+ (1,0) [0|3] "" ACP2_MCU,EOCM,EOCM_HC_Superset,FCM
 SG_ AE44OBG2P_Typ8 : 150|3@0+ (1,0) [0|6] "" ACP2_MCU,EOCM,EOCM_HC_Superset,FCM
 SG_ AE44OBG2P_ID7 : 154|5@0+ (1,0) [0|31] "" ACP2_MCU,EOCM,EOCM_HC_Superset,FCM
 SG_ AE44OBG2P_Hght1 : 157|3@0+ (1,0) [0|3] "" ACP2_MCU,EOCM,EOCM_HC_Superset,FCM
 SG_ AE44OBG2P_Filler : 165|30@0+ (1,0) [0|1.07374e+009] "" ACP2_MCU,EOCM,EOCM_HC_Superset,FCM

BO_ 925 APASts_PCSM_PDU: 8 Vector__XXX
 SG_ AE44Sts_PCSM : 7|64@0+ (1,0) [0|1.84467e+019] "" ACP2_MCU,VICM,EBCM,ECM,EOCM,EOCM_HC_Superset,PCM,ECP_E

BO_ 525 APASts_Prtctd_PDU: 8 Vector__XXX
 SG_ AE44SP_MAC : 7|27@0+ (1,0) [0|1.34218e+008] "" ACP2_MCU,VICM,CGM,EBCM,ECM,EOCM,EOCM_HC_Superset,PCM,ECP_E
 SG_ AE44SP_FCnt : 28|5@0+ (1,0) [0|31] "" ACP2_MCU,VICM,CGM,EBCM,ECM,EOCM,EOCM_HC_Superset,PCM,ECP_E
 SG_ AE44SP_AE44StopDistAuth : 32|14@0- (1,0) [-8192|8191] "cm" ACP2_MCU,VICM,CGM,EBCM,ECM,EOCM,EOCM_HC_Superset,PCM,ECP_E
 SG_ AE44SP_AE44MaxVelAuth : 39|7@0+ (0.1,0) [0|12.7] "km/h" ACP2_MCU,VICM,CGM,EBCM,ECM,EOCM,EOCM_HC_Superset,PCM,ECP_E
 SG_ AE44SP_AE44StsAuth : 50|3@0+ (1,0) [0|7] "" ACP2_MCU,VICM,CGM,EBCM,ECM,EOCM,EOCM_HC_Superset,FCM,PCM,ECP_E
 SG_ AE44SP_ARC : 59|2@0+ (1,0) [0|3] "" ACP2_MCU,VICM,CGM,EBCM,ECM,EOCM,EOCM_HC_Superset,PCM,ECP_E
 SG_ AE44SP_AE44TransRngReqAuth : 62|3@0+ (1,0) [0|4] "" ACP2_MCU,VICM,CGM,EBCM,ECM,EOCM,EOCM_HC_Superset,PCM,ECP_E
 SG_ AE44SP_AE44TransRngActvnReqdAuth : 63|1@0+ (1,0) [0|1] "" ACP2_MCU,VICM,CGM,EBCM,ECM,EOCM,EOCM_HC_Superset,PCM,ECP_E

BO_ 2147745810 Message0020_PDU: 1 Vector__XXX
 SG_ Sig0224 : 7|1@0+ (1,0) [0|1] "" CGM

BO_ 2147745811 Message0022_PDU: 1 Vector__XXX
 SG_ Sig0304 : 7|1@0+ (1,0) [0|1] "" CGM

BO_ 1393 ActvSftyOprtrCrtclNtfns_PCSM_PDU: 8 Vector__XXX
 SG_ ActvSftyOprtrCrtclNtfns_PCSM : 7|64@0+ (1,0) [0|1.84467e+019] "" Vector__XXX

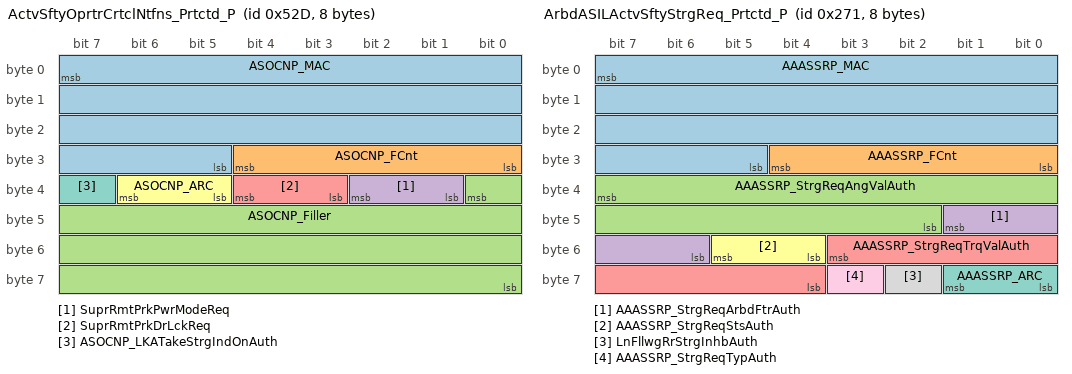
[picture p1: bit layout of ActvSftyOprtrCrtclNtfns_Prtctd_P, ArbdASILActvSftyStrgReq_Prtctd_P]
BO_ 1325 ActvSftyOprtrCrtclNtfns_Prtctd_P: 8 Vector__XXX
 SG_ ASOCNP_MAC : 7|27@0+ (1,0) [0|1.34218e+008] "" Vector__XXX
 SG_ ASOCNP_FCnt : 28|5@0+ (1,0) [0|31] "" Vector__XXX
 SG_ ASOCNP_Filler : 32|25@0+ (1,0) [0|3.35544e+007] "" Vector__XXX
 SG_ SuprRmtPrkPwrModeReq : 34|2@0+ (1,0) [0|2] "" Vector__XXX
 SG_ SuprRmtPrkDrLckReq : 36|2@0+ (1,0) [0|2] "" Vector__XXX
 SG_ ASOCNP_ARC : 38|2@0+ (1,0) [0|3] "" Vector__XXX
 SG_ ASOCNP_LKATakeStrgIndOnAuth : 39|1@0+ (1,0) [0|1] "" Vector__XXX

BO_ 229 Message0024_PDU: 48 Vector__XXX
 SG_ Sig0115 : 5|11@0+ (1,0) [0|2047] "ms" AHL_AFL
 SG_ Sig0114 : 7|2@0+ (1,0) [0|3] "" AHL_AFL
 SG_ Sig0117 : 9|11@0+ (0.125,-128) [-128|127.875] "deg/s" AHL_AFL
 SG_ Sig0116 : 10|1@0+ (1,0) [0|1] "" AHL_AFL
 SG_ Sig0118 : 30|11@0+ (0.125,-128) [-128|127.875] "deg/s" AHL_AFL
 SG_ Sig0119 : 35|11@0+ (0.125,-128) [-128|127.875] "deg/s" AHL_AFL
 SG_ Sig0120 : 40|11@0+ (0.125,-128) [-128|127.875] "deg/s" AHL_AFL
 SG_ Sig0121 : 61|11@0+ (0.05,-51.2) [-51.2|51.15] "deg" AHL_AFL
 SG_ Sig0122 : 66|11@0+ (0.05,-51.2) [-51.2|51.15] "deg" AHL_AFL
 SG_ Sig0123 : 87|11@0+ (0.05,-51.2) [-51.2|51.15] "deg" AHL_AFL
 SG_ Sig0124 : 92|11@0+ (0.05,-51.2) [-51.2|51.15] "deg" AHL_AFL
 SG_ Sig0125 : 97|2@0+ (1,0) [0|3] "" AHL_AFL
 SG_ Sig0129 : 105|3@0+ (1,0) [0|4] "" AHL_AFL
 SG_ Sig0128 : 107|2@0+ (1,0) [0|3] "" AHL_AFL
 SG_ Sig0127 : 109|2@0+ (1,0) [0|3] "" AHL_AFL
 SG_ Sig0126 : 111|2@0+ (1,0) [0|3] "" AHL_AFL
 SG_ Sig0132 : 112|3@0+ (1,0) [0|4] "" AHL_AFL
 SG_ Sig0131 : 115|3@0+ (1,0) [0|4] "" AHL_AFL
 SG_ Sig0130 : 118|3@0+ (1,0) [0|4] "" AHL_AFL
 SG_ Sig0133 : 125|6@0+ (1,0) [0|63] "" AHL_AFL
 SG_ Sig0135 : 129|6@0+ (1,0) [0|63] "" AHL_AFL
 SG_ Sig0134 : 135|6@0+ (1,0) [0|63] "" AHL_AFL
 SG_ Sig0136 : 139|6@0+ (1,0) [0|63] "" AHL_AFL
 SG_ Sig0139 : 145|2@0+ (1,0) [0|3] "" AHL_AFL
 SG_ Sig0138 : 147|2@0+ (1,0) [0|3] "" AHL_AFL
 SG_ Sig0137 : 149|2@0+ (1,0) [0|3] "" AHL_AFL
 SG_ Sig0141 : 157|7@0+ (1,0) [0|127] "%" AHL_AFL
 SG_ Sig0140 : 159|2@0+ (1,0) [0|3] "" AHL_AFL
 SG_ Sig0142 : 166|7@0+ (1,0) [0|127] "%" AHL_AFL
 SG_ Sig0144 : 168|7@0+ (1,0) [0|127] "%" AHL_AFL
 SG_ Sig0143 : 175|7@0+ (1,0) [0|127] "%" AHL_AFL
 SG_ Sig0145 : 177|2@0+ (1,0) [0|3] "" AHL_AFL
 SG_ Sig0149 : 185|16@0+ (0.02,0) [0|1310.7] "m" AHL_AFL
 SG_ Sig0148 : 187|2@0+ (1,0) [0|3] "" AHL_AFL
 SG_ Sig0147 : 189|2@0+ (1,0) [0|3] "" AHL_AFL
 SG_ Sig0146 : 191|2@0+ (1,0) [0|3] "" AHL_AFL
 SG_ Sig0151 : 200|16@0+ (0.02,0) [0|1310.7] "m" AHL_AFL
 SG_ Sig0150 : 201|1@0+ (1,0) [0|1] "" AHL_AFL
 SG_ Sig0152 : 216|1@0+ (1,0) [0|1] "" AHL_AFL
 SG_ Sig0153 : 231|16@0+ (0.02,0) [0|1310.7] "m" AHL_AFL
 SG_ Sig0155 : 246|16@0+ (0.02,0) [0|1310.7] "m" AHL_AFL
 SG_ Sig0154 : 247|1@0+ (1,0) [0|1] "" AHL_AFL
 SG_ Sig0158 : 257|4@0+ (1,0) [0|12] "" AHL_AFL
 SG_ Sig0157 : 261|4@0+ (1,0) [0|12] "" AHL_AFL
 SG_ Sig0156 : 262|1@0+ (1,0) [0|1] "" AHL_AFL
 SG_ Sig0160 : 265|4@0+ (1,0) [0|12] "" AHL_AFL
 SG_ Sig0159 : 269|4@0+ (1,0) [0|12] "" AHL_AFL
 SG_ Sig0161 : 277|6@0+ (0.25,-3) [-3|12.75] "deg" AHL_AFL
 SG_ Sig0163 : 281|6@0+ (0.25,-3) [-3|12.75] "deg" AHL_AFL
 SG_ Sig0162 : 287|6@0+ (0.25,-3) [-3|12.75] "deg" AHL_AFL
 SG_ Sig0164 : 291|6@0+ (0.25,-3) [-3|12.75] "deg" AHL_AFL
 SG_ Sig0165 : 301|11@0+ (0.1,0) [0|204.7] "deg" AHL_AFL
 SG_ Sig0166 : 306|11@0+ (0.1,0) [0|204.7] "deg" AHL_AFL
 SG_ Sig0167 : 327|11@0+ (0.1,0) [0|204.7] "deg" AHL_AFL
 SG_ Sig0168 : 332|11@0+ (0.1,0) [0|204.7] "deg" AHL_AFL

BO_ 195 Message0025_PDU: 48 Vector__XXX
 SG_ Sig0170 : 5|11@0+ (1,0) [0|2047] "ms" AHL_AFL
 SG_ Sig0169 : 7|2@0+ (1,0) [0|3] "" AHL_AFL
 SG_ Sig0172 : 9|11@0+ (0.125,-128) [-128|127.875] "deg/s" AHL_AFL
 SG_ Sig0171 : 10|1@0+ (1,0) [0|1] "" AHL_AFL
 SG_ Sig0173 : 30|11@0+ (0.125,-128) [-128|127.875] "deg/s" AHL_AFL
 SG_ Sig0174 : 35|11@0+ (0.125,-128) [-128|127.875] "deg/s" AHL_AFL
 SG_ Sig0175 : 40|11@0+ (0.125,-128) [-128|127.875] "deg/s" AHL_AFL
 SG_ Sig0176 : 61|11@0+ (0.05,-51.2) [-51.2|51.15] "deg" AHL_AFL
 SG_ Sig0177 : 66|11@0+ (0.05,-51.2) [-51.2|51.15] "deg" AHL_AFL
 SG_ Sig0178 : 87|11@0+ (0.05,-51.2) [-51.2|51.15] "deg" AHL_AFL
 SG_ Sig0179 : 92|11@0+ (0.05,-51.2) [-51.2|51.15] "deg" AHL_AFL
 SG_ Sig0180 : 97|2@0+ (1,0) [0|3] "" AHL_AFL
 SG_ Sig0184 : 105|3@0+ (1,0) [0|4] "" AHL_AFL
 SG_ Sig0183 : 107|2@0+ (1,0) [0|3] "" AHL_AFL
 SG_ Sig0182 : 109|2@0+ (1,0) [0|3] "" AHL_AFL
 SG_ Sig0181 : 111|2@0+ (1,0) [0|3] "" AHL_AFL
 SG_ Sig0187 : 112|3@0+ (1,0) [0|4] "" AHL_AFL
 SG_ Sig0186 : 115|3@0+ (1,0) [0|4] "" AHL_AFL
 SG_ Sig0185 : 118|3@0+ (1,0) [0|4] "" AHL_AFL
 SG_ Sig0188 : 125|6@0+ (1,0) [0|63] "" AHL_AFL
 SG_ Sig0190 : 129|6@0+ (1,0) [0|63] "" AHL_AFL
 SG_ Sig0189 : 135|6@0+ (1,0) [0|63] "" AHL_AFL
 SG_ Sig0191 : 139|6@0+ (1,0) [0|63] "" AHL_AFL
 SG_ Sig0194 : 145|2@0+ (1,0) [0|3] "" AHL_AFL
 SG_ Sig0193 : 147|2@0+ (1,0) [0|3] "" AHL_AFL
 SG_ Sig0192 : 149|2@0+ (1,0) [0|3] "" AHL_AFL
 SG_ Sig0196 : 157|7@0+ (1,0) [0|127] "%" AHL_AFL
 SG_ Sig0195 : 159|2@0+ (1,0) [0|3] "" AHL_AFL
 SG_ Sig0197 : 166|7@0+ (1,0) [0|127] "%" AHL_AFL
 SG_ Sig0199 : 168|7@0+ (1,0) [0|127] "%" AHL_AFL
 SG_ Sig0198 : 175|7@0+ (1,0) [0|127] "%" AHL_AFL
 SG_ Sig0200 : 177|2@0+ (1,0) [0|3] "" AHL_AFL
 SG_ Sig0204 : 185|16@0+ (0.02,0) [0|1310.7] "m" AHL_AFL
 SG_ Sig0203 : 187|2@0+ (1,0) [0|3] "" AHL_AFL
 SG_ Sig0202 : 189|2@0+ (1,0) [0|3] "" AHL_AFL
 SG_ Sig0201 : 191|2@0+ (1,0) [0|3] "" AHL_AFL
 SG_ Sig0206 : 200|16@0+ (0.02,0) [0|1310.7] "m" AHL_AFL
 SG_ Sig0205 : 201|1@0+ (1,0) [0|1] "" AHL_AFL
 SG_ Sig0207 : 216|1@0+ (1,0) [0|1] "" AHL_AFL
 SG_ Sig0208 : 231|16@0+ (0.02,0) [0|1310.7] "m" AHL_AFL
 SG_ Sig0210 : 246|16@0+ (0.02,0) [0|1310.7] "m" AHL_AFL
 SG_ Sig0209 : 247|1@0+ (1,0) [0|1] "" AHL_AFL
 SG_ Sig0213 : 257|4@0+ (1,0) [0|12] "" AHL_AFL
 SG_ Sig0212 : 261|4@0+ (1,0) [0|12] "" AHL_AFL
 SG_ Sig0211 : 262|1@0+ (1,0) [0|1] "" AHL_AFL
 SG_ Sig0215 : 265|4@0+ (1,0) [0|12] "" AHL_AFL
 SG_ Sig0214 : 269|4@0+ (1,0) [0|12] "" AHL_AFL
 SG_ Sig0216 : 277|6@0+ (0.25,-3) [-3|12.75] "deg" AHL_AFL
 SG_ Sig0218 : 281|6@0+ (0.25,-3) [-3|12.75] "deg" AHL_AFL
 SG_ Sig0217 : 287|6@0+ (0.25,-3) [-3|12.75] "deg" AHL_AFL
 SG_ Sig0219 : 291|6@0+ (0.25,-3) [-3|12.75] "deg" AHL_AFL
 SG_ Sig0220 : 301|11@0+ (0.1,0) [0|204.7] "deg" AHL_AFL
 SG_ Sig0221 : 306|11@0+ (0.1,0) [0|204.7] "deg" AHL_AFL
 SG_ Sig0222 : 327|11@0+ (0.1,0) [0|204.7] "deg" AHL_AFL
 SG_ Sig0223 : 332|11@0+ (0.1,0) [0|204.7] "deg" AHL_AFL

BO_ 924 ArbdASILActvSftyStrgReq_PCSM_PDU: 8 Vector__XXX
 SG_ ArbdASILActvSftyStrgReq_PCSM : 7|64@0+ (1,0) [0|1.84467e+019] "" ARS,EPS,EPSb

BO_ 625 ArbdASILActvSftyStrgReq_Prtctd_P: 8 Vector__XXX
 SG_ AAASSRP_MAC : 7|27@0+ (1,0) [0|1.34218e+008] "" ARS,CGM,EPS,EPSb
 SG_ AAASSRP_FCnt : 28|5@0+ (1,0) [0|31] "" ARS,CGM,EPS,EPSb
 SG_ AAASSRP_StrgReqAngValAuth : 39|14@0- (0.1,0) [-819.2|819.1] "degrees" ARS,CGM,EPS,EPSb
 SG_ AAASSRP_StrgReqArbdFtrAuth : 41|4@0+ (1,0) [0|8] "" ARS,CGM,EPS,EPSb
 SG_ AAASSRP_StrgReqTrqValAuth : 51|8@0- (0.1,0) [-12.8|12.7] "Nm" ARS,CGM,EPS,EPSb
 SG_ AAASSRP_StrgReqStsAuth : 53|2@0+ (1,0) [0|2] "" ARS,CGM,EPS,EPSb
 SG_ AAASSRP_ARC : 57|2@0+ (1,0) [0|3] "" ARS,CGM,EPS,EPSb
 SG_ LnFllwgRrStrgInhbAuth : 58|1@0+ (1,0) [0|1] "" ARS,CGM,EPS,EPSb
 SG_ AAASSRP_StrgReqTypAuth : 59|1@0+ (1,0) [0|1] "" ARS,CGM,EPS,EPSb

BO_ 521 Message0026_PDU: 64 Vector__XXX
 SG_ Sig0226 : 5|32@0+ (1,0) [0|4.29497e+009] "msec" Vector__XXX
 SG_ Sig0225 : 7|2@0+ (1,0) [0|3] "" Vector__XXX
 SG_ Sig0227 : 37|16@0- (9.77e-07,0) [-0.0320143|0.0320134] "1/m" Vector__XXX
 SG_ Sig0228 : 53|16@0- (3.73e-09,0) [-0.000122225|0.000122221] "1/m^2" Vector__XXX
 SG_ Sig0229 : 69|10@0- (0.000977,0) [-0.500224|0.499247] "rad" Vector__XXX
 SG_ Sig0230 : 75|13@0- (0.003906,0) [-15.999|15.9951] "m" Vector__XXX
 SG_ Sig0233 : 89|7@0+ (1,0) [0|127] "m" Vector__XXX
 SG_ Sig0232 : 92|3@0+ (1,0) [0|7] "" Vector__XXX
 SG_ Sig0231 : 94|2@0+ (1,0) [0|3] "" Vector__XXX
 SG_ Sig0234 : 98|7@0+ (1,0) [0|127] "m" Vector__XXX
 SG_ Sig0235 : 107|6@0+ (0.01,0) [0|0.63] "m" Vector__XXX
 SG_ Sig0236 : 117|16@0- (9.77e-07,0) [-0.0320143|0.0320134] "1/m" Vector__XXX
 SG_ Sig0237 : 133|16@0- (3.73e-09,0) [-0.000122225|0.000122221] "1/m^2" Vector__XXX
 SG_ Sig0238 : 149|10@0- (0.000977,0) [-0.500224|0.499247] "rad" Vector__XXX
 SG_ Sig0239 : 155|13@0- (0.003906,0) [-15.999|15.9951] "m" Vector__XXX
 SG_ Sig0242 : 169|7@0+ (1,0) [0|127] "m" Vector__XXX
 SG_ Sig0241 : 172|3@0+ (1,0) [0|7] "" Vector__XXX
 SG_ Sig0240 : 174|2@0+ (1,0) [0|3] "" Vector__XXX
 SG_ Sig0243 : 178|7@0+ (1,0) [0|127] "m" Vector__XXX
 SG_ Sig0244 : 187|6@0+ (0.01,0) [0|0.63] "m" Vector__XXX
 SG_ Sig0246 : 195|9@0- (0.125,0) [-32|31.875] "m/s^2" Vector__XXX
 SG_ Sig0245 : 197|2@0+ (1,0) [0|3] "" Vector__XXX
 SG_ Sig0247 : 202|10@0- (0.125,0) [-64|63.875] "m" Vector__XXX
 SG_ Sig0248 : 208|9@0- (0.125,0) [-32|31.875] "m/s" Vector__XXX
 SG_ Sig0249 : 231|9@0- (0.125,0) [-32|31.875] "m/s^2" Vector__XXX
 SG_ Sig0250 : 238|11@0+ (0.125,0) [0|255.875] "m" Vector__XXX
 SG_ Sig0251 : 243|11@0- (0.125,0) [-128|127.875] "m/s" Vector__XXX
 SG_ Sig0252 : 248|7@0+ (0.125,0) [0|15.875] "m" Vector__XXX
 SG_ Sig0253 : 257|2@0+ (1,0) [0|3] "" Vector__XXX
 SG_ Sig0255 : 264|2@0+ (1,0) [0|3] "" Vector__XXX
 SG_ Sig0254 : 271|7@0- (1,0) [-64|63] "pixel" Vector__XXX
 SG_ Sig0256 : 278|7@0- (1,0) [-64|63] "pixel" Vector__XXX
 SG_ Sig0257 : 287|32@0+ (1,0) [0|4.29497e+009] "msec" Vector__XXX
 SG_ Sig0259 : 312|12@0- (0.0001,0) [-0.2048|0.2047] "radians" Vector__XXX
 SG_ Sig0258 : 319|7@0+ (1,-40) [-40|87] "pixel" Vector__XXX
 SG_ Sig0260 : 332|7@0- (0.001,0) [-0.064|0.063] "radians" Vector__XXX
 SG_ Sig0261 : 341|7@0- (1,0) [-64|63] "pixel" Vector__XXX
 SG_ Sig0264 : 347|32@0+ (1,0) [0|4.29497e+009] "ms" Vector__XXX
 SG_ Sig0263 : 350|3@0+ (1,0) [0|7] "" Vector__XXX
 SG_ Sig0267 : 377|2@0+ (1,0) [0|3] "" Vector__XXX
 SG_ Sig0266 : 378|1@0+ (1,0) [0|1] "" Vector__XXX
 SG_ Sig0265 : 379|1@0+ (1,0) [0|1] "" Vector__XXX
 SG_ Sig0269 : 391|9@0- (0.125,0) [-32|31.875] "m/s^2" Vector__XXX
 SG_ Sig0270 : 398|10@0- (0.125,0) [-64|63.875] "m" Vector__XXX
 SG_ Sig0271 : 404|9@0- (0.125,0) [-32|31.875] "m/s" Vector__XXX
 SG_ Sig0272 : 411|9@0- (0.125,0) [-32|31.875] "m/s^2" Vector__XXX
 SG_ Sig0273 : 418|11@0+ (0.125,0) [0|255.875] "m" Vector__XXX
 SG_ Sig0274 : 439|11@0- (0.125,0) [-128|127.875] "m/s" Vector__XXX
 SG_ Sig0275 : 444|7@0+ (0.125,0) [0|15.875] "m" Vector__XXX
 SG_ Sig0262 : 453|11@0- (0.001,0) [-1.024|1.023] "radians" Vector__XXX
 SG_ Sig0268 : 458|7@0+ (0.125,0) [0|15.875] "m" Vector__XXX

BO_ 184 Message0027_PDU: 48 Vector__XXX
 SG_ Sig0277 : 5|32@0+ (1,0) [0|4.29497e+009] "msec" Vector__XXX
 SG_ Sig0276 : 7|2@0+ (1,0) [0|3] "" Vector__XXX
 SG_ Sig0278 : 37|16@0- (9.77e-07,0) [-0.0320143|0.0320134] "1/m" Vector__XXX
 SG_ Sig0279 : 53|16@0- (3.73e-09,0) [-0.000122225|0.000122221] "1/m^2" Vector__XXX
 SG_ Sig0280 : 69|10@0- (0.000977,0) [-0.500224|0.499247] "rad" Vector__XXX
 SG_ Sig0281 : 75|13@0- (0.003906,0) [-15.999|15.9951] "m" Vector__XXX
 SG_ Sig0284 : 89|7@0+ (1,0) [0|127] "m" Vector__XXX
 SG_ Sig0283 : 92|3@0+ (1,0) [0|7] "" Vector__XXX
 SG_ Sig0282 : 94|2@0+ (1,0) [0|3] "" Vector__XXX
 SG_ Sig0285 : 98|7@0+ (1,0) [0|127] "m" Vector__XXX
 SG_ Sig0286 : 107|6@0+ (0.01,0) [0|0.63] "m" Vector__XXX
 SG_ Sig0287 : 117|16@0- (9.77e-07,0) [-0.0320143|0.0320134] "1/m" Vector__XXX
 SG_ Sig0288 : 133|16@0- (3.73e-09,0) [-0.000122225|0.000122221] "1/m^2" Vector__XXX
 SG_ Sig0289 : 149|10@0- (0.000977,0) [-0.500224|0.499247] "rad" Vector__XXX
 SG_ Sig0290 : 155|13@0- (0.003906,0) [-15.999|15.9951] "m" Vector__XXX
 SG_ Sig0293 : 169|7@0+ (1,0) [0|127] "m" Vector__XXX
 SG_ Sig0292 : 172|3@0+ (1,0) [0|7] "" Vector__XXX
 SG_ Sig0291 : 174|2@0+ (1,0) [0|3] "" Vector__XXX
 SG_ Sig0294 : 178|7@0+ (1,0) [0|127] "m" Vector__XXX
 SG_ Sig0295 : 187|6@0+ (0.01,0) [0|0.63] "m" Vector__XXX
 SG_ Sig0297 : 195|9@0- (0.125,0) [-32|31.875] "m/s^2" Vector__XXX
 SG_ Sig0296 : 197|2@0+ (1,0) [0|3] "" Vector__XXX
 SG_ Sig0298 : 202|10@0- (0.125,0) [-64|63.875] "m" Vector__XXX
 SG_ Sig0299 : 208|9@0- (0.125,0) [-32|31.875] "m/s" Vector__XXX
 SG_ Sig0300 : 231|9@0- (0.125,0) [-32|31.875] "m/s^2" Vector__XXX
 SG_ Sig0301 : 238|11@0+ (0.125,0) [0|255.875] "m" Vector__XXX
 SG_ Sig0302 : 243|11@0- (0.125,0) [-128|127.875] "m/s" Vector__XXX
 SG_ Sig0303 : 248|7@0+ (0.125,0) [0|15.875] "m" Vector__XXX

BO_ 1392 Message0028_PDU: 8 Vector__XXX
 SG_ Sig0446 : 7|64@0+ (1,0) [0|1.84467e+019] "" FOPM

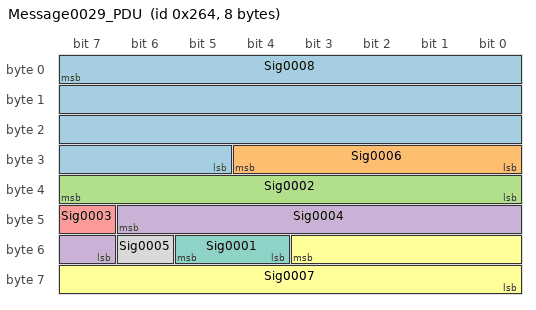
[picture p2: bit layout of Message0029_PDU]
BO_ 612 Message0029_PDU: 8 Vector__XXX
 SG_ Sig0008 : 7|27@0+ (1,0) [0|1.34218e+008] "" FOPM
 SG_ Sig0006 : 28|5@0+ (1,0) [0|31] "" FOPM
 SG_ Sig0002 : 39|8@0+ (0.1,0) [0|25.5] "Volts" FOPM
 SG_ Sig0004 : 46|8@0+ (0.1,0) [0|25.5] "Volts" FOPM
 SG_ Sig0003 : 47|1@0+ (1,0) [0|1] "" FOPM
 SG_ Sig0007 : 51|12@0+ (1,0) [0|4095] "" FOPM
 SG_ Sig0001 : 53|2@0+ (1,0) [0|3] "" FOPM
 SG_ Sig0005 : 54|1@0+ (1,0) [0|1] "" FOPM

BO_ 700 AutoBrkSysMnPriInfo1_PCSM_PDU: 8 Vector__XXX
 SG_ AutoBrkSysMnPriInfo1_PCSM : 7|64@0+ (1,0) [0|1.84467e+019] "" ADIMa,ADIMb,ECP_E

BA_DEF_ SG_  "SignalType" STRING ;
BA_DEF_ SG_  "SignalLongName" STRING ;
BA_DEF_ BO_  "GenMsgCycleTime" INT 0 10000;
BA_DEF_ BO_  "GenMsgSendType" ENUM "cyclicX","spontanX","cyclicIfActiveX","spontanWithDelay","cyclicAndSpontanX","cyclicAndSpontanWithDelay","spontanWithRepetition","cyclicIfActiveAndSpontanWD";
BA_DEF_ BO_  "VFrameFormat" ENUM  "StandardCAN","ExtendedCAN","reserved","reserved","reserved","reserved","reserved","reserved","reserved","reserved","reserved","reserved","reserved","reserved","StandardCAN_FD","ExtendedCAN_FD";
BA_DEF_DEF_  "SignalType" "";
BA_DEF_DEF_  "SignalLongName" "";
BA_DEF_DEF_  "GenMsgCycleTime" 0;
BA_DEF_DEF_  "GenMsgSendType" "cyclicX";
BA_DEF_DEF_  "VFrameFormat" "StandardCAN";
BA_ "GenMsgCycleTime" BO_ 2147745829 1000;
BA_ "GenMsgCycleTime" BO_ 2147745830 1000;
BA_ "GenMsgCycleTime" BO_ 2147745793 1000;
BA_ "GenMsgCycleTime" BO_ 2147745794 1000;
BA_ "GenMsgCycleTime" BO_ 2147745808 1000;
BA_ "GenMsgCycleTime" BO_ 2147745809 1000;
BA_ "VFrameFormat" BO_ 927 14;
BA_ "GenMsgCycleTime" BO_ 187 50;
BA_ "VFrameFormat" BO_ 187 14;
BA_ "VFrameFormat" BO_ 926 14;
BA_ "GenMsgCycleTime" BO_ 529 50;
BA_ "VFrameFormat" BO_ 529 14;
BA_ "GenMsgCycleTime" BO_ 530 50;
BA_ "VFrameFormat" BO_ 530 14;
BA_ "VFrameFormat" BO_ 925 14;
BA_ "GenMsgCycleTime" BO_ 525 50;
BA_ "VFrameFormat" BO_ 525 14;
BA_ "GenMsgCycleTime" BO_ 2147745810 1000;
BA_ "GenMsgCycleTime" BO_ 2147745811 1000;
BA_ "GenMsgCycleTime" BO_ 1393 3500;
BA_ "VFrameFormat" BO_ 1393 14;
BA_ "GenMsgCycleTime" BO_ 1325 1000;
BA_ "VFrameFormat" BO_ 1325 14;
BA_ "GenMsgCycleTime" BO_ 229 40;
BA_ "VFrameFormat" BO_ 229 14;
BA_ "GenMsgCycleTime" BO_ 195 40;
BA_ "VFrameFormat" BO_ 195 14;
BA_ "VFrameFormat" BO_ 924 14;
BA_ "GenMsgCycleTime" BO_ 625 100;
BA_ "VFrameFormat" BO_ 625 14;
BA_ "VFrameFormat" BO_ 521 14;
BA_ "VFrameFormat" BO_ 184 14;
BA_ "VFrameFormat" BO_ 1392 14;
BA_ "GenMsgCycleTime" BO_ 612 100;
BA_ "VFrameFormat" BO_ 612 14;
BA_ "VFrameFormat" BO_ 700 14;
BA_ "SignalType" SG_ 2147745829 Sig0068 "ENM";
BA_ "SignalLongName" SG_ 2147745829 Sig0068 "Signal0001";
BA_ "SignalType" SG_ 2147745830 ACP3_MCU_CAN2_ClscCANHrtBtActv "ENM";
BA_ "SignalLongName" SG_ 2147745830 ACP3_MCU_CAN2_ClscCANHrtBtActv "ACP3_MCU CAN 2 Classic CAN Heart Beat Active";
BA_ "SignalType" SG_ 2147745793 Sig0094 "ENM";
BA_ "SignalLongName" SG_ 2147745793 Sig0094 "Signal0023";
BA_ "SignalType" SG_ 2147745794 Sig0098 "ENM";
BA_ "SignalLongName" SG_ 2147745794 Sig0098 "Signal0027";
BA_ "SignalType" SG_ 2147745808 Sig0111 "ENM";
BA_ "SignalLongName" SG_ 2147745808 Sig0111 "Signal0030";
BA_ "SignalType" SG_ 2147745809 Sig0112 "ENM";
BA_ "SignalLongName" SG_ 2147745809 Sig0112 "Signal0031";
BA_ "SignalLongName" SG_ 927 AE44CtlAng_PCSM "Advanced Park Assist Control Angle Protected Counter Sync Message";
BA_ "SignalLongName" SG_ 187 AE44CAP_MAC "Advanced Park Assist Control Angle Protected : MAC";
BA_ "SignalLongName" SG_ 187 AE44CAP_FCnt "Advanced Park Assist Control Angle Protected : Freshness Counter";
BA_ "SignalLongName" SG_ 187 AE44CAP_AE44CtlAngReqValAuth "Advanced Park Assist Control Angle Protected : Advanced Park Assist Control Angle Request Value Authenticated";
BA_ "SignalType" SG_ 187 AE44CAP_AE44CtlAngReqActvAuth "ENM";
BA_ "SignalLongName" SG_ 187 AE44CAP_AE44CtlAngReqActvAuth "Advanced Park Assist Control Angle Protected : Advanced Park Assist Control Angle Request Active Authenticated";
BA_ "SignalLongName" SG_ 187 AE44CAP_ARC "Advanced Park Assist Control Angle Protected : Alive Rolling Count";
BA_ "SignalLongName" SG_ 926 AE44Obj_BrstGrp1_PCSM "Advanced Park Assist Objects Burst Group 1 Protected Counter Sync Message";
BA_ "SignalLongName" SG_ 529 AE44OBG1P_MAC "Advanced Park Assist Objects Burst Group 1 Protected : MAC";
BA_ "SignalLongName" SG_ 529 AE44OBG1P_FCnt "Advanced Park Assist Objects Burst Group 1 Protected : Freshness Counter";
BA_ "SignalLongName" SG_ 529 AE44OBG1P_PstnP2_X7 "Advanced Park Assist Objects Burst Group 1 Protected : Position P2_X 7";
BA_ "SignalLongName" SG_ 529 AE44OBG1P_BrstID "Advanced Park Assist Objects Burst Group 1 Protected : Burst ID";
BA_ "SignalLongName" SG_ 529 AE44OBG1P_PstnP1_X7 "Advanced Park Assist Objects Burst Group 1 Protected : Position P1_X 7";
BA_ "SignalLongName" SG_ 529 AE44OBG1P_PstnP2_X5 "Advanced Park Assist Objects Burst Group 1 Protected : Position P2_X 5";
BA_ "SignalLongName" SG_ 529 AE44OBG1P_PstnP1_Y7 "Advanced Park Assist Objects Burst Group 1 Protected : Position P1_Y 7";
BA_ "SignalLongName" SG_ 529 AE44OBG1P_PstnP1_X6 "Advanced Park Assist Objects Burst Group 1 Protected : Position P1_X 6";
BA_ "SignalLongName" SG_ 529 AE44OBG1P_PstnP2_Y3 "Advanced Park Assist Objects Burst Group 1 Protected : Position P2_Y 3";
BA_ "SignalLongName" SG_ 529 AE44OBG1P_PstnP1_X1 "Advanced Park Assist Objects Burst Group 1 Protected : Position P1_X 1";
BA_ "SignalLongName" SG_ 529 AE44OBG1P_PstnP1_Y2 "Advanced Park Assist Objects Burst Group 1 Protected : Position P1_Y 2";
BA_ "SignalLongName" SG_ 529 AE44OBG1P_PstnP2_Y7 "Advanced Park Assist Objects Burst Group 1 Protected : Position P2_Y 7";
BA_ "SignalLongName" SG_ 529 AE44OBG1P_PstnP1_Y1 "Advanced Park Assist Objects Burst Group 1 Protected : Position P1_Y 1";
BA_ "SignalLongName" SG_ 529 AE44OBG1P_PstnP2_X8 "Advanced Park Assist Objects Burst Group 1 Protected : Position P2_X 8";
BA_ "SignalLongName" SG_ 529 AE44OBG1P_PstnP1_Y6 "Advanced Park Assist Objects Burst Group 1 Protected : Position P1_Y 6";
BA_ "SignalLongName" SG_ 529 AE44OBG1P_PstnP1_X3 "Advanced Park Assist Objects Burst Group 1 Protected : Position P1_X 3";
BA_ "SignalLongName" SG_ 529 AE44OBG1P_PstnP2_Y4 "Advanced Park Assist Objects Burst Group 1 Protected : Position P2_Y 4";
BA_ "SignalLongName" SG_ 529 AE44OBG1P_PstnP1_Y5 "Advanced Park Assist Objects Burst Group 1 Protected : Position P1_Y 5";
BA_ "SignalLongName" SG_ 529 AE44OBG1P_PstnP1_Y3 "Advanced Park Assist Objects Burst Group 1 Protected : Position P1_Y 3";
BA_ "SignalLongName" SG_ 529 AE44OBG1P_PstnP1_X8 "Advanced Park Assist Objects Burst Group 1 Protected : Position P1_X 8";
BA_ "SignalLongName" SG_ 529 AE44OBG1P_PstnP2_Y6 "Advanced Park Assist Objects Burst Group 1 Protected : Position P2_Y 6";
BA_ "SignalLongName" SG_ 529 AE44OBG1P_PstnP2_X4 "Advanced Park Assist Objects Burst Group 1 Protected : Position P2_X 4";
BA_ "SignalLongName" SG_ 529 AE44OBG1P_PstnP2_Y2 "Advanced Park Assist Objects Burst Group 1 Protected : Position P2_Y 2";
BA_ "SignalLongName" SG_ 529 AE44OBG1P_PstnP2_Y5 "Advanced Park Assist Objects Burst Group 1 Protected : Position P2_Y 5";
BA_ "SignalLongName" SG_ 529 AE44OBG1P_PstnP2_Y8 "Advanced Park Assist Objects Burst Group 1 Protected : Position P2_Y 8";
BA_ "SignalLongName" SG_ 529 AE44OBG1P_PstnP1_Y8 "Advanced Park Assist Objects Burst Group 1 Protected : Position P1_Y 8";
BA_ "SignalLongName" SG_ 529 AE44OBG1P_PstnP2_X6 "Advanced Park Assist Objects Burst Group 1 Protected : Position P2_X 6";
BA_ "SignalLongName" SG_ 529 AE44OBG1P_PstnP2_X2 "Advanced Park Assist Objects Burst Group 1 Protected : Position P2_X 2";
BA_ "SignalLongName" SG_ 529 AE44OBG1P_PstnP1_X5 "Advanced Park Assist Objects Burst Group 1 Protected : Position P1_X 5";
BA_ "SignalLongName" SG_ 529 AE44OBG1P_PstnP1_X4 "Advanced Park Assist Objects Burst Group 1 Protected : Position P1_X 4";
BA_ "SignalLongName" SG_ 529 AE44OBG1P_PstnP1_Y4 "Advanced Park Assist Objects Burst Group 1 Protected : Position P1_Y 4";
BA_ "SignalLongName" SG_ 529 AE44OBG1P_PstnP2_Y1 "Advanced Park Assist Objects Burst Group 1 Protected : Position P2_Y 1";
BA_ "SignalLongName" SG_ 529 AE44OBG1P_PstnP1_X2 "Advanced Park Assist Objects Burst Group 1 Protected : Position P1_X 2";
BA_ "SignalLongName" SG_ 529 AE44OBG1P_PstnP2_X3 "Advanced Park Assist Objects Burst Group 1 Protected : Position P2_X 3";
BA_ "SignalLongName" SG_ 529 AE44OBG1P_PstnP2_X1 "Advanced Park Assist Objects Burst Group 1 Protected : Position P2_X 1";
BA_ "SignalLongName" SG_ 529 AE44OBG1P_Filler "Advanced Park Assist Objects Burst Group 1 Protected : Filler";
BA_ "SignalLongName" SG_ 529 AE44OBG1P_ARC "Advanced Park Assist Objects Burst Group 1 Protected : Alive Rolling Count";
BA_ "SignalLongName" SG_ 529 AE44OBG1P_FillerExtnd "Advanced Park Assist Objects Burst Group 1 Protected : Filler Extended";
BA_ "SignalLongName" SG_ 529 AE44OBG1P_FillerExtnd1 "Advanced Park Assist Objects Burst Group 1 Protected : Filler Extended 1";
BA_ "SignalLongName" SG_ 529 AE44OBG1P_FillerExtnd2 "Advanced Park Assist Objects Burst Group 1 Protected : Filler Extended 2";
BA_ "SignalLongName" SG_ 530 AE44OBG2P_Tol6 "Advanced Park Assist Objects Burst Group 2 Protected : Tolerance 6";
BA_ "SignalLongName" SG_ 530 AE44OBG2P_ID4 "Advanced Park Assist Objects Burst Group 2 Protected : ID 4";
BA_ "SignalLongName" SG_ 530 AE44OBG2P_BrstID "Advanced Park Assist Objects Burst Group 2 Protected : Burst ID";
BA_ "SignalLongName" SG_ 530 AE44OBG2P_Tol5 "Advanced Park Assist Objects Burst Group 2 Protected : Tolerance 5";
BA_ "SignalLongName" SG_ 530 AE44OBG2P_ID8 "Advanced Park Assist Objects Burst Group 2 Protected : ID 8";
BA_ "SignalType" SG_ 530 AE44OBG2P_Cnfd8 "ENM";
BA_ "SignalLongName" SG_ 530 AE44OBG2P_Cnfd8 "Advanced Park Assist Objects Burst Group 2 Protected : Confidence 8";
BA_ "SignalType" SG_ 530 AE44OBG2P_Typ6 "ENM";
BA_ "SignalLongName" SG_ 530 AE44OBG2P_Typ6 "Advanced Park Assist Objects Burst Group 2 Protected : Type 6";
BA_ "SignalType" SG_ 530 AE44OBG2P_Cnfd4 "ENM";
BA_ "SignalLongName" SG_ 530 AE44OBG2P_Cnfd4 "Advanced Park Assist Objects Burst Group 2 Protected : Confidence 4";
BA_ "SignalType" SG_ 530 AE44OBG2P_Hght7 "ENM";
BA_ "SignalLongName" SG_ 530 AE44OBG2P_Hght7 "Advanced Park Assist Objects Burst Group 2 Protected : Height 7";
BA_ "SignalLongName" SG_ 530 AE44OBG2P_ID2 "Advanced Park Assist Objects Burst Group 2 Protected : ID 2";
BA_ "SignalType" SG_ 530 AE44OBG2P_Hght8 "ENM";
BA_ "SignalLongName" SG_ 530 AE44OBG2P_Hght8 "Advanced Park Assist Objects Burst Group 2 Protected : Height 8";
BA_ "SignalLongName" SG_ 530 AE44OBG2P_ID1 "Advanced Park Assist Objects Burst Group 2 Protected : ID 1";
BA_ "SignalLongName" SG_ 530 AE44OBG2P_ID3 "Advanced Park Assist Objects Burst Group 2 Protected : ID 3";
BA_ "SignalType" SG_ 530 AE44OBG2P_Typ4 "ENM";
BA_ "SignalLongName" SG_ 530 AE44OBG2P_Typ4 "Advanced Park Assist Objects Burst Group 2 Protected : Type 4";
BA_ "SignalType" SG_ 530 AE44OBG2P_Cnfd1 "ENM";
BA_ "SignalLongName" SG_ 530 AE44OBG2P_Cnfd1 "Advanced Park Assist Objects Burst Group 2 Protected : Confidence 1";
BA_ "SignalLongName" SG_ 530 AE44OBG2P_Tol3 "Advanced Park Assist Objects Burst Group 2 Protected : Tolerance 3";
BA_ "SignalType" SG_ 530 AE44OBG2P_Cnfd6 "ENM";
BA_ "SignalLongName" SG_ 530 AE44OBG2P_Cnfd6 "Advanced Park Assist Objects Burst Group 2 Protected : Confidence 6";
BA_ "SignalLongName" SG_ 530 AE44OBG2P_Tol7 "Advanced Park Assist Objects Burst Group 2 Protected : Tolerance 7";
BA_ "SignalType" SG_ 530 AE44OBG2P_Typ2 "ENM";
BA_ "SignalLongName" SG_ 530 AE44OBG2P_Typ2 "Advanced Park Assist Objects Burst Group 2 Protected : Type 2";
BA_ "SignalType" SG_ 530 AE44OBG2P_Cnfd3 "ENM";
BA_ "SignalLongName" SG_ 530 AE44OBG2P_Cnfd3 "Advanced Park Assist Objects Burst Group 2 Protected : Confidence 3";
BA_ "SignalLongName" SG_ 530 AE44OBG2P_ID5 "Advanced Park Assist Objects Burst Group 2 Protected : ID 5";
BA_ "SignalType" SG_ 530 AE44OBG2P_Hght5 "ENM";
BA_ "SignalLongName" SG_ 530 AE44OBG2P_Hght5 "Advanced Park Assist Objects Burst Group 2 Protected : Height 5";
BA_ "SignalType" SG_ 530 AE44OBG2P_Hght4 "ENM";
BA_ "SignalLongName" SG_ 530 AE44OBG2P_Hght4 "Advanced Park Assist Objects Burst Group 2 Protected : Height 4";
BA_ "SignalType" SG_ 530 AE44OBG2P_Cnfd5 "ENM";
BA_ "SignalLongName" SG_ 530 AE44OBG2P_Cnfd5 "Advanced Park Assist Objects Burst Group 2 Protected : Confidence 5";
BA_ "SignalType" SG_ 530 AE44OBG2P_Hght2 "ENM";
BA_ "SignalLongName" SG_ 530 AE44OBG2P_Hght2 "Advanced Park Assist Objects Burst Group 2 Protected : Height 2";
BA_ "SignalLongName" SG_ 530 AE44OBG2P_Tol4 "Advanced Park Assist Objects Burst Group 2 Protected : Tolerance 4";
BA_ "SignalType" SG_ 530 AE44OBG2P_Typ3 "ENM";
BA_ "SignalLongName" SG_ 530 AE44OBG2P_Typ3 "Advanced Park Assist Objects Burst Group 2 Protected : Type 3";
BA_ "SignalLongName" SG_ 530 AE44OBG2P_Tol8 "Advanced Park Assist Objects Burst Group 2 Protected : Tolerance 8";
BA_ "SignalType" SG_ 530 AE44OBG2P_Cnfd7 "ENM";
BA_ "SignalLongName" SG_ 530 AE44OBG2P_Cnfd7 "Advanced Park Assist Objects Burst Group 2 Protected : Confidence 7";
BA_ "SignalLongName" SG_ 530 AE44OBG2P_Tol2 "Advanced Park Assist Objects Burst Group 2 Protected : Tolerance 2";
BA_ "SignalType" SG_ 530 AE44OBG2P_Typ1 "ENM";
BA_ "SignalLongName" SG_ 530 AE44OBG2P_Typ1 "Advanced Park Assist Objects Burst Group 2 Protected : Type 1";
BA_ "SignalType" SG_ 530 AE44OBG2P_Typ5 "ENM";
BA_ "SignalLongName" SG_ 530 AE44OBG2P_Typ5 "Advanced Park Assist Objects Burst Group 2 Protected : Type 5";
BA_ "SignalType" SG_ 530 AE44OBG2P_Hght3 "ENM";
BA_ "SignalLongName" SG_ 530 AE44OBG2P_Hght3 "Advanced Park Assist Objects Burst Group 2 Protected : Height 3";
BA_ "SignalLongName" SG_ 530 AE44OBG2P_ID6 "Advanced Park Assist Objects Burst Group 2 Protected : ID 6";
BA_ "SignalLongName" SG_ 530 AE44OBG2P_Tol1 "Advanced Park Assist Objects Burst Group 2 Protected : Tolerance 1";
BA_ "SignalType" SG_ 530 AE44OBG2P_Cnfd2 "ENM";
BA_ "SignalLongName" SG_ 530 AE44OBG2P_Cnfd2 "Advanced Park Assist Objects Burst Group 2 Protected : Confidence 2";
BA_ "SignalType" SG_ 530 AE44OBG2P_Typ7 "ENM";
BA_ "SignalLongName" SG_ 530 AE44OBG2P_Typ7 "Advanced Park Assist Objects Burst Group 2 Protected : Type 7";
BA_ "SignalType" SG_ 530 AE44OBG2P_Hght6 "ENM";
BA_ "SignalLongName" SG_ 530 AE44OBG2P_Hght6 "Advanced Park Assist Objects Burst Group 2 Protected : Height 6";
BA_ "SignalType" SG_ 530 AE44OBG2P_Typ8 "ENM";
BA_ "SignalLongName" SG_ 530 AE44OBG2P_Typ8 "Advanced Park Assist Objects Burst Group 2 Protected : Type 8";
BA_ "SignalLongName" SG_ 530 AE44OBG2P_ID7 "Advanced Park Assist Objects Burst Group 2 Protected : ID 7";
BA_ "SignalType" SG_ 530 AE44OBG2P_Hght1 "ENM";
BA_ "SignalLongName" SG_ 530 AE44OBG2P_Hght1 "Advanced Park Assist Objects Burst Group 2 Protected : Height 1";
BA_ "SignalLongName" SG_ 530 AE44OBG2P_Filler "Advanced Park Assist Objects Burst Group 2 Protected : Filler";
BA_ "SignalLongName" SG_ 925 AE44Sts_PCSM "AE44 Status Protected Counter Sync Message";
BA_ "SignalLongName" SG_ 525 AE44SP_MAC "AE44 Status Protected : MAC";
BA_ "SignalLongName" SG_ 525 AE44SP_FCnt "AE44 Status Protected : Freshness Counter";
BA_ "SignalLongName" SG_ 525 AE44SP_AE44StopDistAuth "AE44 Status Protected : Advanced Park Assist Stop Distance Authenticated";
BA_ "SignalLongName" SG_ 525 AE44SP_AE44MaxVelAuth "AE44 Status Protected : Advanced Park Assist Maximum Velocity Authenticated";
BA_ "SignalType" SG_ 525 AE44SP_AE44StsAuth "ENM";
BA_ "SignalLongName" SG_ 525 AE44SP_AE44StsAuth "AE44 Status Protected : Advanced Park Assist Status Authenticated";
BA_ "SignalLongName" SG_ 525 AE44SP_ARC "AE44 Status Protected : Alive Rolling Count";
BA_ "SignalType" SG_ 525 AE44SP_AE44TransRngReqAuth "ENM";
BA_ "SignalLongName" SG_ 525 AE44SP_AE44TransRngReqAuth "AE44 Status Protected : Advanced Park Assist Transmission Range Request Authenticated";
BA_ "SignalType" SG_ 525 AE44SP_AE44TransRngActvnReqdAuth "ENM";
BA_ "SignalLongName" SG_ 525 AE44SP_AE44TransRngActvnReqdAuth "AE44 Status Protected : Advanced Park Assist Transmission Range Activation Requested Authenticated";
BA_ "SignalType" SG_ 2147745810 Sig0224 "ENM";
BA_ "SignalLongName" SG_ 2147745810 Sig0224 "Signal0033";
BA_ "SignalType" SG_ 2147745811 Sig0304 "ENM";
BA_ "SignalLongName" SG_ 2147745811 Sig0304 "Signal0034";
BA_ "SignalLongName" SG_ 1393 ActvSftyOprtrCrtclNtfns_PCSM "Active Safety Operator Critical Notifications Protected Counter Sync Message";
BA_ "SignalLongName" SG_ 1325 ASOCNP_MAC "Active Safety Operator Critical Notifications Protected : MAC";
BA_ "SignalLongName" SG_ 1325 ASOCNP_FCnt "Active Safety Operator Critical Notifications Protected : Freshness Counter";
BA_ "SignalLongName" SG_ 1325 ASOCNP_Filler "Active Safety Operator Critical Notifications Protected : Filler";
BA_ "SignalType" SG_ 1325 SuprRmtPrkPwrModeReq "ENM";
BA_ "SignalLongName" SG_ 1325 SuprRmtPrkPwrModeReq "Active Safety Operator Critical Notifications Protected : Supervised Remote Parking Power Mode Request";
BA_ "SignalType" SG_ 1325 SuprRmtPrkDrLckReq "ENM";
BA_ "SignalLongName" SG_ 1325 SuprRmtPrkDrLckReq "Active Safety Operator Critical Notifications Protected : Supervised Remote Parking Door Lock Request";
BA_ "SignalLongName" SG_ 1325 ASOCNP_ARC "Active Safety Operator Critical Notifications Protected : Alive Rolling Count";
BA_ "SignalType" SG_ 1325 ASOCNP_LKATakeStrgIndOnAuth "ENM";
BA_ "SignalLongName" SG_ 1325 ASOCNP_LKATakeStrgIndOnAuth "Active Safety Operator Critical Notifications Protected : Lane Keep Assist Take Steering Indication On Authenticated";
BA_ "SignalLongName" SG_ 229 Sig0115 "Signal0053";
BA_ "SignalLongName" SG_ 229 Sig0114 "Signal0055";
BA_ "SignalLongName" SG_ 229 Sig0117 "Signal0059";
BA_ "SignalType" SG_ 229 Sig0116 "ENM";
BA_ "SignalLongName" SG_ 229 Sig0116 "Signal0054";
BA_ "SignalLongName" SG_ 229 Sig0118 "Signal0056";
BA_ "SignalLongName" SG_ 229 Sig0119 "Signal0057";
BA_ "SignalLongName" SG_ 229 Sig0120 "Signal0058";
BA_ "SignalLongName" SG_ 229 Sig0121 "Signal0060";
BA_ "SignalLongName" SG_ 229 Sig0122 "Signal0061";
BA_ "SignalLongName" SG_ 229 Sig0123 "Signal0062";
BA_ "SignalLongName" SG_ 229 Sig0124 "Signal0063";
BA_ "SignalType" SG_ 229 Sig0125 "ENM";
BA_ "SignalLongName" SG_ 229 Sig0125 "Signal0064";
BA_ "SignalType" SG_ 229 Sig0129 "ENM";
BA_ "SignalLongName" SG_ 229 Sig0129 "Signal0068";
BA_ "SignalType" SG_ 229 Sig0128 "ENM";
BA_ "SignalLongName" SG_ 229 Sig0128 "Signal0067";
BA_ "SignalType" SG_ 229 Sig0127 "ENM";
BA_ "SignalLongName" SG_ 229 Sig0127 "Signal0066";
BA_ "SignalType" SG_ 229 Sig0126 "ENM";
BA_ "SignalLongName" SG_ 229 Sig0126 "Signal0065";
BA_ "SignalType" SG_ 229 Sig0132 "ENM";
BA_ "SignalLongName" SG_ 229 Sig0132 "Signal0071";
BA_ "SignalType" SG_ 229 Sig0131 "ENM";
BA_ "SignalLongName" SG_ 229 Sig0131 "Signal0070";
BA_ "SignalType" SG_ 229 Sig0130 "ENM";
BA_ "SignalLongName" SG_ 229 Sig0130 "Signal0069";
BA_ "SignalLongName" SG_ 229 Sig0133 "Signal0072";
BA_ "SignalLongName" SG_ 229 Sig0135 "Signal0074";
BA_ "SignalLongName" SG_ 229 Sig0134 "Signal0073";
BA_ "SignalLongName" SG_ 229 Sig0136 "Signal0075";
BA_ "SignalType" SG_ 229 Sig0139 "ENM";
BA_ "SignalLongName" SG_ 229 Sig0139 "Signal0078";
BA_ "SignalType" SG_ 229 Sig0138 "ENM";
BA_ "SignalLongName" SG_ 229 Sig0138 "Signal0077";
BA_ "SignalType" SG_ 229 Sig0137 "ENM";
BA_ "SignalLongName" SG_ 229 Sig0137 "Signal0076";
BA_ "SignalLongName" SG_ 229 Sig0141 "Signal0092";
BA_ "SignalType" SG_ 229 Sig0140 "ENM";
BA_ "SignalLongName" SG_ 229 Sig0140 "Signal0079";
BA_ "SignalLongName" SG_ 229 Sig0142 "Signal0093";
BA_ "SignalLongName" SG_ 229 Sig0144 "Signal0095";
BA_ "SignalLongName" SG_ 229 Sig0143 "Signal0094";
BA_ "SignalType" SG_ 229 Sig0145 "ENM";
BA_ "SignalLongName" SG_ 229 Sig0145 "Signal0088";
BA_ "SignalLongName" SG_ 229 Sig0149 "Signal0080";
BA_ "SignalType" SG_ 229 Sig0148 "ENM";
BA_ "SignalLongName" SG_ 229 Sig0148 "Signal0091";
BA_ "SignalType" SG_ 229 Sig0147 "ENM";
BA_ "SignalLongName" SG_ 229 Sig0147 "Signal0090";
BA_ "SignalType" SG_ 229 Sig0146 "ENM";
BA_ "SignalLongName" SG_ 229 Sig0146 "Signal0089";
BA_ "SignalLongName" SG_ 229 Sig0151 "Signal0082";
BA_ "SignalType" SG_ 229 Sig0150 "ENM";
BA_ "SignalLongName" SG_ 229 Sig0150 "Signal0081";
BA_ "SignalType" SG_ 229 Sig0152 "ENM";
BA_ "SignalLongName" SG_ 229 Sig0152 "Signal0083";
BA_ "SignalLongName" SG_ 229 Sig0153 "Signal0084";
BA_ "SignalLongName" SG_ 229 Sig0155 "Signal0086";
BA_ "SignalType" SG_ 229 Sig0154 "ENM";
BA_ "SignalLongName" SG_ 229 Sig0154 "Signal0085";
BA_ "SignalType" SG_ 229 Sig0158 "ENM";
BA_ "SignalLongName" SG_ 229 Sig0158 "Signal0097";
BA_ "SignalType" SG_ 229 Sig0157 "ENM";
BA_ "SignalLongName" SG_ 229 Sig0157 "Signal0096";
BA_ "SignalType" SG_ 229 Sig0156 "ENM";
BA_ "SignalLongName" SG_ 229 Sig0156 "Signal0087";
BA_ "SignalType" SG_ 229 Sig0160 "ENM";
BA_ "SignalLongName" SG_ 229 Sig0160 "Signal0099";
BA_ "SignalType" SG_ 229 Sig0159 "ENM";
BA_ "SignalLongName" SG_ 229 Sig0159 "Signal0098";
BA_ "SignalLongName" SG_ 229 Sig0161 "Signal0100";
BA_ "SignalLongName" SG_ 229 Sig0163 "Signal0102";
BA_ "SignalLongName" SG_ 229 Sig0162 "Signal0101";
BA_ "SignalLongName" SG_ 229 Sig0164 "Signal0103";
BA_ "SignalLongName" SG_ 229 Sig0165 "Signal0104";
BA_ "SignalLongName" SG_ 229 Sig0166 "Signal0105";
BA_ "SignalLongName" SG_ 229 Sig0167 "Signal0106";
BA_ "SignalLongName" SG_ 229 Sig0168 "Signal0107";
BA_ "SignalLongName" SG_ 195 Sig0170 "Signal0108";
BA_ "SignalLongName" SG_ 195 Sig0169 "Signal0110";
BA_ "SignalLongName" SG_ 195 Sig0172 "Signal0111";
BA_ "SignalType" SG_ 195 Sig0171 "ENM";
BA_ "SignalLongName" SG_ 195 Sig0171 "Signal0109";
BA_ "SignalLongName" SG_ 195 Sig0173 "Signal0112";
BA_ "SignalLongName" SG_ 195 Sig0174 "Signal0113";
BA_ "SignalLongName" SG_ 195 Sig0175 "Signal0114";
BA_ "SignalLongName" SG_ 195 Sig0176 "Signal0115";
BA_ "SignalLongName" SG_ 195 Sig0177 "Signal0116";
BA_ "SignalLongName" SG_ 195 Sig0178 "Signal0117";
BA_ "SignalLongName" SG_ 195 Sig0179 "Signal0118";
BA_ "SignalType" SG_ 195 Sig0180 "ENM";
BA_ "SignalLongName" SG_ 195 Sig0180 "Signal0119";
BA_ "SignalType" SG_ 195 Sig0184 "ENM";
BA_ "SignalLongName" SG_ 195 Sig0184 "Signal0123";
BA_ "SignalType" SG_ 195 Sig0183 "ENM";
BA_ "SignalLongName" SG_ 195 Sig0183 "Signal0122";
BA_ "SignalType" SG_ 195 Sig0182 "ENM";
BA_ "SignalLongName" SG_ 195 Sig0182 "Signal0121";
BA_ "SignalType" SG_ 195 Sig0181 "ENM";
BA_ "SignalLongName" SG_ 195 Sig0181 "Signal0120";
BA_ "SignalType" SG_ 195 Sig0187 "ENM";
BA_ "SignalLongName" SG_ 195 Sig0187 "Signal0126";
BA_ "SignalType" SG_ 195 Sig0186 "ENM";
BA_ "SignalLongName" SG_ 195 Sig0186 "Signal0125";
BA_ "SignalType" SG_ 195 Sig0185 "ENM";
BA_ "SignalLongName" SG_ 195 Sig0185 "Signal0124";
BA_ "SignalLongName" SG_ 195 Sig0188 "Signal0127";
BA_ "SignalLongName" SG_ 195 Sig0190 "Signal0129";
BA_ "SignalLongName" SG_ 195 Sig0189 "Signal0128";
BA_ "SignalLongName" SG_ 195 Sig0191 "Signal0130";
BA_ "SignalType" SG_ 195 Sig0194 "ENM";
BA_ "SignalLongName" SG_ 195 Sig0194 "Signal0133";
BA_ "SignalType" SG_ 195 Sig0193 "ENM";
BA_ "SignalLongName" SG_ 195 Sig0193 "Signal0132";
BA_ "SignalType" SG_ 195 Sig0192 "ENM";
BA_ "SignalLongName" SG_ 195 Sig0192 "Signal0131";
BA_ "SignalLongName" SG_ 195 Sig0196 "Signal0147";
BA_ "SignalType" SG_ 195 Sig0195 "ENM";
BA_ "SignalLongName" SG_ 195 Sig0195 "Signal0134";
BA_ "SignalLongName" SG_ 195 Sig0197 "Signal0148";
BA_ "SignalLongName" SG_ 195 Sig0199 "Signal0150";
BA_ "SignalLongName" SG_ 195 Sig0198 "Signal0149";
BA_ "SignalType" SG_ 195 Sig0200 "ENM";
BA_ "SignalLongName" SG_ 195 Sig0200 "Signal0143";
BA_ "SignalLongName" SG_ 195 Sig0204 "Signal0135";
BA_ "SignalType" SG_ 195 Sig0203 "ENM";
BA_ "SignalLongName" SG_ 195 Sig0203 "Signal0146";
BA_ "SignalType" SG_ 195 Sig0202 "ENM";
BA_ "SignalLongName" SG_ 195 Sig0202 "Signal0145";
BA_ "SignalType" SG_ 195 Sig0201 "ENM";
BA_ "SignalLongName" SG_ 195 Sig0201 "Signal0144";
BA_ "SignalLongName" SG_ 195 Sig0206 "Signal0137";
BA_ "SignalType" SG_ 195 Sig0205 "ENM";
BA_ "SignalLongName" SG_ 195 Sig0205 "Signal0136";
BA_ "SignalType" SG_ 195 Sig0207 "ENM";
BA_ "SignalLongName" SG_ 195 Sig0207 "Signal0138";
BA_ "SignalLongName" SG_ 195 Sig0208 "Signal0139";
BA_ "SignalLongName" SG_ 195 Sig0210 "Signal0141";
BA_ "SignalType" SG_ 195 Sig0209 "ENM";
BA_ "SignalLongName" SG_ 195 Sig0209 "Signal0140";
BA_ "SignalType" SG_ 195 Sig0213 "ENM";
BA_ "SignalLongName" SG_ 195 Sig0213 "Signal0152";
BA_ "SignalType" SG_ 195 Sig0212 "ENM";
BA_ "SignalLongName" SG_ 195 Sig0212 "Signal0151";
BA_ "SignalType" SG_ 195 Sig0211 "ENM";
BA_ "SignalLongName" SG_ 195 Sig0211 "Signal0142";
BA_ "SignalType" SG_ 195 Sig0215 "ENM";
BA_ "SignalLongName" SG_ 195 Sig0215 "Signal0154";
BA_ "SignalType" SG_ 195 Sig0214 "ENM";
BA_ "SignalLongName" SG_ 195 Sig0214 "Signal0153";
BA_ "SignalLongName" SG_ 195 Sig0216 "Signal0155";
BA_ "SignalLongName" SG_ 195 Sig0218 "Signal0157";
BA_ "SignalLongName" SG_ 195 Sig0217 "Signal0156";
BA_ "SignalLongName" SG_ 195 Sig0219 "Signal0158";
BA_ "SignalLongName" SG_ 195 Sig0220 "Signal0159";
BA_ "SignalLongName" SG_ 195 Sig0221 "Signal0160";
BA_ "SignalLongName" SG_ 195 Sig0222 "Signal0161";
BA_ "SignalLongName" SG_ 195 Sig0223 "Signal0162";
BA_ "SignalLongName" SG_ 924 ArbdASILActvSftyStrgReq_PCSM "Arbitrated ASIL Active Safety Steering Request Protected Counter Sync Message";
BA_ "SignalLongName" SG_ 625 AAASSRP_MAC "Arbitrated ASIL Active Safety Steering Request Protected : MAC";
BA_ "SignalLongName" SG_ 625 AAASSRP_FCnt "Arbitrated ASIL Active Safety Steering Request Protected : Freshness Counter";
BA_ "SignalLongName" SG_ 625 AAASSRP_StrgReqAngValAuth "Arbitrated ASIL Active Safety Steering Request Protected : Steering Request Angle Value Authenticated";
BA_ "SignalType" SG_ 625 AAASSRP_StrgReqArbdFtrAuth "ENM";
BA_ "SignalLongName" SG_ 625 AAASSRP_StrgReqArbdFtrAuth "Arbitrated ASIL Active Safety Steering Request Protected : Steering Request Arbitrated Feature Authenticated";
BA_ "SignalLongName" SG_ 625 AAASSRP_StrgReqTrqValAuth "Arbitrated ASIL Active Safety Steering Request Protected : Steering Request Torque Value Authenticated";
BA_ "SignalType" SG_ 625 AAASSRP_StrgReqStsAuth "ENM";
BA_ "SignalLongName" SG_ 625 AAASSRP_StrgReqStsAuth "Arbitrated ASIL Active Safety Steering Request Protected : Steering Request Status Authenticated";
BA_ "SignalLongName" SG_ 625 AAASSRP_ARC "Arbitrated ASIL Active Safety Steering Request Protected : Alive Rolling Count";
BA_ "SignalType" SG_ 625 LnFllwgRrStrgInhbAuth "ENM";
BA_ "SignalLongName" SG_ 625 LnFllwgRrStrgInhbAuth "Arbitrated ASIL Active Safety Steering Request Protected : Lane Following Rear Steering Inhibit Authenticated";
BA_ "SignalType" SG_ 625 AAASSRP_StrgReqTypAuth "ENM";
BA_ "SignalLongName" SG_ 625 AAASSRP_StrgReqTypAuth "Arbitrated ASIL Active Safety Steering Request Protected : Steering Request Type Authenticated";
BA_ "SignalLongName" SG_ 521 Sig0226 "Signal0232";
BA_ "SignalLongName" SG_ 521 Sig0225 "Signal0231";
BA_ "SignalLongName" SG_ 521 Sig0227 "Signal0233";
BA_ "SignalLongName" SG_ 521 Sig0228 "Signal0234";
BA_ "SignalLongName" SG_ 521 Sig0229 "Signal0235";
BA_ "SignalLongName" SG_ 521 Sig0230 "Signal0236";
BA_ "SignalLongName" SG_ 521 Sig0233 "Signal0239";
BA_ "SignalType" SG_ 521 Sig0232 "ENM";
BA_ "SignalLongName" SG_ 521 Sig0232 "Signal0238";
BA_ "SignalType" SG_ 521 Sig0231 "ENM";
BA_ "SignalLongName" SG_ 521 Sig0231 "Signal0237";
BA_ "SignalLongName" SG_ 521 Sig0234 "Signal0240";
BA_ "SignalLongName" SG_ 521 Sig0235 "Signal0241";
BA_ "SignalLongName" SG_ 521 Sig0236 "Signal0242";
BA_ "SignalLongName" SG_ 521 Sig0237 "Signal0243";
BA_ "SignalLongName" SG_ 521 Sig0238 "Signal0244";
BA_ "SignalLongName" SG_ 521 Sig0239 "Signal0245";
BA_ "SignalLongName" SG_ 521 Sig0242 "Signal0248";
BA_ "SignalType" SG_ 521 Sig0241 "ENM";
BA_ "SignalLongName" SG_ 521 Sig0241 "Signal0247";
BA_ "SignalType" SG_ 521 Sig0240 "ENM";
BA_ "SignalLongName" SG_ 521 Sig0240 "Signal0246";
BA_ "SignalLongName" SG_ 521 Sig0243 "Signal0249";
BA_ "SignalLongName" SG_ 521 Sig0244 "Signal0250";
BA_ "SignalLongName" SG_ 521 Sig0246 "Signal0252";
BA_ "SignalType" SG_ 521 Sig0245 "ENM";
BA_ "SignalLongName" SG_ 521 Sig0245 "Signal0251";
BA_ "SignalLongName" SG_ 521 Sig0247 "Signal0253";
BA_ "SignalLongName" SG_ 521 Sig0248 "Signal0254";
BA_ "SignalLongName" SG_ 521 Sig0249 "Signal0255";
BA_ "SignalLongName" SG_ 521 Sig0250 "Signal0256";
BA_ "SignalLongName" SG_ 521 Sig0251 "Signal0257";
BA_ "SignalLongName" SG_ 521 Sig0252 "Signal0258";
BA_ "SignalLongName" SG_ 521 Sig0253 "Signal0259";
BA_ "SignalType" SG_ 521 Sig0255 "ENM";
BA_ "SignalLongName" SG_ 521 Sig0255 "Signal0261";
BA_ "SignalLongName" SG_ 521 Sig0254 "Signal0260";
BA_ "SignalLongName" SG_ 521 Sig0256 "Signal0262";
BA_ "SignalLongName" SG_ 521 Sig0257 "Signal0272";
BA_ "SignalLongName" SG_ 521 Sig0259 "Signal0264";
BA_ "SignalLongName" SG_ 521 Sig0258 "Signal0263";
BA_ "SignalLongName" SG_ 521 Sig0260 "Signal0265";
BA_ "SignalLongName" SG_ 521 Sig0261 "Signal0266";
BA_ "SignalLongName" SG_ 521 Sig0264 "Signal0269";
BA_ "SignalType" SG_ 521 Sig0263 "ENM";
BA_ "SignalLongName" SG_ 521 Sig0263 "Signal0268";
BA_ "SignalType" SG_ 521 Sig0267 "ENM";
BA_ "SignalLongName" SG_ 521 Sig0267 "Signal0273";
BA_ "SignalType" SG_ 521 Sig0266 "ENM";
BA_ "SignalLongName" SG_ 521 Sig0266 "Signal0271";
BA_ "SignalType" SG_ 521 Sig0265 "ENM";
BA_ "SignalLongName" SG_ 521 Sig0265 "Signal0270";
BA_ "SignalLongName" SG_ 521 Sig0269 "Signal0275";
BA_ "SignalLongName" SG_ 521 Sig0270 "Signal0276";
BA_ "SignalLongName" SG_ 521 Sig0271 "Signal0277";
BA_ "SignalLongName" SG_ 521 Sig0272 "Signal0278";
BA_ "SignalLongName" SG_ 521 Sig0273 "Signal0279";
BA_ "SignalLongName" SG_ 521 Sig0274 "Signal0280";
BA_ "SignalLongName" SG_ 521 Sig0275 "Signal0281";
BA_ "SignalLongName" SG_ 521 Sig0262 "Signal0267";
BA_ "SignalLongName" SG_ 521 Sig0268 "Signal0274";
BA_ "SignalLongName" SG_ 184 Sig0277 "Signal0283";
BA_ "SignalLongName" SG_ 184 Sig0276 "Signal0282";
BA_ "SignalLongName" SG_ 184 Sig0278 "Signal0284";
BA_ "SignalLongName" SG_ 184 Sig0279 "Signal0285";
BA_ "SignalLongName" SG_ 184 Sig0280 "Signal0286";
BA_ "SignalLongName" SG_ 184 Sig0281 "Signal0287";
BA_ "SignalLongName" SG_ 184 Sig0284 "Signal0290";
BA_ "SignalType" SG_ 184 Sig0283 "ENM";
BA_ "SignalLongName" SG_ 184 Sig0283 "Signal0289";
BA_ "SignalType" SG_ 184 Sig0282 "ENM";
BA_ "SignalLongName" SG_ 184 Sig0282 "Signal0288";
BA_ "SignalLongName" SG_ 184 Sig0285 "Signal0291";
BA_ "SignalLongName" SG_ 184 Sig0286 "Signal0292";
BA_ "SignalLongName" SG_ 184 Sig0287 "Signal0293";
BA_ "SignalLongName" SG_ 184 Sig0288 "Signal0294";
BA_ "SignalLongName" SG_ 184 Sig0289 "Signal0295";
BA_ "SignalLongName" SG_ 184 Sig0290 "Signal0296";
BA_ "SignalLongName" SG_ 184 Sig0293 "Signal0299";
BA_ "SignalType" SG_ 184 Sig0292 "ENM";
BA_ "SignalLongName" SG_ 184 Sig0292 "Signal0298";
BA_ "SignalType" SG_ 184 Sig0291 "ENM";
BA_ "SignalLongName" SG_ 184 Sig0291 "Signal0297";
BA_ "SignalLongName" SG_ 184 Sig0294 "Signal0300";
BA_ "SignalLongName" SG_ 184 Sig0295 "Signal0301";
BA_ "SignalLongName" SG_ 184 Sig0297 "Signal0303";
BA_ "SignalType" SG_ 184 Sig0296 "ENM";
BA_ "SignalLongName" SG_ 184 Sig0296 "Signal0302";
BA_ "SignalLongName" SG_ 184 Sig0298 "Signal0304";
BA_ "SignalLongName" SG_ 184 Sig0299 "Signal0305";
BA_ "SignalLongName" SG_ 184 Sig0300 "Signal0306";
BA_ "SignalLongName" SG_ 184 Sig0301 "Signal0307";
BA_ "SignalLongName" SG_ 184 Sig0302 "Signal0308";
BA_ "SignalLongName" SG_ 184 Sig0303 "Signal0309";
BA_ "SignalLongName" SG_ 1392 Sig0446 "Signal0350";
BA_ "SignalLongName" SG_ 612 Sig0008 "Signal0349";
BA_ "SignalLongName" SG_ 612 Sig0006 "Signal0348";
BA_ "SignalLongName" SG_ 612 Sig0002 "Signal0343";
BA_ "SignalLongName" SG_ 612 Sig0004 "Signal0345";
BA_ "SignalType" SG_ 612 Sig0003 "ENM";
BA_ "SignalLongName" SG_ 612 Sig0003 "Signal0344";
BA_ "SignalLongName" SG_ 612 Sig0007 "Signal0347";
BA_ "SignalLongName" SG_ 612 Sig0001 "Signal0342";
BA_ "SignalType" SG_ 612 Sig0005 "ENM";
BA_ "SignalLongName" SG_ 612 Sig0005 "Signal0346";
BA_ "SignalLongName" SG_ 700 AutoBrkSysMnPriInfo1_PCSM "Autonomous Brake System Main Primary Information 1 Protected Counter Sync Message";
VAL_ 2147745829 Sig0068 0 "FALSE" 1 "TRUE" ;
VAL_ 2147745830 ACP3_MCU_CAN2_ClscCANHrtBtActv 0 "FALSE" 1 "TRUE" ;
VAL_ 2147745793 Sig0094 0 "FALSE" 1 "TRUE" ;
VAL_ 2147745794 Sig0098 0 "FALSE" 1 "TRUE" ;
VAL_ 2147745808 Sig0111 0 "FALSE" 1 "TRUE" ;
VAL_ 2147745809 Sig0112 0 "FALSE" 1 "TRUE" ;
VAL_ 187 AE44CAP_AE44CtlAngReqActvAuth 0 "FALSE" 1 "TRUE" ;
VAL_ 530 AE44OBG2P_Cnfd8 0 "Highly Speculative" 1 "Speculative" 2 "Confident" 3 "Highly Confident" ;
VAL_ 530 AE44OBG2P_Typ6 0 "NoObject" 1 "Straight_0Corner" 2 "Straight_1Corner" 3 "Straight_2Corners" 4 "Point" 5 "Curbstone" 6 "Blind Area" ;
VAL_ 530 AE44OBG2P_Cnfd4 0 "Highly Speculative" 1 "Speculative" 2 "Confident" 3 "Highly Confident" ;
VAL_ 530 AE44OBG2P_Hght7 0 "Unknown" 1 "Traversable" 2 "High_Object" 3 "Low_Object" ;
VAL_ 530 AE44OBG2P_Hght8 0 "Unknown" 1 "Traversable" 2 "High_Object" 3 "Low_Object" ;
VAL_ 530 AE44OBG2P_Typ4 0 "NoObject" 1 "Straight_0Corner" 2 "Straight_1Corner" 3 "Straight_2Corners" 4 "Point" 5 "Curbstone" 6 "Blind Area" ;
VAL_ 530 AE44OBG2P_Cnfd1 0 "Highly Speculative" 1 "Speculative" 2 "Confident" 3 "Highly Confident" ;
VAL_ 530 AE44OBG2P_Cnfd6 0 "Highly Speculative" 1 "Speculative" 2 "Confident" 3 "Highly Confident" ;
VAL_ 530 AE44OBG2P_Typ2 0 "NoObject" 1 "Straight_0Corner" 2 "Straight_1Corner" 3 "Straight_2Corners" 4 "Point" 5 "Curbstone" 6 "Blind Area" ;
VAL_ 530 AE44OBG2P_Cnfd3 0 "Highly Speculative" 1 "Speculative" 2 "Confident" 3 "Highly Confident" ;
VAL_ 530 AE44OBG2P_Hght5 0 "Unknown" 1 "Traversable" 2 "High_Object" 3 "Low_Object" ;
VAL_ 530 AE44OBG2P_Hght4 0 "Unknown" 1 "Traversable" 2 "High_Object" 3 "Low_Object" ;
VAL_ 530 AE44OBG2P_Cnfd5 0 "Highly Speculative" 1 "Speculative" 2 "Confident" 3 "Highly Confident" ;
VAL_ 530 AE44OBG2P_Hght2 0 "Unknown" 1 "Traversable" 2 "High_Object" 3 "Low_Object" ;
VAL_ 530 AE44OBG2P_Typ3 0 "NoObject" 1 "Straight_0Corner" 2 "Straight_1Corner" 3 "Straight_2Corners" 4 "Point" 5 "Curbstone" 6 "Blind Area" ;
VAL_ 530 AE44OBG2P_Cnfd7 0 "Highly Speculative" 1 "Speculative" 2 "Confident" 3 "Highly Confident" ;
VAL_ 530 AE44OBG2P_Typ1 0 "NoObject" 1 "Straight_0Corner" 2 "Straight_1Corner" 3 "Straight_2Corners" 4 "Point" 5 "Curbstone" 6 "Blind Area" ;
VAL_ 530 AE44OBG2P_Typ5 0 "NoObject" 1 "Straight_0Corner" 2 "Straight_1Corner" 3 "Straight_2Corners" 4 "Point" 5 "Curbstone" 6 "Blind Area" ;
VAL_ 530 AE44OBG2P_Hght3 0 "Unknown" 1 "Traversable" 2 "High_Object" 3 "Low_Object" ;
VAL_ 530 AE44OBG2P_Cnfd2 0 "Highly Speculative" 1 "Speculative" 2 "Confident" 3 "Highly Confident" ;
VAL_ 530 AE44OBG2P_Typ7 0 "NoObject" 1 "Straight_0Corner" 2 "Straight_1Corner" 3 "Straight_2Corners" 4 "Point" 5 "Curbstone" 6 "Blind Area" ;
VAL_ 530 AE44OBG2P_Hght6 0 "Unknown" 1 "Traversable" 2 "High_Object" 3 "Low_Object" ;
VAL_ 530 AE44OBG2P_Typ8 0 "NoObject" 1 "Straight_0Corner" 2 "Straight_1Corner" 3 "Straight_2Corners" 4 "Point" 5 "Curbstone" 6 "Blind Area" ;
VAL_ 530 AE44OBG2P_Hght1 0 "Unknown" 1 "Traversable" 2 "High_Object" 3 "Low_Object" ;
VAL_ 525 AE44SP_AE44StsAuth 0 "Off" 1 "Standby" 2 "Search_Phase" 3 "Exit_Park" 4 "Enabled" 5 "Guidance_Phase" 6 "Finished" 7 "Error" ;
VAL_ 525 AE44SP_AE44TransRngReqAuth 0 "No_Request" 1 "Park" 2 "Reverse" 3 "Neutral" 4 "Drive" ;
VAL_ 525 AE44SP_AE44TransRngActvnReqdAuth 0 "FALSE" 1 "TRUE" ;
VAL_ 2147745810 Sig0224 0 "FALSE" 1 "TRUE" ;
VAL_ 2147745811 Sig0304 0 "FALSE" 1 "TRUE" ;
VAL_ 1325 SuprRmtPrkPwrModeReq 0 "No Request" 1 "Off" 2 "Propulsion" ;
VAL_ 1325 SuprRmtPrkDrLckReq 0 "No Request" 1 "Lock" 2 "Unlock" ;
VAL_ 1325 ASOCNP_LKATakeStrgIndOnAuth 0 "FALSE" 1 "TRUE" ;
VAL_ 229 Sig0116 0 "FALSE" 1 "TRUE" ;
VAL_ 229 Sig0125 0 "Highly Speculative" 1 "Speculative" 2 "Confident" 3 "Highly Confident" ;
VAL_ 229 Sig0129 0 "Following" 1 "Oncoming" 2 "Following Goup" 3 "Oncoming Group" 4 "Unknown" ;
VAL_ 229 Sig0128 0 "Highly Speculative" 1 "Speculative" 2 "Confident" 3 "Highly Confident" ;
VAL_ 229 Sig0127 0 "Highly Speculative" 1 "Speculative" 2 "Confident" 3 "Highly Confident" ;
VAL_ 229 Sig0126 0 "Highly Speculative" 1 "Speculative" 2 "Confident" 3 "Highly Confident" ;
VAL_ 229 Sig0132 0 "Following" 1 "Oncoming" 2 "Following Goup" 3 "Oncoming Group" 4 "Unknown" ;
VAL_ 229 Sig0131 0 "Following" 1 "Oncoming" 2 "Following Goup" 3 "Oncoming Group" 4 "Unknown" ;
VAL_ 229 Sig0130 0 "Following" 1 "Oncoming" 2 "Following Goup" 3 "Oncoming Group" 4 "Unknown" ;
VAL_ 229 Sig0139 0 "No Object" 1 "New Object" 2 "Latent Track Not Detected This Cycle" 3 "Measured This Cycle" ;
VAL_ 229 Sig0138 0 "No Object" 1 "New Object" 2 "Latent Track Not Detected This Cycle" 3 "Measured This Cycle" ;
VAL_ 229 Sig0137 0 "No Object" 1 "New Object" 2 "Latent Track Not Detected This Cycle" 3 "Measured This Cycle" ;
VAL_ 229 Sig0140 0 "No Object" 1 "New Object" 2 "Latent Track Not Detected This Cycle" 3 "Measured This Cycle" ;
VAL_ 229 Sig0145 0 "Unknown" 1 "Host Lane" 2 "Right Lane" 3 "Left Lane" ;
VAL_ 229 Sig0148 0 "Unknown" 1 "Host Lane" 2 "Right Lane" 3 "Left Lane" ;
VAL_ 229 Sig0147 0 "Unknown" 1 "Host Lane" 2 "Right Lane" 3 "Left Lane" ;
VAL_ 229 Sig0146 0 "Unknown" 1 "Host Lane" 2 "Right Lane" 3 "Left Lane" ;
VAL_ 229 Sig0150 0 "FALSE" 1 "TRUE" ;
VAL_ 229 Sig0152 0 "FALSE" 1 "TRUE" ;
VAL_ 229 Sig0154 0 "FALSE" 1 "TRUE" ;
VAL_ 229 Sig0158 0 "UNKNOWN" 1 "4 WHEEL VEHICLE" 2 "LARGE VEHICLE" 3 "MOTORCYCLE/BICYCLE" 4 "PEDESTRIAN" 5 "FIXED OVERHEAD OBJECT" 6 "FIXED ROADSIDE OBJECT" 7 "NO OBJECT PRESENT" 8 "PEDESTRIAN STANDING OUTSIDE DANGER ZONE" 9 "PEDESTRIAN MOVING OUT OF DANGER ZONE" 10 "PEDESTRIAN MOVING INTO DANGER ZONE" 11 "CHILD CLOSE TO DANGER ZONE" 12 "CLUSTER OBJECT" ;
VAL_ 229 Sig0157 0 "UNKNOWN" 1 "4 WHEEL VEHICLE" 2 "LARGE VEHICLE" 3 "MOTORCYCLE/BICYCLE" 4 "PEDESTRIAN" 5 "FIXED OVERHEAD OBJECT" 6 "FIXED ROADSIDE OBJECT" 7 "NO OBJECT PRESENT" 8 "PEDESTRIAN STANDING OUTSIDE DANGER ZONE" 9 "PEDESTRIAN MOVING OUT OF DANGER ZONE" 10 "PEDESTRIAN MOVING INTO DANGER ZONE" 11 "CHILD CLOSE TO DANGER ZONE" 12 "CLUSTER OBJECT" ;
VAL_ 229 Sig0156 0 "FALSE" 1 "TRUE" ;
VAL_ 229 Sig0160 0 "UNKNOWN" 1 "4 WHEEL VEHICLE" 2 "LARGE VEHICLE" 3 "MOTORCYCLE/BICYCLE" 4 "PEDESTRIAN" 5 "FIXED OVERHEAD OBJECT" 6 "FIXED ROADSIDE OBJECT" 7 "NO OBJECT PRESENT" 8 "PEDESTRIAN STANDING OUTSIDE DANGER ZONE" 9 "PEDESTRIAN MOVING OUT OF DANGER ZONE" 10 "PEDESTRIAN MOVING INTO DANGER ZONE" 11 "CHILD CLOSE TO DANGER ZONE" 12 "CLUSTER OBJECT" ;
VAL_ 229 Sig0159 0 "UNKNOWN" 1 "4 WHEEL VEHICLE" 2 "LARGE VEHICLE" 3 "MOTORCYCLE/BICYCLE" 4 "PEDESTRIAN" 5 "FIXED OVERHEAD OBJECT" 6 "FIXED ROADSIDE OBJECT" 7 "NO OBJECT PRESENT" 8 "PEDESTRIAN STANDING OUTSIDE DANGER ZONE" 9 "PEDESTRIAN MOVING OUT OF DANGER ZONE" 10 "PEDESTRIAN MOVING INTO DANGER ZONE" 11 "CHILD CLOSE TO DANGER ZONE" 12 "CLUSTER OBJECT" ;
VAL_ 195 Sig0171 0 "FALSE" 1 "TRUE" ;
VAL_ 195 Sig0180 0 "Highly Speculative" 1 "Speculative" 2 "Confident" 3 "Highly Confident" ;
VAL_ 195 Sig0184 0 "Following" 1 "Oncoming" 2 "Following Goup" 3 "Oncoming Group" 4 "Unknown" ;
VAL_ 195 Sig0183 0 "Highly Speculative" 1 "Speculative" 2 "Confident" 3 "Highly Confident" ;
VAL_ 195 Sig0182 0 "Highly Speculative" 1 "Speculative" 2 "Confident" 3 "Highly Confident" ;
VAL_ 195 Sig0181 0 "Highly Speculative" 1 "Speculative" 2 "Confident" 3 "Highly Confident" ;
VAL_ 195 Sig0187 0 "Following" 1 "Oncoming" 2 "Following Goup" 3 "Oncoming Group" 4 "Unknown" ;
VAL_ 195 Sig0186 0 "Following" 1 "Oncoming" 2 "Following Goup" 3 "Oncoming Group" 4 "Unknown" ;
VAL_ 195 Sig0185 0 "Following" 1 "Oncoming" 2 "Following Goup" 3 "Oncoming Group" 4 "Unknown" ;
VAL_ 195 Sig0194 0 "No Object" 1 "New Object" 2 "Latent Track Not Detected This Cycle" 3 "Measured This Cycle" ;
VAL_ 195 Sig0193 0 "No Object" 1 "New Object" 2 "Latent Track Not Detected This Cycle" 3 "Measured This Cycle" ;
VAL_ 195 Sig0192 0 "No Object" 1 "New Object" 2 "Latent Track Not Detected This Cycle" 3 "Measured This Cycle" ;
VAL_ 195 Sig0195 0 "No Object" 1 "New Object" 2 "Latent Track Not Detected This Cycle" 3 "Measured This Cycle" ;
VAL_ 195 Sig0200 0 "Unknown" 1 "Host Lane" 2 "Right Lane" 3 "Left Lane" ;
VAL_ 195 Sig0203 0 "Unknown" 1 "Host Lane" 2 "Right Lane" 3 "Left Lane" ;
VAL_ 195 Sig0202 0 "Unknown" 1 "Host Lane" 2 "Right Lane" 3 "Left Lane" ;
VAL_ 195 Sig0201 0 "Unknown" 1 "Host Lane" 2 "Right Lane" 3 "Left Lane" ;
VAL_ 195 Sig0205 0 "FALSE" 1 "TRUE" ;
VAL_ 195 Sig0207 0 "FALSE" 1 "TRUE" ;
VAL_ 195 Sig0209 0 "FALSE" 1 "TRUE" ;
VAL_ 195 Sig0213 0 "UNKNOWN" 1 "4 WHEEL VEHICLE" 2 "LARGE VEHICLE" 3 "MOTORCYCLE/BICYCLE" 4 "PEDESTRIAN" 5 "FIXED OVERHEAD OBJECT" 6 "FIXED ROADSIDE OBJECT" 7 "NO OBJECT PRESENT" 8 "PEDESTRIAN STANDING OUTSIDE DANGER ZONE" 9 "PEDESTRIAN MOVING OUT OF DANGER ZONE" 10 "PEDESTRIAN MOVING INTO DANGER ZONE" 11 "CHILD CLOSE TO DANGER ZONE" 12 "CLUSTER OBJECT" ;
VAL_ 195 Sig0212 0 "UNKNOWN" 1 "4 WHEEL VEHICLE" 2 "LARGE VEHICLE" 3 "MOTORCYCLE/BICYCLE" 4 "PEDESTRIAN" 5 "FIXED OVERHEAD OBJECT" 6 "FIXED ROADSIDE OBJECT" 7 "NO OBJECT PRESENT" 8 "PEDESTRIAN STANDING OUTSIDE DANGER ZONE" 9 "PEDESTRIAN MOVING OUT OF DANGER ZONE" 10 "PEDESTRIAN MOVING INTO DANGER ZONE" 11 "CHILD CLOSE TO DANGER ZONE" 12 "CLUSTER OBJECT" ;
VAL_ 195 Sig0211 0 "FALSE" 1 "TRUE" ;
VAL_ 195 Sig0215 0 "UNKNOWN" 1 "4 WHEEL VEHICLE" 2 "LARGE VEHICLE" 3 "MOTORCYCLE/BICYCLE" 4 "PEDESTRIAN" 5 "FIXED OVERHEAD OBJECT" 6 "FIXED ROADSIDE OBJECT" 7 "NO OBJECT PRESENT" 8 "PEDESTRIAN STANDING OUTSIDE DANGER ZONE" 9 "PEDESTRIAN MOVING OUT OF DANGER ZONE" 10 "PEDESTRIAN MOVING INTO DANGER ZONE" 11 "CHILD CLOSE TO DANGER ZONE" 12 "CLUSTER OBJECT" ;
VAL_ 195 Sig0214 0 "UNKNOWN" 1 "4 WHEEL VEHICLE" 2 "LARGE VEHICLE" 3 "MOTORCYCLE/BICYCLE" 4 "PEDESTRIAN" 5 "FIXED OVERHEAD OBJECT" 6 "FIXED ROADSIDE OBJECT" 7 "NO OBJECT PRESENT" 8 "PEDESTRIAN STANDING OUTSIDE DANGER ZONE" 9 "PEDESTRIAN MOVING OUT OF DANGER ZONE" 10 "PEDESTRIAN MOVING INTO DANGER ZONE" 11 "CHILD CLOSE TO DANGER ZONE" 12 "CLUSTER OBJECT" ;
VAL_ 625 AAASSRP_StrgReqArbdFtrAuth 0 "None" 1 "Collision Avoidance Steeering" 2 "Traffic Jam Assist" 3 "Lane Centering and Control" 4 "Hands-On Lane Following" 5 "Steering Angle Assist" 6 "Lane Keep Assist" 7 "Lane Change on Demand" 8 "Lateral Collision Prevention" ;
VAL_ 625 AAASSRP_StrgReqStsAuth 0 "Unknown" 1 "Active" 2 "Inactive" ;
VAL_ 625 LnFllwgRrStrgInhbAuth 0 "FALSE" 1 "TRUE" ;
VAL_ 625 AAASSRP_StrgReqTypAuth 0 "Torque" 1 "Angle" ;
VAL_ 521 Sig0232 0 "Undecided" 1 "Solid" 2 "Dashed" 3 "Road Edge" 4 "Double Line" 5 "Botts Dots" 6 "Virtual" 7 "Triple Line" ;
VAL_ 521 Sig0231 0 "Very Low Quality" 1 "Low Quality" 2 "Prediction" 3 "High Quality" ;
VAL_ 521 Sig0241 0 "Undecided" 1 "Solid" 2 "Dashed" 3 "Road Edge" 4 "Double Line" 5 "Botts Dots" 6 "Virtual" 7 "Triple Line" ;
VAL_ 521 Sig0240 0 "Very Low Quality" 1 "Low Quality" 2 "Prediction" 3 "High Quality" ;
VAL_ 521 Sig0245 0 "No Object" 1 "New Object" 2 "Latent Track Not Detected this Cycle" 3 "Measured this Cycle" ;
VAL_ 521 Sig0255 0 "Unknown" 1 "Yaw" 2 "Horizon" 3 "Both" ;
VAL_ 521 Sig0263 0 "Unknown" 1 "Initializing" 2 "Inactive" 3 "Active" 4 "Programing" 5 "Reserved 1" 6 "Reserved 2" 7 "Failed" ;
VAL_ 521 Sig0267 0 "No Object" 1 "New Object" 2 "Latent Track Not Detected this Cycle" 3 "Measured this Cycle" ;
VAL_ 521 Sig0266 0 "FALSE" 1 "TRUE" ;
VAL_ 521 Sig0265 0 "FALSE" 1 "TRUE" ;
VAL_ 184 Sig0283 0 "Undecided" 1 "Solid" 2 "Dashed" 3 "Road Edge" 4 "Double Line" 5 "Botts Dots" 6 "Virtual" 7 "Triple Line" ;
VAL_ 184 Sig0282 0 "Very Low Quality" 1 "Low Quality" 2 "Prediction" 3 "High Quality" ;
VAL_ 184 Sig0292 0 "Undecided" 1 "Solid" 2 "Dashed" 3 "Road Edge" 4 "Double Line" 5 "Botts Dots" 6 "Virtual" 7 "Triple Line" ;
VAL_ 184 Sig0291 0 "Very Low Quality" 1 "Low Quality" 2 "Prediction" 3 "High Quality" ;
VAL_ 184 Sig0296 0 "No Object" 1 "New Object" 2 "Latent Track Not Detected this Cycle" 3 "Measured this Cycle" ;
VAL_ 612 Sig0003 0 "FALSE" 1 "TRUE" ;
VAL_ 612 Sig0005 0 "FALSE" 1 "TRUE" ;
